[part 10 of 23: package /Cluster]
AUTOSAR XML (schema 4-3-0)
package /Cluster  (continued)
  7 x lin cluster, all with baudrate=19200, protocol-name=LIN, protocol-version=2.0:  (continued)
    Klima_LIN1
      lin physical channel CHNL: comm-connectors=CN_Klima_LIN1
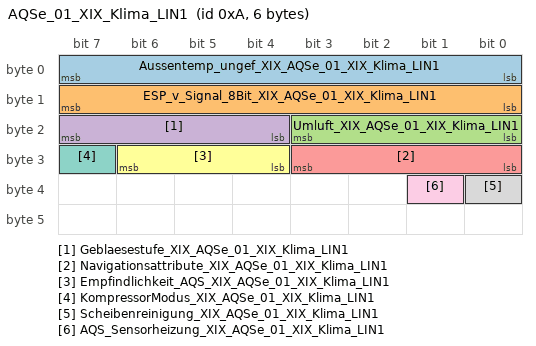
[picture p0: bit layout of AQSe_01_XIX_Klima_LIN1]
        frame AQSe_01_XIX_Klima_LIN1: id 0xA, from Klima, frame-length=6, lin-checksum=ENHANCED
          pdu AQSe_01_XIX_Klima_LIN1: length=6, unused-bit-pattern=0
            signal Aussentemp_ungef_XIX_AQSe_01_XIX_Klima_LIN1: start 0, 8 bit, little-endian, data-type-policy=OVERRIDE, i-signal-type=PRIMITIVE, init-value=254, base-type=BT_Aussentemp_ungef, compu {phys=raw*0.5-50 for raw 0..252, 253=Cxfd_nicht_verbaut (CM_Aussentemp_ungef_Cxfd_nicht_verbaut) (nicht verbaut), 254=Cxfe_Init (CM_Aussentemp_ungef_Cxfe_Init), 255=Cxff_Fehler (CM_Aussentemp_ungef_Cxff_Fehler); unit Unit_DegreCelsi}, range phys -50..76 Unit_DegreCelsi, raw 0..255, unit=Unit_DegreCelsi, transfer-property=PENDING
            signal ESP_v_Signal_8Bit_XIX_AQSe_01_XIX_Klima_LIN1: start 8, 8 bit, little-endian, data-type-policy=OVERRIDE, i-signal-type=PRIMITIVE, init-value=254, base-type=BT_ESP_v_Signal_8Bit, compu {phys=raw*2.56 for raw 0..253, 254=Cxfe_Init (CM_ESP_v_Signal_8Bit_Cxfe_Init), 255=Cxff_Fehler (CM_ESP_v_Signal_8Bit_Cxff_Fehler); unit Unit_KiloMeterPerHour}, range phys 0..647.68 Unit_KiloMeterPerHour, raw 0..255, unit=Unit_KiloMeterPerHour, transfer-property=PENDING
            signal Umluft_XIX_AQSe_01_XIX_Klima_LIN1: start 16, 4 bit, little-endian, data-type-policy=OVERRIDE, i-signal-type=PRIMITIVE, init-value=14, base-type=BT_Umluft, compu {0=Cx0_Frischluft (CM_Umluft_Cx0_Frischluft), 1=Cx1_Teilumluft_10 (CM_Umluft_Cx1_Teilumluft_10) (Teilumluft 10 %), 2=Cx2_Teilumluft_20 (CM_Umluft_Cx2_Teilumluft_20) (Teilumluft 20 %), 3=Cx3_Teilumluft_30 (CM_Umluft_Cx3_Teilumluft_30) (Teilumluft 30 %), 4=Cx4_Teilumluft_40 (CM_Umluft_Cx4_Teilumluft_40) (Teilumluft 40 %), 5=Cx5_Teilumluft_50 (CM_Umluft_Cx5_Teilumluft_50) (Teilumluft 50 %), 6=Cx6_Teilumluft_60 (CM_Umluft_Cx6_Teilumluft_60) (Teilumluft 60 %), 7=Cx7_Teilumluft_70 (CM_Umluft_Cx7_Teilumluft_70) (Teilumluft 70 %), 8=Cx8_Teilumluft_80 (CM_Umluft_Cx8_Teilumluft_80) (Teilumluft 80 %), 9=Cx9_Teilumluft_90 (CM_Umluft_Cx9_Teilumluft_90) (Teilumluft 90 %), 10=Cxa_Umluft (CM_Umluft_Cxa_Umluft), 14=Cxe_Init (CM_Umluft_Cxe_Init), 15=Cxf_Fehler (CM_Umluft_Cxf_Fehler)}, range raw 0..15, transfer-property=PENDING
            signal Geblaesestufe_XIX_AQSe_01_XIX_Klima_LIN1: start 20, 4 bit, little-endian, data-type-policy=OVERRIDE, i-signal-type=PRIMITIVE, init-value=14, base-type=BT_Geblaesestufe, compu {0=Cx0_Geblaese_aus (CM_Geblaesestufe_Cx0_Geblaese_aus) (Geblaese aus), 1=Cx1_Geblaesestufe_10 (CM_Geblaesestufe_Cx1_Geblaesestufe_10) (Geblaesestufe 10 %), 2=Cx2_Geblaesestufe_20 (CM_Geblaesestufe_Cx2_Geblaesestufe_20) (Geblaesestufe 20 %), 3=Cx3_Geblaesestufe_30 (CM_Geblaesestufe_Cx3_Geblaesestufe_30) (Geblaesestufe 30 %), 4=Cx4_Geblaesestufe_40 (CM_Geblaesestufe_Cx4_Geblaesestufe_40) (Geblaesestufe 40 %), 5=Cx5_Geblaesestufe_50 (CM_Geblaesestufe_Cx5_Geblaesestufe_50) (Geblaesestufe 50 %), 6=Cx6_Geblaesestufe_60 (CM_Geblaesestufe_Cx6_Geblaesestufe_60) (Geblaesestufe 60 %), 7=Cx7_Geblaesestufe_70 (CM_Geblaesestufe_Cx7_Geblaesestufe_70) (Geblaesestufe 70 %), 8=Cx8_Geblaesestufe_80 (CM_Geblaesestufe_Cx8_Geblaesestufe_80) (Geblaesestufe 80 %), 9=Cx9_Geblaesestufe_90 (CM_Geblaesestufe_Cx9_Geblaesestufe_90) (Geblaesestufe 90 %), 10=Cxa_Geblaesestufe_100 (CM_Geblaesestufe_Cxa_Geblaesestufe_100) (Geblaesestufe 100 %), 14=Cxe_Init (CM_Geblaesestufe_Cxe_Init), 15=Cxf_Fehler (CM_Geblaesestufe_Cxf_Fehler)}, range raw 0..15, transfer-property=PENDING
            signal Navigationsattribute_XIX_AQSe_01_XIX_Klima_LIN1: start 24, 4 bit, little-endian, data-type-policy=OVERRIDE, i-signal-type=PRIMITIVE, init-value=14, base-type=BT_Navigationsattribute, compu {1=Cx1_Tunnel_Mode (CM_Navigationsattribute_Cx1_Tunnel_Mode) (Tunnel Mode), 2=Cx2_City_Mode (CM_Navigationsattribute_Cx2_City_Mode) (City Mode), 3=Cx3_Country_Mode (CM_Navigationsattribute_Cx3_Country_Mode) (Country Mode), 4=Cx4_Highway_Mode (CM_Navigationsattribute_Cx4_Highway_Mode) (Highway Mode), 14=Cxe_Init (CM_Navigationsattribute_Cxe_Init), 15=Cxf_Ungueltig (CM_Navigationsattribute_Cxf_Ungueltig)}, range raw 1..15, transfer-property=PENDING
            signal Empfindlichkeit_AQS_XIX_AQSe_01_XIX_Klima_LIN1: start 28, 3 bit, little-endian, data-type-policy=OVERRIDE, i-signal-type=PRIMITIVE, init-value=0, base-type=BT_Empfindlichkeit_AQS, compu {0=Cx0_maximal_empfindlich (CM_Empfindlichkeit_AQS_Cx0_maximal_empfindlich) (maximal empfindlich), 1=Cx1_empfindlich (CM_Empfindlichkeit_AQS_Cx1_empfindlich), 2=Cx2_standard_empfindlich (CM_Empfindlichkeit_AQS_Cx2_standard_empfindlich) (standard empfindlich), 3=Cx3_unempfindlich (CM_Empfindlichkeit_AQS_Cx3_unempfindlich), 4=Cx4_maximal_unempfindlich (CM_Empfindlichkeit_AQS_Cx4_maximal_unempfindlich) (maximal unempfindlich)}, range raw 0..4, transfer-property=PENDING
            signal KompressorModus_XIX_AQSe_01_XIX_Klima_LIN1: start 31, 1 bit, little-endian, data-type-policy=OVERRIDE, i-signal-type=PRIMITIVE, init-value=0, base-type=BT_KompressorModus, compu {0=Cx0_Aus (CM_KompressorModus_Cx0_Aus), 1=Cx1_Ein (CM_KompressorModus_Cx1_Ein)}, range raw 0..1, transfer-property=PENDING
            signal Scheibenreinigung_XIX_AQSe_01_XIX_Klima_LIN1: start 32, 1 bit, little-endian, data-type-policy=OVERRIDE, i-signal-type=PRIMITIVE, init-value=0, base-type=BT_Scheibenreinigung, compu {0=Cx0_Aus (CM_Scheibenreinigung_Cx0_Aus), 1=Cx1_Ein (CM_Scheibenreinigung_Cx1_Ein)}, range raw 0..1, transfer-property=PENDING
            signal AQS_Sensorheizung_XIX_AQSe_01_XIX_Klima_LIN1: start 33, 1 bit, little-endian, data-type-policy=OVERRIDE, i-signal-type=PRIMITIVE, init-value=0, base-type=BT_AQS_Sensorheizung, compu {0=Cx0_keine_Freigabe (CM_AQS_Sensorheizung_Cx0_keine_Freigabe), 1=Cx1_Freigabe (CM_AQS_Sensorheizung_Cx1_Freigabe)}, range raw 0..1, transfer-property=PENDING  # Freigabe der AQS Sensorheizung
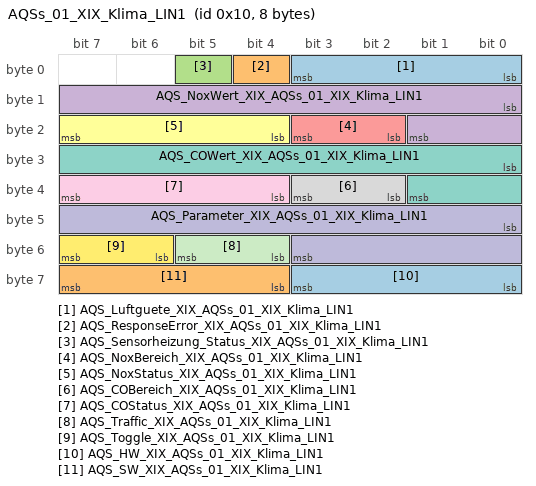
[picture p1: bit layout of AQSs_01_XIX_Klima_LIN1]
        frame AQSs_01_XIX_Klima_LIN1: id 0x10, to Klima, frame-length=8, lin-checksum=ENHANCED
          pdu AQSs_01_XIX_Klima_LIN1: length=8, unused-bit-pattern=0
            signal AQS_Luftguete_XIX_AQSs_01_XIX_Klima_LIN1: start 0, 4 bit, little-endian, data-type-policy=OVERRIDE, i-signal-type=PRIMITIVE, init-value=14, base-type=BT_AQS_Luftguete, invalid-value=Invalid_AQS_Luftguete_XIX_AQSs_01_XIX_Klima_LIN1:15, compu {0=Cx0_saubere_Luft (CM_AQS_Luftguete_Cx0_saubere_Luft) (saubere Luft), 1=Cx1_Luftguetestufe_10 (CM_AQS_Luftguete_Cx1_Luftguetestufe_10) (Luftguetestufe 10%), 2=Cx2_Luftguetestufe_20 (CM_AQS_Luftguete_Cx2_Luftguetestufe_20) (Luftguetestufe 20%), 3=Cx3_Luftguetestufe_30 (CM_AQS_Luftguete_Cx3_Luftguetestufe_30) (Luftguetestufe 30%), 4=Cx4_Luftguetestufe_40 (CM_AQS_Luftguete_Cx4_Luftguetestufe_40) (Luftguetestufe 40%), 5=Cx5_Luftguetestufe_50 (CM_AQS_Luftguete_Cx5_Luftguetestufe_50) (Luftguetestufe 50%), 6=Cx6_Luftguetestufe_60 (CM_AQS_Luftguete_Cx6_Luftguetestufe_60) (Luftguetestufe 60%), 7=Cx7_Luftguetestufe_70 (CM_AQS_Luftguete_Cx7_Luftguetestufe_70) (Luftguetestufe 70%), 8=Cx8_Luftguetestufe_80 (CM_AQS_Luftguete_Cx8_Luftguetestufe_80) (Luftguetestufe 80%), 9=Cx9_Luftguetestufe_90 (CM_AQS_Luftguete_Cx9_Luftguetestufe_90) (Luftguetestufe 90%), 10=Cxa_stark_verschmutze_Luft (CM_AQS_Luftguete_Cxa_stark_verschmutze_Luft) (stark verschmutze Luft), 13=Cxd_nicht_verbaut (CM_AQS_Luftguete_Cxd_nicht_verbaut), 14=Cxe_Init (CM_AQS_Luftguete_Cxe_Init), 15=Cxf_Fehler (CM_AQS_Luftguete_Cxf_Fehler)}, range raw 0..15, transfer-property=PENDING, to Klima(timeout 3.5 s)  # Luftguete vom AQS Nach "KL15 an", "RESET" und Start Kommunikation nach "LIN Sleepmode" wird Lufguetestufe "Init" (Wert 14) ausgegeben. Im Anschluß die Werte 0 bis 10 für normale Luftguetestufen und Wert 15 für einen erkannten Heizungsdefekt. Der kombinierte FSA-AQS-Sensor liefert "nicht_verbaut" falls der AQS-Teil im Sensor fehlt.
            signal AQS_ResponseError_XIX_AQSs_01_XIX_Klima_LIN1: start 4, 1 bit, little-endian, data-type-policy=OVERRIDE, i-signal-type=PRIMITIVE, init-value=0, base-type=BT_AQS_ResponseError, invalid-value=Invalid_AQS_ResponseError_XIX_AQSs_01_XIX_Klima_LIN1:1, compu {0=Cx0_normal (CM_AQS_ResponseError_Cx0_normal), 1=Cx1_Fehler (CM_AQS_ResponseError_Cx1_Fehler)}, range raw 0..1, transfer-property=PENDING, to Klima(timeout 3.5 s)  # siehe LIN2.0-Specification (Darf nicht über ein Fehlergueltigkeitsbit abgesichtert werden!)
            signal AQS_Sensorheizung_Status_XIX_AQSs_01_XIX_Klima_LIN1: start 5, 1 bit, little-endian, data-type-policy=OVERRIDE, i-signal-type=PRIMITIVE, init-value=0, base-type=BT_AQS_Sensorheizung_Status, compu {0=Cx0_Aus (CM_AQS_Sensorheizung_Status_Cx0_Aus), 1=Cx1_Ein (CM_AQS_Sensorheizung_Status_Cx1_Ein)}, range raw 0..1, transfer-property=PENDING, to Klima(timeout 3.5 s)  # Status der AQS Sensorheiztung
            signal AQS_NoxWert_XIX_AQSs_01_XIX_Klima_LIN1: start 8, 10 bit, little-endian, data-type-policy=OVERRIDE, i-signal-type=PRIMITIVE, init-value=0, base-type=BT_AQS_NoxWert, compu {phys=raw for raw 0..1023}, range phys 0..1023, raw 0..1023, transfer-property=PENDING, to Klima(timeout 3.5 s)  # Alle Werte möglich, auch in der INIT-Phase
            signal AQS_NoxBereich_XIX_AQSs_01_XIX_Klima_LIN1: start 18, 2 bit, little-endian, data-type-policy=OVERRIDE, i-signal-type=PRIMITIVE, init-value=0, base-type=BT_AQS_NoxBereich, compu {0=Cx0_Messbereich_0 (CM_AQS_NoxBereich_Cx0_Messbereich_0) (Messbereich 0), 1=Cx1_Messbereich_1 (CM_AQS_NoxBereich_Cx1_Messbereich_1) (Messbereich 1), 2=Cx2_Messbereich_2 (CM_AQS_NoxBereich_Cx2_Messbereich_2) (Messbereich 2), 3=Cx3_Messbereich_3 (CM_AQS_NoxBereich_Cx3_Messbereich_3) (Messbereich 3)}, range raw 0..3, transfer-property=PENDING, to Klima(timeout 3.5 s)  # Nox-Bereich (Alle Werte möglich, auch in der INIT-Phase)
            signal AQS_NoxStatus_XIX_AQSs_01_XIX_Klima_LIN1: start 20, 4 bit, little-endian, data-type-policy=OVERRIDE, i-signal-type=PRIMITIVE, init-value=0, base-type=BT_AQS_NoxStatus, compu {0=Cx0_nicht_geschaltet (CM_AQS_NoxStatus_Cx0_nicht_geschaltet) (nicht geschaltet), 1=Cx1_Luftguetestufe_1 (CM_AQS_NoxStatus_Cx1_Luftguetestufe_1) (Luftguetestufe 1), 2=Cx2_Luftguetestufe_2 (CM_AQS_NoxStatus_Cx2_Luftguetestufe_2) (Luftguetestufe 2), 3=Cx3_Luftguetestufe_3 (CM_AQS_NoxStatus_Cx3_Luftguetestufe_3) (Luftguetestufe 3), 4=Cx4_Luftguetestufe_4 (CM_AQS_NoxStatus_Cx4_Luftguetestufe_4) (Luftguetestufe 4), 5=Cx5_Luftguetestufe_5 (CM_AQS_NoxStatus_Cx5_Luftguetestufe_5) (Luftguetestufe 5), 6=Cx6_Luftguetestufe_6 (CM_AQS_NoxStatus_Cx6_Luftguetestufe_6) (Luftguetestufe 6), 7=Cx7_Luftguetestufe_7 (CM_AQS_NoxStatus_Cx7_Luftguetestufe_7) (Luftguetestufe 7), 8=Cx8_Luftguetestufe_8 (CM_AQS_NoxStatus_Cx8_Luftguetestufe_8) (Luftguetestufe 8), 9=Cx9_Luftguetestufe_9 (CM_AQS_NoxStatus_Cx9_Luftguetestufe_9) (Luftguetestufe 9), 10=Cxa_Luftguetestufe_10 (CM_AQS_NoxStatus_Cxa_Luftguetestufe_10) (Luftguetestufe 10), 15=Cxf_Luftguetestufe_ERROR (CM_AQS_NoxStatus_Cxf_Luftguetestufe_ERROR) (Luftguetestufe ERROR)}, range raw 0..15, transfer-property=PENDING, to Klima(timeout 3.5 s)  # Ist die Luftgüte "Init", ist der AQS-Nox-Status auf "nicht geschaltet" (Wert 0). Im Anschluß sind die Werte 0 bis 10 für normale Luftgütestufen in Abhänigkeit der Außenluft. Wert 15 für Nox- Sensor- Fehler ist z. Zt. nicht implementiert.
            signal AQS_COWert_XIX_AQSs_01_XIX_Klima_LIN1: start 24, 10 bit, little-endian, data-type-policy=OVERRIDE, i-signal-type=PRIMITIVE, init-value=0, base-type=BT_AQS_COWert, compu {phys=raw for raw 0..1023}, range phys 0..1023, raw 0..1023, transfer-property=PENDING, to Klima(timeout 3.5 s)  # Alle Werte möglich, auch in der INIT-Phase
            signal AQS_COBereich_XIX_AQSs_01_XIX_Klima_LIN1: start 34, 2 bit, little-endian, data-type-policy=OVERRIDE, i-signal-type=PRIMITIVE, init-value=0, base-type=BT_AQS_COBereich, compu {0=Cx0_Messbereich_0 (CM_AQS_COBereich_Cx0_Messbereich_0) (Messbereich 0), 1=Cx1_Messbereich_1 (CM_AQS_COBereich_Cx1_Messbereich_1) (Messbereich 1), 2=Cx2_Messbereich_2 (CM_AQS_COBereich_Cx2_Messbereich_2) (Messbereich 2), 3=Cx3_Messbereich_3 (CM_AQS_COBereich_Cx3_Messbereich_3) (Messbereich 3)}, range raw 0..3, transfer-property=PENDING, to Klima(timeout 3.5 s)  # CO-Messbereich AQS
            signal AQS_COStatus_XIX_AQSs_01_XIX_Klima_LIN1: start 36, 4 bit, little-endian, data-type-policy=OVERRIDE, i-signal-type=PRIMITIVE, init-value=0, base-type=BT_AQS_COStatus, invalid-value=Invalid_AQS_COStatus_XIX_AQSs_01_XIX_Klima_LIN1:15, compu {0=Cx0_nicht_geschaltet (CM_AQS_COStatus_Cx0_nicht_geschaltet) (nicht geschaltet), 1=Cx1_Luftguetestufe_1 (CM_AQS_COStatus_Cx1_Luftguetestufe_1) (Luftgütestufe 1), 2=Cx2_Luftguetestufe_2 (CM_AQS_COStatus_Cx2_Luftguetestufe_2) (Luftgütestufe 2), 3=Cx3_Luftguetestufe_3 (CM_AQS_COStatus_Cx3_Luftguetestufe_3) (Luftgütestufe 3), 4=Cx4_Luftguetestufe_4 (CM_AQS_COStatus_Cx4_Luftguetestufe_4) (Luftgütestufe 4), 5=Cx5_Luftguetestufe_5 (CM_AQS_COStatus_Cx5_Luftguetestufe_5) (Luftgütestufe 5), 6=Cx6_Luftguetestufe_6 (CM_AQS_COStatus_Cx6_Luftguetestufe_6) (Luftgütestufe 6), 7=Cx7_Luftguetestufe_7 (CM_AQS_COStatus_Cx7_Luftguetestufe_7) (Luftgütestufe 7), 8=Cx8_Luftguetestufe_8 (CM_AQS_COStatus_Cx8_Luftguetestufe_8) (Luftgütestufe 8), 9=Cx9_Luftguetestufe_9 (CM_AQS_COStatus_Cx9_Luftguetestufe_9) (Luftgütestufe 9), 10=Cxa_Luftguetestufe_10 (CM_AQS_COStatus_Cxa_Luftguetestufe_10) (Luftgütestufe 10), 15=Cxf_Fehler (CM_AQS_COStatus_Cxf_Fehler)}, range raw 0..15, transfer-property=PENDING, to Klima(timeout 3.5 s)  # Luftguetestufe
            signal AQS_Parameter_XIX_AQSs_01_XIX_Klima_LIN1: start 40, 12 bit, little-endian, data-type-policy=OVERRIDE, i-signal-type=PRIMITIVE, init-value=0, base-type=BT_AQS_Parameter, compu {phys=raw for raw 0..4095}, range phys 0..4095, raw 0..4095, transfer-property=PENDING, to Klima(timeout 3.5 s)  # Nummer des verwendeten Parametersatzes
            signal AQS_Traffic_XIX_AQSs_01_XIX_Klima_LIN1: start 52, 2 bit, little-endian, data-type-policy=OVERRIDE, i-signal-type=PRIMITIVE, init-value=0, base-type=BT_AQS_Traffic, compu {0=Cx0_unbekannt (CM_AQS_Traffic_Cx0_unbekannt), 1=Cx1_City_Mode (CM_AQS_Traffic_Cx1_City_Mode) (City Mode), 2=Cx2_Country_Mode (CM_AQS_Traffic_Cx2_Country_Mode) (Country Mode), 3=Cx3_Highway_Mode (CM_AQS_Traffic_Cx3_Highway_Mode) (Highway Mode)}, range raw 0..3, transfer-property=PENDING, to Klima(timeout 3.5 s)  # Rückgegebener Wert des Signals Navigationsattribute des Frames AQSe
            signal AQS_Toggle_XIX_AQSs_01_XIX_Klima_LIN1: start 54, 2 bit, little-endian, data-type-policy=OVERRIDE, i-signal-type=PRIMITIVE, init-value=0, base-type=BT_AQS_Toggle, transfer-property=PENDING, to Klima(timeout 3.5 s)  # Toggle wird jede Sekunde um ein Inkrement erhöht. Sequenz: 0-1-2-3-0-1-2...
            signal AQS_HW_XIX_AQSs_01_XIX_Klima_LIN1: start 56, 4 bit, little-endian, data-type-policy=OVERRIDE, i-signal-type=PRIMITIVE, init-value=0, base-type=BT_AQS_HW, compu {phys=raw for raw 0..15}, range phys 0..15, raw 0..15, transfer-property=PENDING, to Klima(timeout 3.5 s)  # Hardwarestand
            signal AQS_SW_XIX_AQSs_01_XIX_Klima_LIN1: start 60, 4 bit, little-endian, data-type-policy=OVERRIDE, i-signal-type=PRIMITIVE, init-value=0, base-type=BT_AQS_SW, compu {phys=raw for raw 0..15}, range phys 0..15, raw 0..15, transfer-property=PENDING, to Klima(timeout 3.5 s)  # Softwarestand
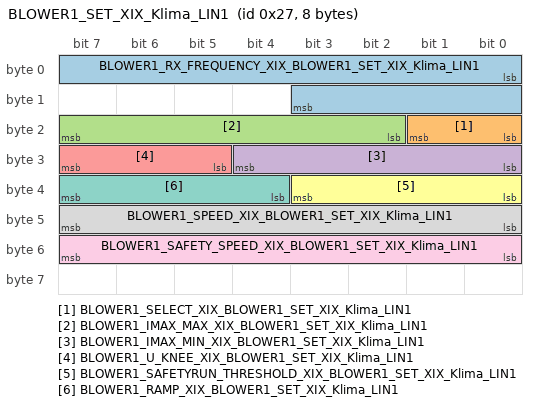
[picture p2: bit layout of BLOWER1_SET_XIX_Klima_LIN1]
        frame BLOWER1_SET_XIX_Klima_LIN1: id 0x27, from Klima, frame-length=8, lin-checksum=ENHANCED
          pdu BLOWER1_SET_XIX_Klima_LIN1: length=8, unused-bit-pattern=0
            signal BLOWER1_RX_FREQUENCY_XIX_BLOWER1_SET_XIX_Klima_LIN1: start 0, 12 bit, little-endian, data-type-policy=OVERRIDE, i-signal-type=PRIMITIVE, init-value=0, base-type=BT_BLOWER1_RX_FREQUENCY, compu {phys=raw+150 for raw 0..1896, 4095=Cxfff_ungueltig (CM_BLOWER1_RX_FREQUENCY_Cxfff_ungueltig); unit Unit_KiloHertz}, range phys 150..2046 Unit_KiloHertz, raw 0..4095, unit=Unit_KiloHertz, transfer-property=PENDING  # Radio-Empfangsfrequenz bei AM-Empfang 0..1896: Radio RX-Frequenz in kHz 150 kHz.. 2046 kHz (Offset 150 kHz) diese Frequenz Störungsfrei halten. 1897 .. 4094 rerserviert, Ersatzwert: oberste einstellbare Frequenz 4095: ungueltig, Ersatzwert: oberste einstellbare Frequenz
            signal BLOWER1_SELECT_XIX_BLOWER1_SET_XIX_Klima_LIN1: start 16, 2 bit, little-endian, data-type-policy=OVERRIDE, i-signal-type=PRIMITIVE, init-value=0, base-type=BT_BLOWER1_SELECT, compu {0=Cx0_BLOWER1 (CM_BLOWER1_SELECT_Cx0_BLOWER1), 1=Cx1_BLOWER3 (CM_BLOWER1_SELECT_Cx1_BLOWER3), 2=Cx2_reserviert (CM_BLOWER1_SELECT_Cx2_reserviert), 3=Cx3_ungueltig (CM_BLOWER1_SELECT_Cx3_ungueltig)}, range raw 0..3, transfer-property=PENDING  # 00 : Blower 1 wenn / when ID-field = 0x27 Blower 2 wenn / when ID-field = 0x3A 01 : Blower 3 wenn / when ID-field = 0x27 Blower 4 wenn/ when ID-field = 0x3A 10 : reserviert, Ersatzwert: Blower 2 11 : ungültig, Ersatzwert: Blower 2
            signal BLOWER1_IMAX_MAX_XIX_BLOWER1_SET_XIX_Klima_LIN1: start 18, 6 bit, little-endian, data-type-policy=OVERRIDE, i-signal-type=PRIMITIVE, init-value=0, base-type=BT_BLOWER1_IMAX_MAX, compu {phys=raw*0.5+8 for raw 0..62, 63=Cx3f_ungueltig (CM_BLOWER1_IMAX_MAX_Cx3f_ungueltig); unit Unit_Amper}, range phys 8..39 Unit_Amper, raw 0..63, unit=Unit_Amper, transfer-property=PENDING  # Vorgabe Maximalstrombegrenzung bei hoher Motorspannung 0.. 62 : Maximalstrom 8 A .. 39 A, Auflösung 0,5 A*inc + 8A. 63 : ungueltig Ersatzwert: niedrigster einstellbarer Wert Regler begrenzt auf Maximalwert
            signal BLOWER1_IMAX_MIN_XIX_BLOWER1_SET_XIX_Klima_LIN1: start 24, 5 bit, little-endian, data-type-policy=OVERRIDE, i-signal-type=PRIMITIVE, init-value=0, base-type=BT_BLOWER1_IMAX_MIN, compu {phys=raw*0.5+2 for raw 0..30, 31=Cx1f_ungueltig (CM_BLOWER1_IMAX_MIN_Cx1f_ungueltig); unit Unit_Amper}, range phys 2..17 Unit_Amper, raw 0..31, unit=Unit_Amper, transfer-property=PENDING  # Vorgabe Maximalstrombegrenzung bei kleiner Motorspannung (Umotor < 2 V) 0 .. 30 : Maximalstrom 2 A .. 17 A, Aufloesung 0,5 A*inc + 2 A. 31 : Ungueltig Ersatzwert: niedrigster einstellbarer Wert Der Geblaeseregler darf zu hohe oder zu kleine Vorgaben auf die applikationsspezifischen Werte begrenzen.
            signal BLOWER1_U_KNEE_XIX_BLOWER1_SET_XIX_Klima_LIN1: start 29, 3 bit, little-endian, data-type-policy=OVERRIDE, i-signal-type=PRIMITIVE, init-value=0, base-type=BT_BLOWER1_U_KNEE, compu {phys=raw*0.5+8.5 for raw 0..6, 7=Cx7_ungueltig (CM_BLOWER1_U_KNEE_Cx7_ungueltig); unit Unit_Volt}, range phys 8.5..11.5 Unit_Volt, raw 0..7, unit=Unit_Volt, transfer-property=PENDING  # Vorgabe Knickspannung Strombegrenzung 0 ¿ 6 : Knick bei Umot = 8,5 ¿ 11,5 V, Auflösung 0,5 V * inc + 8,5 V. 7 : Ungültig Ersatzwert 12.0 V Die Knickspannung wird entsprechend dem gesendeten Wert vom Regler eingestellt.
            signal BLOWER1_SAFETYRUN_THRESHOLD_XIX_BLOWER1_SET_XIX_Klima_LIN1: start 32, 4 bit, little-endian, data-type-policy=OVERRIDE, i-signal-type=PRIMITIVE, init-value=0, base-type=BT_BLOWER1_SAFETYRUN_THRESHOLD, compu {phys=raw*0.1+11.5 for raw 0..14, 15=Cxf_ungueltig (CM_BLOWER1_SAFETYRUN_THRESHOLD_Cxf_ungueltig); unit Unit_Volt}, range phys 11.5..12.9 Unit_Volt, raw 0..15, unit=Unit_Volt, transfer-property=PENDING  # Freigabe Notlauf und Schwellen 0 ... 14 : Schwelle Motor aus bei Ubatt < 11,5 V ¿ 12,9 V Auflösung 0,1 V * inc + 11,5 V 15 : Ungültig Schwelle Motor aus bei Ubatt < 13 V Entsprechend dem gesendeten Wert wird der Notlauf bei Unterschreiten der Batteriespannung abgeschaltet.
            signal BLOWER1_RAMP_XIX_BLOWER1_SET_XIX_Klima_LIN1: start 36, 4 bit, little-endian, data-type-policy=OVERRIDE, i-signal-type=PRIMITIVE, init-value=0, base-type=BT_BLOWER1_RAMP, compu {0=Cx0_0_12_V_s_Testrampe (CM_BLOWER1_RAMP_Cx0_0_12_V_s_Testrampe) (< 0,12 V / s (Testrampe)), phys=raw*0.5 for raw 1..14, 15=Cxf_ungueltig (CM_BLOWER1_RAMP_Cxf_ungueltig); unit Unit_VoltPerSecon}, range phys 0.5..7 Unit_VoltPerSecon, raw 0..15, unit=Unit_VoltPerSecon, transfer-property=PENDING  # Vorgabe Rampenzeitkonstante DUmotor / s 0 : < 0,12 V / s (Testrampe) 1 .. 14: 0,5 V / sec. bis 7 V / s Auflösung: 0,5 V / s * inc 15 : Ungültig Ersatzwert 7.5 V / s
            signal BLOWER1_SPEED_XIX_BLOWER1_SET_XIX_Klima_LIN1: start 40, 8 bit, little-endian, data-type-policy=OVERRIDE, i-signal-type=PRIMITIVE, init-value=0, base-type=BT_BLOWER1_SPEED, compu {0=Cx0_0V_Motorspannung (CM_BLOWER1_SPEED_Cx0_0V_Motorspannung) (0V Motorspannung), phys=raw*0.05+1.45 for raw 1..251, 252=Cxfc_0_V_sofort_Abschalten (CM_BLOWER1_SPEED_Cxfc_0_V_sofort_Abschalten) (0 V sofort Abschalten), 253=Cxfd_0_V_senken_mit_Rampe (CM_BLOWER1_SPEED_Cxfd_0_V_senken_mit_Rampe) (0 V senken mit Rampe), 254=Cxfe_reserviert (CM_BLOWER1_SPEED_Cxfe_reserviert), 255=Cxff_ungueltig (CM_BLOWER1_SPEED_Cxff_ungueltig); unit Unit_Volt}, range phys 1.5..14 Unit_Volt, raw 0..255, unit=Unit_Volt, transfer-property=PENDING  # Vorgabe Sollwert Motorspannung 0 : 0 V 1 ... 251: 1,5 V bis 14,0 V Auflösung: 50 mV * inc + 1,45 V 1.5 V to 14.0 V 252 : 0 V sofort Abschalten 253 : 0 V Senken mit Rampe 254 : reserviert 255 : Ungültig Sofort Abschalten Der Gebläseregler darf zu hohe oder zu kleine Vorgaben auf die spezifizierten Werte begrenzen.
            signal BLOWER1_SAFETY_SPEED_XIX_BLOWER1_SET_XIX_Klima_LIN1: start 48, 8 bit, little-endian, data-type-policy=OVERRIDE, i-signal-type=PRIMITIVE, init-value=0, base-type=BT_BLOWER1_SAFETY_SPEED, compu {phys=raw*0.05+1.5 for raw 0..250, 251=Cxfb_reserviert (CM_BLOWER1_SAFETY_SPEED_Cxfb_reserviert), 252=Cxfc_reserviert (CM_BLOWER1_SAFETY_SPEED_Cxfc_reserviert), 253=Cxfd_0_V_Notlauf_disabled_sofort_Abschalten (CM_BLOWER1_SAFETY_SPEED_Cxfd_0_V_Notlauf_disabled_sofort_Abschalten) (0 V, Notlauf disabled sofort Abschalten), 254=Cxfe_0_V_Notlauf_disabled (CM_BLOWER1_SAFETY_SPEED_Cxfe_0_V_Notlauf_disabled) (0 V, Notlauf disabled), 255=Cxff_ungueltig (CM_BLOWER1_SAFETY_SPEED_Cxff_ungueltig); unit Unit_Volt}, range phys 1.5..14 Unit_Volt, raw 0..255, unit=Unit_Volt, transfer-property=PENDING  # Vorgabe Sollwert Notlaufmotorspannung 0 ... 252: 1,5 V bis 14,0 V Notlaufmotorspannung Auflösung: 50 mV * inc + 1,5 V 253 : 0 V, Notlauf disabled sofort Abschalten 254 : 0,0 V Notlauf disabled (senken mit Rampe) 255 : Ungültig Sofort Abschalten Der gesendete Wert wird eingestellt. Der Gebläseregler darf zu hohe oder zu kleine Vorgaben auf die spezifizierten Werte begrenzen.
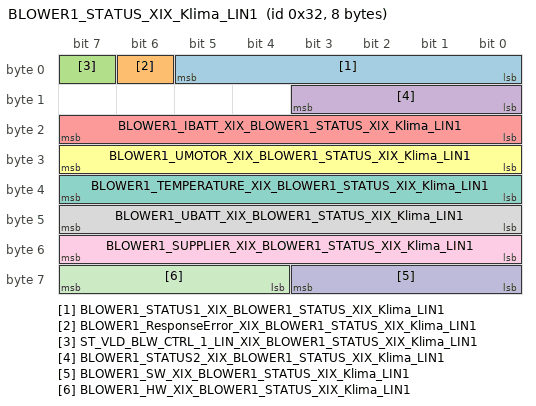
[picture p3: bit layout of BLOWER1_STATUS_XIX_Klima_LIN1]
        frame BLOWER1_STATUS_XIX_Klima_LIN1: id 0x32, to Klima, frame-length=8, lin-checksum=ENHANCED
          pdu BLOWER1_STATUS_XIX_Klima_LIN1: length=8, unused-bit-pattern=0
            signal BLOWER1_STATUS1_XIX_BLOWER1_STATUS_XIX_Klima_LIN1: start 0, 6 bit, little-endian, data-type-policy=OVERRIDE, i-signal-type=PRIMITIVE, init-value=0, base-type=BT_BLOWER1_STATUS1, compu {0=Cx0_Init (CM_BLOWER1_STATUS1_Cx0_Init), 1=Cx1_interner_Fehler_detektiert_Notabschaltung (CM_BLOWER1_STATUS1_Cx1_interner_Fehler_detektiert_Notabschaltung) (interner Fehler detektiert, Notabschaltung), 2=Cx2_Kurzschluss_oder_blockiert_Motor_aus (CM_BLOWER1_STATUS1_Cx2_Kurzschluss_oder_blockiert_Motor_aus) (Kurzschluss oder blockiert, Motor aus), 4=Cx4_uebertemperaturbegrenzung_aktiv (CM_BLOWER1_STATUS1_Cx4_uebertemperaturbegrenzung_aktiv) (Übertemperaturbegrenzung aktiv), 8=Cx8_Unterbrechung_zum_Motor_detektiert (CM_BLOWER1_STATUS1_Cx8_Unterbrechung_zum_Motor_detektiert) (Unterbrechung zum Motor detektiert), 16=Cx10_ueberspannung_Abschaltung (CM_BLOWER1_STATUS1_Cx10_ueberspannung_Abschaltung) (Überspannung Abschaltung), 32=Cx20_Unterspannung_Abschaltung (CM_BLOWER1_STATUS1_Cx20_Unterspannung_Abschaltung) (Unterspannung Abschaltung)}, range raw 0..32, transfer-property=PENDING, to Klima(timeout 3.5 s)  # Status Gebläseregler 2^0 : interner Fehler detektiert, Notabschaltung 2^1 : Kurzschluss oder blockiert, Motor aus 2^2 : Übertemperaturbegrenzung aktiv 2^3 : Unterbrechung zum Motor detektiert 2^4 : Überspannung Abschaltung 2^5 : Unterspannung Abschaltung
            signal BLOWER1_ResponseError_XIX_BLOWER1_STATUS_XIX_Klima_LIN1: start 6, 1 bit, little-endian, data-type-policy=OVERRIDE, i-signal-type=PRIMITIVE, init-value=0, base-type=BT_BLOWER1_ResponseError, invalid-value=Invalid_BLOWER1_ResponseError_XIX_BLOWER1_STATUS_XIX_Klima_LIN1:1, compu {0=Cx0_normal (CM_BLOWER1_ResponseError_Cx0_normal), 1=Cx1_Fehler (CM_BLOWER1_ResponseError_Cx1_Fehler)}, range raw 0..1, transfer-property=PENDING, to Klima(timeout 3.5 s)  # siehe LIN2.0-Specification (Darf nicht über ein Fehlergueltigkeitsbit abgesichtert werden!)
            signal ST_VLD_BLW_CTRL_1_LIN_XIX_BLOWER1_STATUS_XIX_Klima_LIN1: start 7, 1 bit, little-endian, data-type-policy=OVERRIDE, i-signal-type=PRIMITIVE, init-value=0, base-type=BT_ST_VLD_BLW_CTRL_1_LIN, compu {0=Cx0_normal (CM_ST_VLD_BLW_CTRL_1_LIN_Cx0_normal), 1=Cx1_Status1_ungueltig_ignorieren (CM_ST_VLD_BLW_CTRL_1_LIN_Cx1_Status1_ungueltig_ignorieren) (Status1_ungueltig__ignorieren)}, range raw 0..1, transfer-property=PENDING, to Klima(timeout 3.5 s)  # Status Gebläseregler: 0: normal 1: Blower Status 1 ungültig, ignorieren
            signal BLOWER1_STATUS2_XIX_BLOWER1_STATUS_XIX_Klima_LIN1: start 8, 4 bit, little-endian, data-type-policy=OVERRIDE, i-signal-type=PRIMITIVE, init-value=0, base-type=BT_BLOWER1_STATUS2, compu {0=Cx0_Init (CM_BLOWER1_STATUS2_Cx0_Init), 1=Cx1_Strombegrenzung_aktiv (CM_BLOWER1_STATUS2_Cx1_Strombegrenzung_aktiv) (Strombegrenzung aktiv), 2=Cx2_Sollwert_erreicht (CM_BLOWER1_STATUS2_Cx2_Sollwert_erreicht) (Sollwert erreicht), 4=Cx4_Notlauf_aktiviert (CM_BLOWER1_STATUS2_Cx4_Notlauf_aktiviert) (Notlauf aktiviert), 8=Cx8_Blower_Status_2_ungueltig_ignorieren (CM_BLOWER1_STATUS2_Cx8_Blower_Status_2_ungueltig_ignorieren) (Blower Status 2 ungültig, ignorieren)}, range raw 0..8, transfer-property=PENDING, to Klima(timeout 3.5 s)  # Status Gebläseregler 2^0 : Strombegrenzung aktiv 2^1 : Sollwert erreicht 2^2 : Notlauf aktiviert 2^3 : Blower Status 2 ungültig, ignorieren
            signal BLOWER1_IBATT_XIX_BLOWER1_STATUS_XIX_Klima_LIN1: start 16, 8 bit, little-endian, data-type-policy=OVERRIDE, i-signal-type=PRIMITIVE, init-value=0, base-type=BT_BLOWER1_IBATT, compu {phys=raw*0.25 for raw 0..253, 254=Cxfe_kein_Messwert_verfuegbar (CM_BLOWER1_IBATT_Cxfe_kein_Messwert_verfuegbar) (kein Messwert verfügbar), 255=Cxff_Fehler_Strommesseinrichtung (CM_BLOWER1_IBATT_Cxff_Fehler_Strommesseinrichtung) (Fehler Strommesseinrichtung); unit Unit_Amper}, range phys 0..63.25 Unit_Amper, raw 0..255, unit=Unit_Amper, transfer-property=PENDING, to Klima(timeout 3.5 s)  # Stromaufnahme Gebläseregler 0 ... 253: 0 A ... bis 63,25 A, Auflösung: 0,25 A / inc 254 : kein Messwert verfügbar 255 : Fehler Strommesseinrichtung
            signal BLOWER1_UMOTOR_XIX_BLOWER1_STATUS_XIX_Klima_LIN1: start 24, 8 bit, little-endian, data-type-policy=OVERRIDE, i-signal-type=PRIMITIVE, init-value=0, base-type=BT_BLOWER1_UMOTOR, compu {phys=raw*0.1 for raw 0..253, 254=Cxfe_kein_Messwert_verfuegbar (CM_BLOWER1_UMOTOR_Cxfe_kein_Messwert_verfuegbar), 255=Cxff_Fehler_Spannungsmesseinrichtung (CM_BLOWER1_UMOTOR_Cxff_Fehler_Spannungsmesseinrichtung); unit Unit_Volt}, range phys 0..25.3 Unit_Volt, raw 0..255, unit=Unit_Volt, transfer-property=PENDING, to Klima(timeout 3.5 s)  # Spannung am Gebläsemotor Umot 0 ... 253 : 0 V ... 25,3 V, Auflösung/Resolution: 0,1 V / inc 254 : kein Messwert verfügbar 255 : Fehler Spannungsmesseinrichtung Der Messbereich des Gebläsereglers darf kleiner 25,3 V sein. Bei Bereichsüberschreitung ist 254 zurückzumelden.
            signal BLOWER1_TEMPERATURE_XIX_BLOWER1_STATUS_XIX_Klima_LIN1: start 32, 8 bit, little-endian, data-type-policy=OVERRIDE, i-signal-type=PRIMITIVE, init-value=0, base-type=BT_BLOWER1_TEMPERATURE, compu {phys=raw-40 for raw 0..190, phys=150 for raw 191..253, 254=Cxfe_kein_Messwert_verfuegbar (CM_BLOWER1_TEMPERATURE_Cxfe_kein_Messwert_verfuegbar) (kein Messwert verfügbar), 255=Cxff_Fehler_Temperaturmesseinrichtung (CM_BLOWER1_TEMPERATURE_Cxff_Fehler_Temperaturmesseinrichtung) (Fehler Temperaturmesseinrichtung); unit Unit_DegreCelsi}, range phys -40..150 Unit_DegreCelsi, phys 150 Unit_DegreCelsi, raw 0..255, raw 191..255, unit=Unit_DegreCelsi, transfer-property=PENDING, to Klima(timeout 3.5 s)  # Temperatur Gebläseregler 0 ... 190 : -40 °C ... 150 °C, Auflösung / Resolution: 1 K / inc 191 ... 253 : 150 °C 254 : kein Messwert verfügbar 255 : Fehler Temperaturmesseinrichtung
            signal BLOWER1_UBATT_XIX_BLOWER1_STATUS_XIX_Klima_LIN1: start 40, 8 bit, little-endian, data-type-policy=OVERRIDE, i-signal-type=PRIMITIVE, init-value=0, base-type=BT_BLOWER1_UBATT, compu {phys=raw*0.1 for raw 0..253, 254=Cxfe_kein_Messwert_verfuegbar (CM_BLOWER1_UBATT_Cxfe_kein_Messwert_verfuegbar), 255=Cxff_Fehler_Spannungsmesseinrichtung (CM_BLOWER1_UBATT_Cxff_Fehler_Spannungsmesseinrichtung); unit Unit_Volt}, range phys 0..25.3 Unit_Volt, raw 0..255, unit=Unit_Volt, transfer-property=PENDING, to Klima(timeout 3.5 s)  # Spannung am Gebläseregler UBatt 0 ... 253 : 0 V ... 25,3 V, Auflösung / Resolution: 0,1 V / inc 254 : kein Messwert verfügbar 255 : Fehler Spannungsmesseinrichtung
            signal BLOWER1_SUPPLIER_XIX_BLOWER1_STATUS_XIX_Klima_LIN1: start 48, 8 bit, little-endian, data-type-policy=OVERRIDE, i-signal-type=PRIMITIVE, init-value=0, base-type=BT_BLOWER1_SUPPLIER, compu {phys=raw for raw 0..48, 64=Cx40_BOSCH (CM_BLOWER1_SUPPLIER_Cx40_BOSCH), 102=Cx66_VALEO (CM_BLOWER1_SUPPLIER_Cx66_VALEO); unit Unit_None}, range phys 0..48 Unit_None, raw 0..102, unit=Unit_None, transfer-property=PENDING, to Klima(timeout 3.5 s)  # Hersteller-Nummer 40h : BOSCH
            signal BLOWER1_SW_XIX_BLOWER1_STATUS_XIX_Klima_LIN1: start 56, 4 bit, little-endian, data-type-policy=OVERRIDE, i-signal-type=PRIMITIVE, init-value=0, base-type=BT_BLOWER1_SW, compu {phys=raw for raw 0..15; unit Unit_None}, range phys 0..15 Unit_None, raw 0..15, unit=Unit_None, transfer-property=PENDING, to Klima(timeout 3.5 s)  # Software-Version 0..F: Version 1¿16
            signal BLOWER1_HW_XIX_BLOWER1_STATUS_XIX_Klima_LIN1: start 60, 4 bit, little-endian, data-type-policy=OVERRIDE, i-signal-type=PRIMITIVE, init-value=0, base-type=BT_BLOWER1_HW, compu {phys=raw for raw 0..15; unit Unit_None}, range phys 0..15 Unit_None, raw 0..15, unit=Unit_None, transfer-property=PENDING, to Klima(timeout 3.5 s)  # Hardware-Version 0..F: Version 1¿16
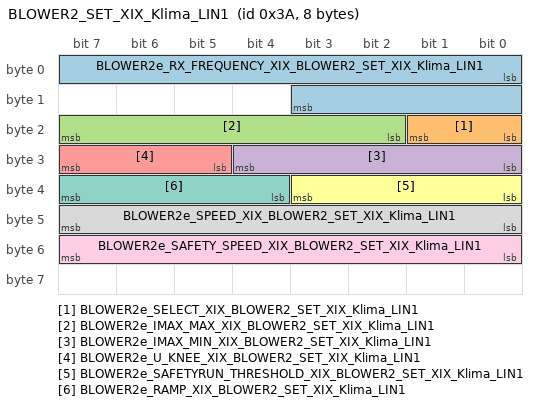
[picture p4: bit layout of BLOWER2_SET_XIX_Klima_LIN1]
        frame BLOWER2_SET_XIX_Klima_LIN1: id 0x3A, from Klima, frame-length=8, lin-checksum=ENHANCED
          pdu BLOWER2_SET_XIX_Klima_LIN1: length=8, unused-bit-pattern=0
            signal BLOWER2e_RX_FREQUENCY_XIX_BLOWER2_SET_XIX_Klima_LIN1: start 0, 12 bit, little-endian, data-type-policy=OVERRIDE, i-signal-type=PRIMITIVE, init-value=0, base-type=BT_BLOWER2e_RX_FREQUENCY, compu {phys=raw+150 for raw 0..1896, 4095=Cxfff_ungueltig (CM_BLOWER2e_RX_FREQUENCY_Cxfff_ungueltig); unit Unit_KiloHertz}, range phys 150..2046 Unit_KiloHertz, raw 0..4095, unit=Unit_KiloHertz, transfer-property=PENDING  # Radio-Empfangsfrequenz bei AM-Empfang 0..1896: Radio RX-Frequenz in kHz 150 kHz.. 2046 kHz (Offset 150 kHz) diese Frequenz Störungsfrei halten. 1897 .. 4094 rerserviert, Ersatzwert: oberste einstellbare Frequenz 4095: ungueltig, Ersatzwert: oberste einstellbare Frequenz
            signal BLOWER2e_SELECT_XIX_BLOWER2_SET_XIX_Klima_LIN1: start 16, 2 bit, little-endian, data-type-policy=OVERRIDE, i-signal-type=PRIMITIVE, init-value=0, base-type=BT_BLOWER2e_SELECT, compu {0=Cx0_BLOWER2 (CM_BLOWER2e_SELECT_Cx0_BLOWER2), 1=Cx1_BLOWER4 (CM_BLOWER2e_SELECT_Cx1_BLOWER4), 2=Cx2_reserviert (CM_BLOWER2e_SELECT_Cx2_reserviert), 3=Cx3_ungueltig (CM_BLOWER2e_SELECT_Cx3_ungueltig)}, range raw 0..3, transfer-property=PENDING  # 00 : Blower 1 wenn / when ID-field = 0x27 Blower 2 wenn / when ID-field = 0x3A 01 : Blower 3 wenn / when ID-field = 0x27 Blower 4 wenn/ when ID-field = 0x3A 10 : reserviert, Ersatzwert: Blower 2 11 : ungültig, Ersatzwert: Blower 2
            signal BLOWER2e_IMAX_MAX_XIX_BLOWER2_SET_XIX_Klima_LIN1: start 18, 6 bit, little-endian, data-type-policy=OVERRIDE, i-signal-type=PRIMITIVE, init-value=0, base-type=BT_BLOWER2e_IMAX_MAX, compu {phys=raw*0.5+8 for raw 0..62, 63=Cx3f_ungueltig (CM_BLOWER2e_IMAX_MAX_Cx3f_ungueltig); unit Unit_Amper}, range phys 8..39 Unit_Amper, raw 0..63, unit=Unit_Amper, transfer-property=PENDING  # Vorgabe Maximalstrombegrenzung bei hoher Motorspannung 0.. 62 : Maximalstrom 8 A .. 39 A, Auflösung 0,5 A*inc + 8A. 63 : ungueltig Ersatzwert: niedrigster einstellbarer Wert Regler begrenzt auf Maximalwert
            signal BLOWER2e_IMAX_MIN_XIX_BLOWER2_SET_XIX_Klima_LIN1: start 24, 5 bit, little-endian, data-type-policy=OVERRIDE, i-signal-type=PRIMITIVE, init-value=0, base-type=BT_BLOWER2e_IMAX_MIN, compu {phys=raw*0.5+2 for raw 0..30, 31=Cx1f_ungueltig (CM_BLOWER2e_IMAX_MIN_Cx1f_ungueltig); unit Unit_Amper}, range phys 2..17 Unit_Amper, raw 0..31, unit=Unit_Amper, transfer-property=PENDING  # Vorgabe Maximalstrombegrenzung bei kleiner Motorspannung (Umotor < 2 V) 0 .. 30 : Maximalstrom 2 A .. 17 A, Aufloesung 0,5 A*inc + 2 A. 31 : Ungueltig Ersatzwert: niedrigster einstellbarer Wert Der Geblaeseregler darf zu hohe oder zu kleine Vorgaben auf die applikationsspezifischen Werte begrenzen.
            signal BLOWER2e_U_KNEE_XIX_BLOWER2_SET_XIX_Klima_LIN1: start 29, 3 bit, little-endian, data-type-policy=OVERRIDE, i-signal-type=PRIMITIVE, init-value=0, base-type=BT_BLOWER2e_U_KNEE, compu {phys=raw*0.5+8.5 for raw 0..6, 7=Cx7_ungueltig (CM_BLOWER2e_U_KNEE_Cx7_ungueltig); unit Unit_Volt}, range phys 8.5..11.5 Unit_Volt, raw 0..7, unit=Unit_Volt, transfer-property=PENDING  # Vorgabe Knickspannung Strombegrenzung 0.. 6 : Knick bei Umot = 8,5.. 11,5 V, Auflösung 0,5 V * inc + 8,5 V. 7 : Ungültig Ersatzwert 12.0 V Die Knickspannung wird entsprechend dem gesendeten Wert vom Regler eingestellt.
            signal BLOWER2e_SAFETYRUN_THRESHOLD_XIX_BLOWER2_SET_XIX_Klima_LIN1: start 32, 4 bit, little-endian, data-type-policy=OVERRIDE, i-signal-type=PRIMITIVE, init-value=0, base-type=BT_BLOWER2e_SAFETYRUN_THRESHOLD, compu {phys=raw*0.1+11.5 for raw 0..14, 15=Cxf_ungueltig (CM_BLOWER2e_SAFETYRUN_THRESHOLD_Cxf_ungueltig); unit Unit_Volt}, range phys 11.5..12.9 Unit_Volt, raw 0..15, unit=Unit_Volt, transfer-property=PENDING  # Freigabe Notlauf und Schwellen 0 ... 14 : Schwelle Motor aus bei Ubatt < 11,5 V .. 12,9 V Auflösung 0,1 V * inc + 11,5 V 15 : Ungültig Schwelle Motor aus bei Ubatt < 13 V Entsprechend dem gesendeten Wert wird der Notlauf bei Unterschreiten der Batteriespannung abgeschaltet.
            signal BLOWER2e_RAMP_XIX_BLOWER2_SET_XIX_Klima_LIN1: start 36, 4 bit, little-endian, data-type-policy=OVERRIDE, i-signal-type=PRIMITIVE, init-value=0, base-type=BT_BLOWER2e_RAMP, compu {0=Cx0_kleiner_120_mV_pro_s_Testrampe (CM_BLOWER2e_RAMP_Cx0_kleiner_120_mV_pro_s_Testrampe) (kleiner_120_mV_pro_s__Testrampe), phys=raw*0.5 for raw 1..14, 15=Cxf_ungueltig (CM_BLOWER2e_RAMP_Cxf_ungueltig); unit Unit_VoltPerSecon}, range phys 0.5..7 Unit_VoltPerSecon, raw 0..15, unit=Unit_VoltPerSecon, transfer-property=PENDING  # Vorgabe Rampenzeitkonstante DUmotor / s 0 : < 0,12 V / s (Testrampe) 1 .. 14: 0,5 V / sec. bis 7 V / s Auflösung: 0,5 V / s * inc 15 : Ungültig Ersatzwert 7.5 V / s
            signal BLOWER2e_SPEED_XIX_BLOWER2_SET_XIX_Klima_LIN1: start 40, 8 bit, little-endian, data-type-policy=OVERRIDE, i-signal-type=PRIMITIVE, init-value=0, base-type=BT_BLOWER2e_SPEED, compu {0=Cx0_0V_Motorspannung (CM_BLOWER2e_SPEED_Cx0_0V_Motorspannung), phys=raw*0.05+1.45 for raw 1..251, 252=Cxfc_0V_sofort_Abschalten (CM_BLOWER2e_SPEED_Cxfc_0V_sofort_Abschalten), 253=Cxfd_0V_senken_mit_Rampe (CM_BLOWER2e_SPEED_Cxfd_0V_senken_mit_Rampe), 254=Cxfe_reserviert (CM_BLOWER2e_SPEED_Cxfe_reserviert), 255=Cxff_ungueltig (CM_BLOWER2e_SPEED_Cxff_ungueltig); unit Unit_Volt}, range phys 1.5..14 Unit_Volt, raw 0..255, unit=Unit_Volt, transfer-property=PENDING  # Vorgabe Sollwert Motorspannung 0 : 0 V 1 ... 251: 1,5 V bis 14,0 V Auflösung: 50 mV * inc + 1,45 V 1.5 V to 14.0 V 252 : 0 V sofort Abschalten 253 : 0 V Senken mit Rampe 254 : reserviert 255 : Ungültig Sofort Abschalten Der Gebläseregler darf zu hohe oder zu kleine Vorgaben auf die spezifizierten Werte begrenzen.
            signal BLOWER2e_SAFETY_SPEED_XIX_BLOWER2_SET_XIX_Klima_LIN1: start 48, 8 bit, little-endian, data-type-policy=OVERRIDE, i-signal-type=PRIMITIVE, init-value=0, base-type=BT_BLOWER2e_SAFETY_SPEED, compu {phys=raw*0.05+1.5 for raw 0..250, 251=Cxfb_reserviert (CM_BLOWER2e_SAFETY_SPEED_Cxfb_reserviert), 252=Cxfc_reserviert (CM_BLOWER2e_SAFETY_SPEED_Cxfc_reserviert), 253=Cxfd_0V_Notlauf_disabled_sofort_absch (CM_BLOWER2e_SAFETY_SPEED_Cxfd_0V_Notlauf_disabled_sofort_absch), 254=Cxfe_0V_Notlauf_disabled (CM_BLOWER2e_SAFETY_SPEED_Cxfe_0V_Notlauf_disabled), 255=Cxff_ungueltig (CM_BLOWER2e_SAFETY_SPEED_Cxff_ungueltig); unit Unit_Volt}, range phys 1.5..14 Unit_Volt, raw 0..255, unit=Unit_Volt, transfer-property=PENDING  # Vorgabe Sollwert Notlaufmotorspannung 0 ... 252: 1,5 V bis 14,0 V Notlaufmotorspannung Auflösung: 50 mV * inc + 1,5 V 253 : 0 V, Notlauf disabled sofort Abschalten 254 : 0,0 V Notlauf disabled (senken mit Rampe) 255 : Ungültig Sofort Abschalten Der gesendete Wert wird eingestellt. Der Gebläseregler darf zu hohe oder zu kleine Vorgaben auf die spezifizierten Werte begrenzen.
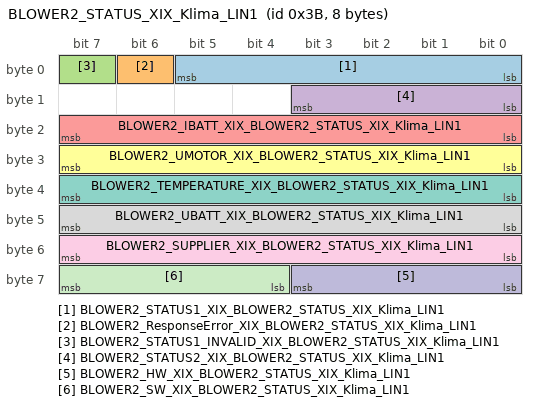
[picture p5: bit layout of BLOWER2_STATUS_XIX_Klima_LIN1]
        frame BLOWER2_STATUS_XIX_Klima_LIN1: id 0x3B, to Klima, frame-length=8, lin-checksum=ENHANCED
          pdu BLOWER2_STATUS_XIX_Klima_LIN1: length=8, unused-bit-pattern=0
            signal BLOWER2_STATUS1_XIX_BLOWER2_STATUS_XIX_Klima_LIN1: start 0, 6 bit, little-endian, data-type-policy=OVERRIDE, i-signal-type=PRIMITIVE, init-value=0, base-type=BT_BLOWER2_STATUS1, compu {0=Cx0_Init (CM_BLOWER2_STATUS1_Cx0_Init), 1=Cx1_interner_Fehler_Notabschaltung (CM_BLOWER2_STATUS1_Cx1_interner_Fehler_Notabschaltung) (interner_Fehler__Notabschaltung), 2=Cx2_Kurzschluss_blockiert_Motor_aus (CM_BLOWER2_STATUS1_Cx2_Kurzschluss_blockiert_Motor_aus) (Kurzschluss_blockiert__Motor_aus), 4=Cx4_Uebertemperaturbegrenzung_aktiv (CM_BLOWER2_STATUS1_Cx4_Uebertemperaturbegrenzung_aktiv), 8=Cx8_Unterbrechung_zum_Motor (CM_BLOWER2_STATUS1_Cx8_Unterbrechung_zum_Motor), 16=Cx10_Ueberspannung_Abschaltung (CM_BLOWER2_STATUS1_Cx10_Ueberspannung_Abschaltung), 32=Cx20_Unterspannung_Abschaltung (CM_BLOWER2_STATUS1_Cx20_Unterspannung_Abschaltung)}, range raw 0..32, transfer-property=PENDING, to Klima(timeout 3.5 s)  # Status Gebläseregler 2^0 : interner Fehler detektiert, Notabschaltung 2^1 : Kurzschluss oder blockiert, Motor aus 2^2 : Übertemperaturbegrenzung aktiv 2^3 : Unterbrechung zum Motor detektiert 2^4 : Überspannung Abschaltung 2^5 : Unterspannung Abschaltung
            signal BLOWER2_ResponseError_XIX_BLOWER2_STATUS_XIX_Klima_LIN1: start 6, 1 bit, little-endian, data-type-policy=OVERRIDE, i-signal-type=PRIMITIVE, init-value=0, base-type=BT_BLOWER2_ResponseError, invalid-value=Invalid_BLOWER2_ResponseError_XIX_BLOWER2_STATUS_XIX_Klima_LIN1:1, compu {0=Cx0_normal (CM_BLOWER2_ResponseError_Cx0_normal), 1=Cx1_Fehler (CM_BLOWER2_ResponseError_Cx1_Fehler)}, range raw 0..1, transfer-property=PENDING, to Klima(timeout 3.5 s)  # siehe LIN2.0-Specification (Darf nicht über ein Fehlergueltigkeitsbit abgesichtert werden!)
            signal BLOWER2_STATUS1_INVALID_XIX_BLOWER2_STATUS_XIX_Klima_LIN1: start 7, 1 bit, little-endian, data-type-policy=OVERRIDE, i-signal-type=PRIMITIVE, init-value=0, base-type=BT_BLOWER2_STATUS1_INVALID, compu {0=Cx0_normal (CM_BLOWER2_STATUS1_INVALID_Cx0_normal), 1=Cx1_Status1_ungueltig_ignorieren (CM_BLOWER2_STATUS1_INVALID_Cx1_Status1_ungueltig_ignorieren) (Status1_ungueltig__ignorieren)}, range raw 0..1, transfer-property=PENDING, to Klima(timeout 3.5 s)  # Status Gebläseregler: 0: normal 1: Blower Status 1 ungültig, ignorieren
            signal BLOWER2_STATUS2_XIX_BLOWER2_STATUS_XIX_Klima_LIN1: start 8, 4 bit, little-endian, data-type-policy=OVERRIDE, i-signal-type=PRIMITIVE, init-value=0, base-type=BT_BLOWER2_STATUS2, compu {0=Cx0_Init (CM_BLOWER2_STATUS2_Cx0_Init), 1=Cx1_Strombegrenzung_aktiv (CM_BLOWER2_STATUS2_Cx1_Strombegrenzung_aktiv), 2=Cx2_Sollwert_erreicht (CM_BLOWER2_STATUS2_Cx2_Sollwert_erreicht), 4=Cx4_Notlauf_aktiviert (CM_BLOWER2_STATUS2_Cx4_Notlauf_aktiviert), 8=Cx8_ungueltig_ignorieren (CM_BLOWER2_STATUS2_Cx8_ungueltig_ignorieren) (ungueltig__ignorieren)}, range raw 0..8, transfer-property=PENDING, to Klima(timeout 3.5 s)  # Status Gebläseregler 2^0 : Strombegrenzung aktiv 2^1 : Sollwert erreicht 2^2 : Notlauf aktiviert 2^3 : Blower Status 2 ungültig, ignorieren
            signal BLOWER2_IBATT_XIX_BLOWER2_STATUS_XIX_Klima_LIN1: start 16, 8 bit, little-endian, data-type-policy=OVERRIDE, i-signal-type=PRIMITIVE, init-value=0, base-type=BT_BLOWER2_IBATT, compu {phys=raw*0.25 for raw 0..253, 254=Cxfe_kein_Messwert_verfuegbar (CM_BLOWER2_IBATT_Cxfe_kein_Messwert_verfuegbar), 255=Cxff_Fehler_Strommesseinrichtung (CM_BLOWER2_IBATT_Cxff_Fehler_Strommesseinrichtung); unit Unit_Amper}, range phys 0..63.25 Unit_Amper, raw 0..255, unit=Unit_Amper, transfer-property=PENDING, to Klima(timeout 3.5 s)  # Stromaufnahme Gebläseregler 0 ... 253: 0 A ... bis 63,25 A, Auflösung: 0,25 A / inc 254 : kein Messwert verfügbar 255 : Fehler Strommesseinrichtung
            signal BLOWER2_UMOTOR_XIX_BLOWER2_STATUS_XIX_Klima_LIN1: start 24, 8 bit, little-endian, data-type-policy=OVERRIDE, i-signal-type=PRIMITIVE, init-value=0, base-type=BT_BLOWER2_UMOTOR, compu {phys=raw*0.1 for raw 0..253, 254=Cxfe_kein_Messwert_verfuegbar (CM_BLOWER2_UMOTOR_Cxfe_kein_Messwert_verfuegbar), 255=Cxff_Fehler_Spannungsmesseinrichtung (CM_BLOWER2_UMOTOR_Cxff_Fehler_Spannungsmesseinrichtung); unit Unit_Volt}, range phys 0..25.3 Unit_Volt, raw 0..255, unit=Unit_Volt, transfer-property=PENDING, to Klima(timeout 3.5 s)  # Spannung am Gebläsemotor Umot 0 ... 253 : 0 V ... 25,3 V, Auflösung/Resolution: 0,1 V / inc 254 : kein Messwert verfügbar 255 : Fehler Spannungsmesseinrichtung Der Messbereich des Gebläsereglers darf kleiner 25,3 V sein. Bei Bereichsüberschreitung ist 254 zurückzumelden.
            signal BLOWER2_TEMPERATURE_XIX_BLOWER2_STATUS_XIX_Klima_LIN1: start 32, 8 bit, little-endian, data-type-policy=OVERRIDE, i-signal-type=PRIMITIVE, init-value=0, base-type=BT_BLOWER2_TEMPERATURE, compu {phys=raw-40 for raw 0..190, 254=Cxfe_kein_Messwert_verfuegbar (CM_BLOWER2_TEMPERATURE_Cxfe_kein_Messwert_verfuegbar), 255=Cxff_Fehler_Temperaturmesseinrichtung (CM_BLOWER2_TEMPERATURE_Cxff_Fehler_Temperaturmesseinrichtung); unit Unit_DegreCelsi}, range phys -40..150 Unit_DegreCelsi, raw 0..255, unit=Unit_DegreCelsi, transfer-property=PENDING, to Klima(timeout 3.5 s)  # Temperatur Gebläseregler 0 ... 190 : -40 °C ... 150 °C, Auflösung / Resolution: 1 K / inc 191 ... 253 : 150 °C 254 : kein Messwert verfügbar 255 : Fehler Temperaturmesseinrichtung
            signal BLOWER2_UBATT_XIX_BLOWER2_STATUS_XIX_Klima_LIN1: start 40, 8 bit, little-endian, data-type-policy=OVERRIDE, i-signal-type=PRIMITIVE, init-value=254, base-type=BT_BLOWER2_UBATT, compu {phys=raw*0.1 for raw 0..253, 254=Cxfe_kein_Messwert_verfuegbar (CM_BLOWER2_UBATT_Cxfe_kein_Messwert_verfuegbar), 255=Cxff_Fehler_Spannungsmesseinrichtung (CM_BLOWER2_UBATT_Cxff_Fehler_Spannungsmesseinrichtung); unit Unit_Volt}, range phys 0..25.3 Unit_Volt, raw 0..255, unit=Unit_Volt, transfer-property=PENDING, to Klima(timeout 3.5 s)  # Spannung am Gebläseregler UBatt 0 ... 253 : 0 V ... 25,3 V, Auflösung / Resolution: 0,1 V / inc 254 : kein Messwert verfügbar 255 : Fehler Spannungsmesseinrichtung
            signal BLOWER2_SUPPLIER_XIX_BLOWER2_STATUS_XIX_Klima_LIN1: start 48, 8 bit, little-endian, data-type-policy=OVERRIDE, i-signal-type=PRIMITIVE, init-value=0, base-type=BT_BLOWER2_SUPPLIER, compu {phys=raw for raw 0..48, 64=Cx40_BOSCH (CM_BLOWER2_SUPPLIER_Cx40_BOSCH), 102=Cx66_VALEO (CM_BLOWER2_SUPPLIER_Cx66_VALEO); unit Unit_None}, range phys 0..48 Unit_None, raw 0..102, unit=Unit_None, transfer-property=PENDING, to Klima(timeout 3.5 s)  # Hersteller-Nummer 40h : BOSCH 66h : VALEO
            signal BLOWER2_HW_XIX_BLOWER2_STATUS_XIX_Klima_LIN1: start 56, 4 bit, little-endian, data-type-policy=OVERRIDE, i-signal-type=PRIMITIVE, base-type=BT_BLOWER2_HW, compu {phys=raw for raw 0..15; unit Unit_None}, range phys 0..15 Unit_None, raw 0..15, unit=Unit_None, transfer-property=PENDING, to Klima(timeout 3.5 s)  # Hardware-Version 0..F: Version 1 ...16
            signal BLOWER2_SW_XIX_BLOWER2_STATUS_XIX_Klima_LIN1: start 60, 4 bit, little-endian, data-type-policy=OVERRIDE, i-signal-type=PRIMITIVE, base-type=BT_BLOWER2_SW, compu {phys=raw for raw 0..15; unit Unit_None}, range phys 0..15 Unit_None, raw 0..15, unit=Unit_None, transfer-property=PENDING, to Klima(timeout 3.5 s)  # Software-Version 0..F: Version 1 ...16
        frame FSAe_01_XIX_Klima_LIN1: id 0x39, from Klima, frame-length=8, lin-checksum=ENHANCED
          pdu FSAe_01_XIX_Klima_LIN1: length=8, unused-bit-pattern=0
            signal MO_FSA_Sensorheizung_XIX_FSAe_01_XIX_Klima_LIN1: start 63, 1 bit, little-endian, data-type-policy=OVERRIDE, i-signal-type=PRIMITIVE, init-value=0, base-type=BT_MO_FSA_Sensorheizung, compu {0=Cx0_inaktiv (CM_MO_FSA_Sensorheizung_Cx0_inaktiv), 1=Cx1_aktiv (CM_MO_FSA_Sensorheizung_Cx1_aktiv)}, range raw 0..1, transfer-property=PENDING  # Aktivierung Sensorheizung FSA
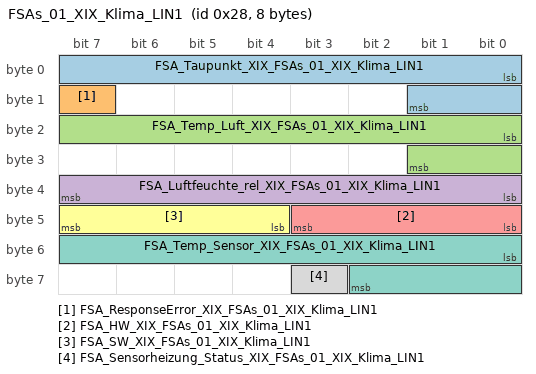
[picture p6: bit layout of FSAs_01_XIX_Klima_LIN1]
        frame FSAs_01_XIX_Klima_LIN1: id 0x28, to Klima, frame-length=8, lin-checksum=ENHANCED  # Feuchtesensor_aussen (Hat NICHT gleiche FrameID wie FSs_01)
          pdu FSAs_01_XIX_Klima_LIN1: length=8, unused-bit-pattern=0  # Feuchtesensor_aussen (Hat NICHT gleiche FrameID wie FSs_01)
            signal FSA_Taupunkt_XIX_FSAs_01_XIX_Klima_LIN1: start 0, 10 bit, little-endian, data-type-policy=OVERRIDE, i-signal-type=PRIMITIVE, init-value=1022, base-type=BT_FSA_Taupunkt, invalid-value=Invalid_FSA_Taupunkt_XIX_FSAs_01_XIX_Klima_LIN1:1023, compu {phys=raw*0.1-40 for raw 0..1000, 1021=Cx3fd_nicht_verbaut (CM_FSA_Taupunkt_Cx3fd_nicht_verbaut), 1022=Cx3fe_Init (CM_FSA_Taupunkt_Cx3fe_Init), 1023=Cx3ff_Fehler (CM_FSA_Taupunkt_Cx3ff_Fehler); unit Unit_DegreCelsi}, range phys -40..60 Unit_DegreCelsi, raw 0..1023, unit=Unit_DegreCelsi, transfer-property=PENDING, to Klima(timeout 3.5 s)  # 'Init' falls nicht verbaut
            signal FSA_ResponseError_XIX_FSAs_01_XIX_Klima_LIN1: start 15, 1 bit, little-endian, data-type-policy=OVERRIDE, i-signal-type=PRIMITIVE, init-value=0, base-type=BT_FSA_ResponseError, invalid-value=Invalid_FSA_ResponseError_XIX_FSAs_01_XIX_Klima_LIN1:1, compu {0=Cx0_normal (CM_FSA_ResponseError_Cx0_normal), 1=Cx1_Fehler (CM_FSA_ResponseError_Cx1_Fehler)}, range raw 0..1, transfer-property=PENDING, to Klima(timeout 3.5 s)  # siehe LIN2.0-Specification (Darf nicht über ein Fehlergueltigkeitsbit abgesichtert werden!)
            signal FSA_Temp_Luft_XIX_FSAs_01_XIX_Klima_LIN1: start 16, 10 bit, little-endian, data-type-policy=OVERRIDE, i-signal-type=PRIMITIVE, init-value=1022, base-type=BT_FSA_Temp_Luft, invalid-value=Invalid_FSA_Temp_Luft_XIX_FSAs_01_XIX_Klima_LIN1:1023, compu {phys=raw*0.1-40 for raw 0..1010, 1021=Cx3fd_nicht_verbaut (CM_FSA_Temp_Luft_Cx3fd_nicht_verbaut), 1022=Cx3fe_Init (CM_FSA_Temp_Luft_Cx3fe_Init), 1023=Cx3ff_Fehler (CM_FSA_Temp_Luft_Cx3ff_Fehler); unit Unit_DegreCelsi}, range phys -40..61 Unit_DegreCelsi, raw 0..1023, unit=Unit_DegreCelsi, transfer-property=PENDING, to Klima(timeout 3.5 s)  # gemessene Temperatur im Luftstrom (z.B. NTC am Sensor) 'Init' falls nicht verbaut (+61°C bedeutet: Temp_Luft > 60,9°C !)
            signal FSA_Luftfeuchte_rel_XIX_FSAs_01_XIX_Klima_LIN1: start 32, 8 bit, little-endian, data-type-policy=OVERRIDE, i-signal-type=PRIMITIVE, init-value=254, base-type=BT_FSA_Luftfeuchte_rel, invalid-value=Invalid_FSA_Luftfeuchte_rel_XIX_FSAs_01_XIX_Klima_LIN1:255, compu {phys=raw*0.5 for raw 0..252, 253=Cxfd_nicht_verbaut (CM_FSA_Luftfeuchte_rel_Cxfd_nicht_verbaut), 254=Cxfe_Init (CM_FSA_Luftfeuchte_rel_Cxfe_Init), 255=Cxff_Fehler (CM_FSA_Luftfeuchte_rel_Cxff_Fehler); unit Unit_PerCent}, range phys 0..126 Unit_PerCent, raw 0..255, unit=Unit_PerCent, transfer-property=PENDING, to Klima(timeout 3.5 s)  # Maximaler Feuchtebereich bis 126% für theoretisch errechnete Feuchtewerte des Sensors. Signalwerte >100% bedeuten rel. Feuchte = 100%
            signal FSA_HW_XIX_FSAs_01_XIX_Klima_LIN1: start 40, 4 bit, little-endian, data-type-policy=OVERRIDE, i-signal-type=PRIMITIVE, init-value=0, base-type=BT_FSA_HW, compu {phys=raw for raw 0..15}, range phys 0..15, raw 0..15, transfer-property=PENDING, to Klima(timeout 3.5 s)  # Hardwarestand
            signal FSA_SW_XIX_FSAs_01_XIX_Klima_LIN1: start 44, 4 bit, little-endian, data-type-policy=OVERRIDE, i-signal-type=PRIMITIVE, init-value=0, base-type=BT_FSA_SW, compu {phys=raw for raw 0..15}, range phys 0..15, raw 0..15, transfer-property=PENDING, to Klima(timeout 3.5 s)  # Softwarestand
            signal FSA_Temp_Sensor_XIX_FSAs_01_XIX_Klima_LIN1: start 48, 11 bit, little-endian, data-type-policy=OVERRIDE, i-signal-type=PRIMITIVE, init-value=2046, base-type=BT_FSA_Temp_Sensor, invalid-value=Invalid_FSA_Temp_Sensor_XIX_FSAs_01_XIX_Klima_LIN1:2047, compu {phys=raw*0.1-40 for raw 0..1300, 2045=Cx7fd_nicht_verbaut (CM_FSA_Temp_Sensor_Cx7fd_nicht_verbaut), 2046=Cx7fe_Init (CM_FSA_Temp_Sensor_Cx7fe_Init), 2047=Cx7ff_Fehler (CM_FSA_Temp_Sensor_Cx7ff_Fehler); unit Unit_DegreCelsi}, range phys -40..90 Unit_DegreCelsi, raw 0..2047, unit=Unit_DegreCelsi, transfer-property=PENDING, to Klima(timeout 3.5 s)
            signal FSA_Sensorheizung_Status_XIX_FSAs_01_XIX_Klima_LIN1: start 59, 1 bit, little-endian, data-type-policy=OVERRIDE, i-signal-type=PRIMITIVE, init-value=0, base-type=BT_FSA_Sensorheizung_Status, compu {0=Cx0_inaktiv (CM_FSA_Sensorheizung_Status_Cx0_inaktiv), 1=Cx1_aktiv (CM_FSA_Sensorheizung_Status_Cx1_aktiv)}, range raw 0..1, transfer-property=PENDING, to Klima(timeout 3.5 s)  # Status der Heizung im Feuchteelement (z.B. SHT10). 0 (=inaktiv) auch bei nicht verbaut
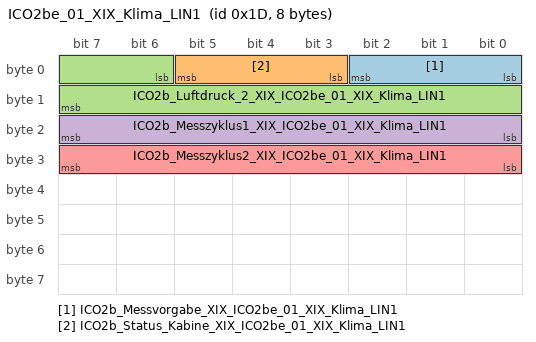
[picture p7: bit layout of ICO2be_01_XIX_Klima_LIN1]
        frame ICO2be_01_XIX_Klima_LIN1: id 0x1D, from Klima, frame-length=8, lin-checksum=ENHANCED
          pdu ICO2be_01_XIX_Klima_LIN1: length=8, unused-bit-pattern=0
            signal ICO2b_Messvorgabe_XIX_ICO2be_01_XIX_Klima_LIN1: start 0, 3 bit, little-endian, data-type-policy=OVERRIDE, i-signal-type=PRIMITIVE, init-value=0, base-type=BT_ICO2b_Messvorgabe, invalid-value=Invalid_ICO2b_Messvorgabe_XIX_ICO2be_01_XIX_Klima_LIN1:7, compu {0=Cx0_keineUeberwachung (CM_ICO2b_Messvorgabe_Cx0_keineUeberwachung), 1=Cx1_Fahrbetrieb (CM_ICO2b_Messvorgabe_Cx1_Fahrbetrieb), 2=Cx2_Parkbetrieb (CM_ICO2b_Messvorgabe_Cx2_Parkbetrieb), 7=Cx7_Fehler (CM_ICO2b_Messvorgabe_Cx7_Fehler)}, range raw 0..7, transfer-property=PENDING  # Vorgabe für die Messmethode des Sensors
            signal ICO2b_Status_Kabine_XIX_ICO2be_01_XIX_Klima_LIN1: start 3, 3 bit, little-endian, data-type-policy=OVERRIDE, i-signal-type=PRIMITIVE, init-value=0, base-type=BT_ICO2b_Status_Kabine, invalid-value=Invalid_ICO2b_Status_Kabine_XIX_ICO2be_01_XIX_Klima_LIN1:7, compu {0=Cx0_Geschlossen (CM_ICO2b_Status_Kabine_Cx0_Geschlossen), 1=Cx1_LeichtOffen (CM_ICO2b_Status_Kabine_Cx1_LeichtOffen), 2=Cx2_HalbOffen (CM_ICO2b_Status_Kabine_Cx2_HalbOffen), 3=Cx3_VollOffen (CM_ICO2b_Status_Kabine_Cx3_VollOffen), 7=Cx7_Fehler (CM_ICO2b_Status_Kabine_Cx7_Fehler)}, range raw 0..7, transfer-property=PENDING  # Einfluss von Türen, Fenster, Schiebedach, Heckdeckel auf den Auswertealgorithmus
            signal ICO2b_Luftdruck_2_XIX_ICO2be_01_XIX_Klima_LIN1: start 6, 10 bit, little-endian, data-type-policy=OVERRIDE, i-signal-type=PRIMITIVE, init-value=1022, base-type=BT_ICO2b_Luftdruck_2, invalid-value=Invalid_ICO2b_Luftdruck_2_XIX_ICO2be_01_XIX_Klima_LIN1:1023, compu {phys=raw+400 for raw 0..1000, 1021=Cx3fd_NichtVerfuegbar (CM_ICO2b_Luftdruck_2_Cx3fd_NichtVerfuegbar), 1022=Cx3fe_Init (CM_ICO2b_Luftdruck_2_Cx3fe_Init), 1023=Cx3ff_Fehler (CM_ICO2b_Luftdruck_2_Cx3ff_Fehler); unit Unit_MilliBar}, range phys 400..1400 Unit_MilliBar, raw 0..1023, unit=Unit_MilliBar, transfer-property=PENDING  # Gemessener Luftdruck in hPa bzw. mBar
            signal ICO2b_Messzyklus1_XIX_ICO2be_01_XIX_Klima_LIN1: start 16, 8 bit, little-endian, data-type-policy=OVERRIDE, i-signal-type=PRIMITIVE, init-value=0, base-type=BT_ICO2b_Messzyklus1, compu {phys=raw for raw 0..255; unit Unit_None}, range phys 0..255 Unit_None, raw 0..255, unit=Unit_None, transfer-property=PENDING  # Vorgabe des Messzyklus für Phase 1
            signal ICO2b_Messzyklus2_XIX_ICO2be_01_XIX_Klima_LIN1: start 24, 8 bit, little-endian, data-type-policy=OVERRIDE, i-signal-type=PRIMITIVE, init-value=0, base-type=BT_ICO2b_Messzyklus2, compu {phys=raw for raw 0..255}, range phys 0..255, raw 0..255, transfer-property=PENDING  # Vorgabe des Messzyklus für Phase 2
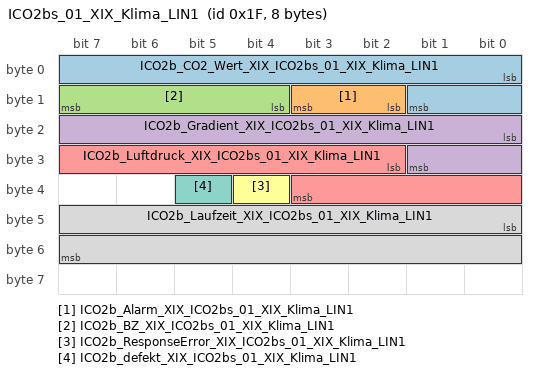
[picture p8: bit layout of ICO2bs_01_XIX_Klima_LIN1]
        frame ICO2bs_01_XIX_Klima_LIN1: id 0x1F, to Klima, frame-length=8, lin-checksum=ENHANCED
          pdu ICO2bs_01_XIX_Klima_LIN1: length=8, unused-bit-pattern=0
            signal ICO2b_CO2_Wert_XIX_ICO2bs_01_XIX_Klima_LIN1: start 0, 10 bit, little-endian, data-type-policy=OVERRIDE, i-signal-type=PRIMITIVE, init-value=1022, base-type=BT_ICO2b_CO2_Wert, invalid-value=Invalid_ICO2b_CO2_Wert_XIX_ICO2bs_01_XIX_Klima_LIN1:1023, compu {phys=raw*0.01 for raw 0..1000, 1022=Cx3fe_Init (CM_ICO2b_CO2_Wert_Cx3fe_Init), 1023=Cx3ff_Fehler (CM_ICO2b_CO2_Wert_Cx3ff_Fehler); unit Unit_None}, range phys 0..10 Unit_None, raw 0..1023, unit=Unit_None, transfer-property=PENDING, to Klima(timeout 3.5 s)  # CO2-Wert als Partialdruck in kPa gemessen
            signal ICO2b_Alarm_XIX_ICO2bs_01_XIX_Klima_LIN1: start 10, 2 bit, little-endian, data-type-policy=OVERRIDE, i-signal-type=PRIMITIVE, init-value=0, base-type=BT_ICO2b_Alarm, compu {0=Cx0_nicht_geschaltet (CM_ICO2b_Alarm_Cx0_nicht_geschaltet), 1=Cx1_Gradient (CM_ICO2b_Alarm_Cx1_Gradient), 2=Cx2_Limit (CM_ICO2b_Alarm_Cx2_Limit)}, range raw 0..2, transfer-property=PENDING, to Klima(timeout 3.5 s)  # Grund für den Alarm (Weckursache für den LIN-Master)
            signal ICO2b_BZ_XIX_ICO2bs_01_XIX_Klima_LIN1: start 12, 4 bit, little-endian, data-type-policy=OVERRIDE, i-signal-type=PRIMITIVE, base-type=BT_ICO2b_BZ, compu {phys=raw for raw 0..15}, range phys 0..15, raw 0..15, transfer-property=PENDING, to Klima(timeout 3.5 s)  # Botschaftszähler / Alive-signal
            signal ICO2b_Gradient_XIX_ICO2bs_01_XIX_Klima_LIN1: start 16, 10 bit, little-endian, data-type-policy=OVERRIDE, i-signal-type=PRIMITIVE, init-value=1022, base-type=BT_ICO2b_Gradient, invalid-value=Invalid_ICO2b_Gradient_XIX_ICO2bs_01_XIX_Klima_LIN1:1023, compu {phys=raw*100-50000 for raw 0..1000, 1022=Cx3fe_Init (CM_ICO2b_Gradient_Cx3fe_Init), 1023=Cx3ff_Fehler (CM_ICO2b_Gradient_Cx3ff_Fehler); unit Unit_None}, range phys -50000..50000 Unit_None, raw 0..1023, unit=Unit_None, transfer-property=PENDING, to Klima(timeout 3.5 s)  # CO2-Anstieg bzw. CO2-Abfall in ppm innerhalb der applizierten Zeit
            signal ICO2b_Luftdruck_XIX_ICO2bs_01_XIX_Klima_LIN1: start 26, 10 bit, little-endian, data-type-policy=OVERRIDE, i-signal-type=PRIMITIVE, init-value=1022, base-type=BT_ICO2b_Luftdruck, invalid-value=Invalid_ICO2b_Luftdruck_XIX_ICO2bs_01_XIX_Klima_LIN1:1023, compu {phys=raw+400 for raw 0..1000, 1021=Cx3fd_NichtVerfuegbar (CM_ICO2b_Luftdruck_Cx3fd_NichtVerfuegbar), 1022=Cx3fe_Init (CM_ICO2b_Luftdruck_Cx3fe_Init), 1023=Cx3ff_Fehler (CM_ICO2b_Luftdruck_Cx3ff_Fehler); unit Unit_MilliBar}, range phys 400..1400 Unit_MilliBar, raw 0..1023, unit=Unit_MilliBar, transfer-property=PENDING, to Klima(timeout 3.5 s)  # Gemessener Luftdruck in hPa bzw. mBar
            signal ICO2b_ResponseError_XIX_ICO2bs_01_XIX_Klima_LIN1: start 36, 1 bit, little-endian, data-type-policy=OVERRIDE, i-signal-type=PRIMITIVE, init-value=0, base-type=BT_ICO2b_ResponseError, invalid-value=Invalid_ICO2b_ResponseError_XIX_ICO2bs_01_XIX_Klima_LIN1:1, compu {0=Cx0_normal (CM_ICO2b_ResponseError_Cx0_normal), 1=Cx1_Fehler (CM_ICO2b_ResponseError_Cx1_Fehler)}, range raw 0..1, transfer-property=PENDING, to Klima(timeout 3.5 s)  # siehe LIN2.0-Specification
            signal ICO2b_defekt_XIX_ICO2bs_01_XIX_Klima_LIN1: start 37, 1 bit, little-endian, data-type-policy=OVERRIDE, i-signal-type=PRIMITIVE, init-value=0, base-type=BT_ICO2b_defekt, compu {0=Cx0_iO (CM_ICO2b_defekt_Cx0_iO), 1=Cx1_defekt (CM_ICO2b_defekt_Cx1_defekt)}, range raw 0..1, transfer-property=PENDING, to Klima(timeout 3.5 s)  # Sensor defekt
            signal ICO2b_Laufzeit_XIX_ICO2bs_01_XIX_Klima_LIN1: start 40, 16 bit, little-endian, data-type-policy=OVERRIDE, i-signal-type=PRIMITIVE, init-value=65534, base-type=BT_ICO2b_Laufzeit, invalid-value=Invalid_ICO2b_Laufzeit_XIX_ICO2bs_01_XIX_Klima_LIN1:65535, compu {phys=raw*10 for raw 0..65533, 65534=Cxfffe_Init (CM_ICO2b_Laufzeit_Cxfffe_Init), 65535=Cxffff_Fehler (CM_ICO2b_Laufzeit_Cxffff_Fehler); unit Unit_Secon}, range phys 0..655330 Unit_Secon, raw 0..65535, unit=Unit_Secon, transfer-property=PENDING, to Klima(timeout 3.5 s)  # Laufzeit des aktuellen bzw. letzten Überwachungsmodus
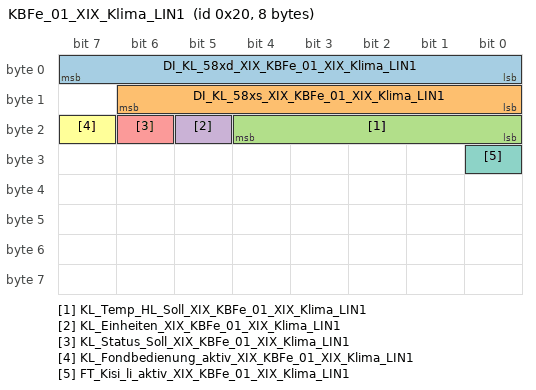
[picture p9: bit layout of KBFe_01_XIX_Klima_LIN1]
        frame KBFe_01_XIX_Klima_LIN1: id 0x20, from Klima, frame-length=8, lin-checksum=ENHANCED
          pdu KBFe_01_XIX_Klima_LIN1: length=8, unused-bit-pattern=0
            signal DI_KL_58xd_XIX_KBFe_01_XIX_Klima_LIN1: start 0, 8 bit, little-endian, data-type-policy=OVERRIDE, i-signal-type=PRIMITIVE, init-value=254, base-type=BT_DI_KL_58xd, invalid-value=Invalid_DI_KL_58xd_XIX_KBFe_01_XIX_Klima_LIN1:255, compu {phys=raw for raw 0..253, 254=Cxfe_Init (CM_DI_KL_58xd_Cxfe_Init), 255=Cxff_Fehler (CM_DI_KL_58xd_Cxff_Fehler)}, range phys 0..253, raw 0..255, transfer-property=PENDING  # Klemme 58xd Display- und Funktionsbeleuchtung Mit der Klemme 58xd wird die Helligkeit der Display- und der Funktionsbeleuchtungen der Schalter gesteuert. Im Detail beschrieben im 'Funktionslastenheft Dimmung MQB'.
            signal DI_KL_58xs_XIX_KBFe_01_XIX_Klima_LIN1: start 8, 7 bit, little-endian, data-type-policy=OVERRIDE, i-signal-type=PRIMITIVE, init-value=126, base-type=BT_DI_KL_58xs, invalid-value=Invalid_DI_KL_58xs_XIX_KBFe_01_XIX_Klima_LIN1:127, compu {phys=raw for raw 0..100, 126=Cx7e_Init (CM_DI_KL_58xs_Cx7e_Init), 127=Cx7f_Fehler (CM_DI_KL_58xs_Cx7f_Fehler); unit Unit_PerCent}, range phys 0..100 Unit_PerCent, raw 0..127, unit=Unit_PerCent, transfer-property=PENDING  # Suchbeleuchtung Schalter EIN-AUS-Schaltalgorithmus der allgemeinen Schaltersuchbeleuchtung. Im Detail beschrieben im 'Funktionslastenheft Dimmung MQB'.
            signal KL_Temp_HL_Soll_XIX_KBFe_01_XIX_Klima_LIN1: start 16, 5 bit, little-endian, data-type-policy=OVERRIDE, i-signal-type=PRIMITIVE, init-value=0, base-type=BT_KL_Temp_HL_Soll, compu {phys=raw*0.5+15.5 for raw 0..29; unit Unit_DegreCelsi}, range phys 15.5..30 Unit_DegreCelsi, raw 0..29, unit=Unit_DegreCelsi, transfer-property=PENDING  # Audi bis 28°C VW bis 29,5°C
            signal KL_Einheiten_XIX_KBFe_01_XIX_Klima_LIN1: start 21, 1 bit, little-endian, data-type-policy=OVERRIDE, i-signal-type=PRIMITIVE, init-value=0, base-type=BT_KL_Einheiten, compu {0=Cx0_C (CM_KL_Einheiten_Cx0_C) (°C), 1=Cx1_F (CM_KL_Einheiten_Cx1_F) (°F)}, range raw 0..1, transfer-property=PENDING
            signal KL_Status_Soll_XIX_KBFe_01_XIX_Klima_LIN1: start 22, 1 bit, little-endian, data-type-policy=OVERRIDE, i-signal-type=PRIMITIVE, init-value=0, base-type=BT_KL_Status_Soll, compu {0=Cx0_AUS (CM_KL_Status_Soll_Cx0_AUS), 1=Cx1_EIN (CM_KL_Status_Soll_Cx1_EIN)}, range raw 0..1, transfer-property=PENDING
            signal KL_Fondbedienung_aktiv_XIX_KBFe_01_XIX_Klima_LIN1: start 23, 1 bit, little-endian, data-type-policy=OVERRIDE, i-signal-type=PRIMITIVE, init-value=0, base-type=BT_KL_Fondbedienung_aktiv, compu {0=Cx0_nicht_aktiv (CM_KL_Fondbedienung_aktiv_Cx0_nicht_aktiv), 1=Cx1_aktiv (CM_KL_Fondbedienung_aktiv_Cx1_aktiv)}, range raw 0..1, transfer-property=PENDING
            signal FT_Kisi_li_aktiv_XIX_KBFe_01_XIX_Klima_LIN1: start 24, 1 bit, little-endian, data-type-policy=OVERRIDE, i-signal-type=PRIMITIVE, init-value=0, base-type=BT_FT_Kisi_li_aktiv, compu {0=Cx0_inaktiv (CM_FT_Kisi_li_aktiv_Cx0_inaktiv), 1=Cx1_aktiv (CM_FT_Kisi_li_aktiv_Cx1_aktiv)}, range raw 0..1, transfer-property=PENDING  # Aktivierungsstatus der Kindersicherung links
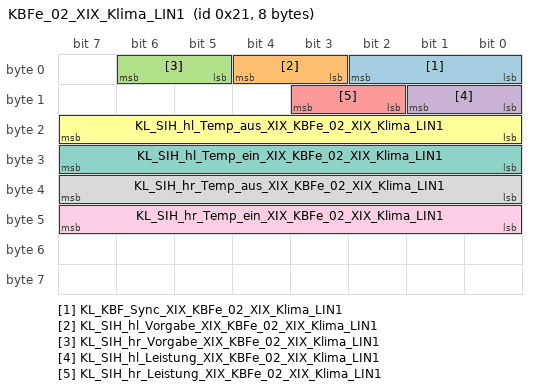
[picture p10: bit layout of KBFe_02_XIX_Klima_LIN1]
        frame KBFe_02_XIX_Klima_LIN1: id 0x21, from Klima, frame-length=8, lin-checksum=ENHANCED
          pdu KBFe_02_XIX_Klima_LIN1: length=8, unused-bit-pattern=0
            signal KL_KBF_Sync_XIX_KBFe_02_XIX_Klima_LIN1: start 0, 3 bit, little-endian, data-type-policy=OVERRIDE, i-signal-type=PRIMITIVE, init-value=0, base-type=BT_KL_KBF_Sync, compu {0=Cx0_keine_Aktion (CM_KL_KBF_Sync_Cx0_keine_Aktion), 1=Cx1_Sollwert_Temperatur_uebernehmen (CM_KL_KBF_Sync_Cx1_Sollwert_Temperatur_uebernehmen), 2=Cx2_Sollwert_SIH_li_uebernehmen (CM_KL_KBF_Sync_Cx2_Sollwert_SIH_li_uebernehmen), 4=Cx4_Sollwert_SIH_re_uebernehmen (CM_KL_KBF_Sync_Cx4_Sollwert_SIH_re_uebernehmen)}, range raw 0..4, transfer-property=PENDING  # Trigger für Sollwertübernahme bei Remotebedienung bzw. Stellgliedtest (bitcodiert)
            signal KL_SIH_hl_Vorgabe_XIX_KBFe_02_XIX_Klima_LIN1: start 3, 2 bit, little-endian, data-type-policy=OVERRIDE, i-signal-type=PRIMITIVE, base-type=BT_KL_SIH_hl_Vorgabe, compu {0=Cx0_Aus (CM_KL_SIH_hl_Vorgabe_Cx0_Aus), 1=Cx1_Stufe1 (CM_KL_SIH_hl_Vorgabe_Cx1_Stufe1), 2=Cx2_Stufe2 (CM_KL_SIH_hl_Vorgabe_Cx2_Stufe2), 3=Cx3_Stufe3 (CM_KL_SIH_hl_Vorgabe_Cx3_Stufe3)}, range raw 0..3, transfer-property=PENDING  # Vorgabe des Sitzheizung hinten links über Fondraumbedienung bzw. Personalisierung
            signal KL_SIH_hr_Vorgabe_XIX_KBFe_02_XIX_Klima_LIN1: start 5, 2 bit, little-endian, data-type-policy=OVERRIDE, i-signal-type=PRIMITIVE, base-type=BT_KL_SIH_hr_Vorgabe, compu {0=Cx0_Aus (CM_KL_SIH_hr_Vorgabe_Cx0_Aus), 1=Cx1_Stufe1 (CM_KL_SIH_hr_Vorgabe_Cx1_Stufe1), 2=Cx2_Stufe2 (CM_KL_SIH_hr_Vorgabe_Cx2_Stufe2), 3=Cx3_Stufe3 (CM_KL_SIH_hr_Vorgabe_Cx3_Stufe3)}, range raw 0..3, transfer-property=PENDING  # Vorgabe des Sitzheizung hinten rechts über Fondraumbedienung bzw. Personalisierung
            signal KL_SIH_hl_Leistung_XIX_KBFe_02_XIX_Klima_LIN1: start 8, 2 bit, little-endian, data-type-policy=OVERRIDE, i-signal-type=PRIMITIVE, base-type=BT_KL_SIH_hl_Leistung, compu {0=Cx0_Aus (CM_KL_SIH_hl_Leistung_Cx0_Aus), 1=Cx1_33 (CM_KL_SIH_hl_Leistung_Cx1_33) (33%), 2=Cx2_66 (CM_KL_SIH_hl_Leistung_Cx2_66) (66%), 3=Cx3_100 (CM_KL_SIH_hl_Leistung_Cx3_100) (100%)}, range raw 0..3, transfer-property=PENDING  # Leistungskontingentierung für SIH hinten links aus Energiemanagement
            signal KL_SIH_hr_Leistung_XIX_KBFe_02_XIX_Klima_LIN1: start 10, 2 bit, little-endian, data-type-policy=OVERRIDE, i-signal-type=PRIMITIVE, base-type=BT_KL_SIH_hr_Leistung, compu {0=Cx0_Aus (CM_KL_SIH_hr_Leistung_Cx0_Aus), 1=Cx1_33 (CM_KL_SIH_hr_Leistung_Cx1_33) (33%), 2=Cx2_66 (CM_KL_SIH_hr_Leistung_Cx2_66) (66%), 3=Cx3_100 (CM_KL_SIH_hr_Leistung_Cx3_100) (100%)}, range raw 0..3, transfer-property=PENDING  # Leistungskontingentierung für SIH hinten rechts aus Energiemanagement
            signal KL_SIH_hl_Temp_aus_XIX_KBFe_02_XIX_Klima_LIN1: start 16, 8 bit, little-endian, data-type-policy=OVERRIDE, i-signal-type=PRIMITIVE, init-value=254, base-type=BT_KL_SIH_hl_Temp_aus, invalid-value=Invalid_KL_SIH_hl_Temp_aus_XIX_KBFe_02_XIX_Klima_LIN1:255, compu {phys=raw*0.25+15 for raw 0..253, 254=Cxfe_Init (CM_KL_SIH_hl_Temp_aus_Cxfe_Init), 255=Cxff_Fehler (CM_KL_SIH_hl_Temp_aus_Cxff_Fehler); unit Unit_DegreCelsi}, range phys 15..78.25 Unit_DegreCelsi, raw 0..255, unit=Unit_DegreCelsi, transfer-property=PENDING  # Ausschalttemperatur für SIH hinten links je nach gewählter Stufe
            signal KL_SIH_hl_Temp_ein_XIX_KBFe_02_XIX_Klima_LIN1: start 24, 8 bit, little-endian, data-type-policy=OVERRIDE, i-signal-type=PRIMITIVE, init-value=254, base-type=BT_KL_SIH_hl_Temp_ein, invalid-value=Invalid_KL_SIH_hl_Temp_ein_XIX_KBFe_02_XIX_Klima_LIN1:255, compu {phys=raw*0.25+15 for raw 0..253, 254=Cxfe_Init (CM_KL_SIH_hl_Temp_ein_Cxfe_Init), 255=Cxff_Fehler (CM_KL_SIH_hl_Temp_ein_Cxff_Fehler); unit Unit_DegreCelsi}, range phys 15..78.25 Unit_DegreCelsi, raw 0..255, unit=Unit_DegreCelsi, transfer-property=PENDING  # Einschalttemperatur für SIH hinten links je nach gewählter Stufe
            signal KL_SIH_hr_Temp_aus_XIX_KBFe_02_XIX_Klima_LIN1: start 32, 8 bit, little-endian, data-type-policy=OVERRIDE, i-signal-type=PRIMITIVE, init-value=254, base-type=BT_KL_SIH_hr_Temp_aus, invalid-value=Invalid_KL_SIH_hr_Temp_aus_XIX_KBFe_02_XIX_Klima_LIN1:255, compu {phys=raw*0.25+15 for raw 0..253, 254=Cxfe_Init (CM_KL_SIH_hr_Temp_aus_Cxfe_Init), 255=Cxff_Fehler (CM_KL_SIH_hr_Temp_aus_Cxff_Fehler); unit Unit_DegreCelsi}, range phys 15..78.25 Unit_DegreCelsi, raw 0..255, unit=Unit_DegreCelsi, transfer-property=PENDING  # Ausschalttemperatur für SIH hinten links je nach gewählter Stufe
            signal KL_SIH_hr_Temp_ein_XIX_KBFe_02_XIX_Klima_LIN1: start 40, 8 bit, little-endian, data-type-policy=OVERRIDE, i-signal-type=PRIMITIVE, init-value=254, base-type=BT_KL_SIH_hr_Temp_ein, invalid-value=Invalid_KL_SIH_hr_Temp_ein_XIX_KBFe_02_XIX_Klima_LIN1:255, compu {phys=raw*0.25+15 for raw 0..253, 254=Cxfe_Init (CM_KL_SIH_hr_Temp_ein_Cxfe_Init), 255=Cxff_Fehler (CM_KL_SIH_hr_Temp_ein_Cxff_Fehler); unit Unit_DegreCelsi}, range phys 15..78.25 Unit_DegreCelsi, raw 0..255, unit=Unit_DegreCelsi, transfer-property=PENDING  # Einschalttemperatur für SIH hinten rechts je nach gewählter Stufe
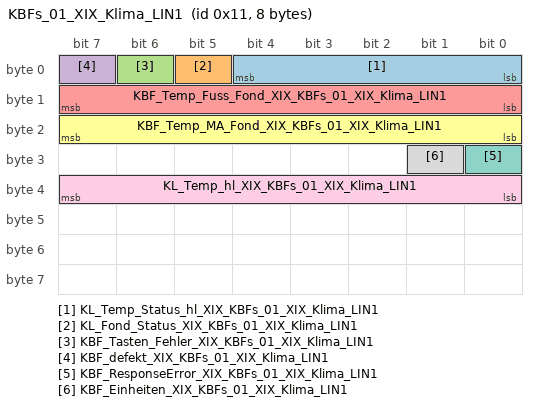
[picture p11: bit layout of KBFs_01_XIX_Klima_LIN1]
        frame KBFs_01_XIX_Klima_LIN1: id 0x11, to Klima, frame-length=8, lin-checksum=ENHANCED
          pdu KBFs_01_XIX_Klima_LIN1: length=8, unused-bit-pattern=0
            signal KL_Temp_Status_hl_XIX_KBFs_01_XIX_Klima_LIN1: start 0, 5 bit, little-endian, data-type-policy=OVERRIDE, i-signal-type=PRIMITIVE, init-value=0, base-type=BT_KL_Temp_Status_hl, compu {phys=raw*0.5+15.5 for raw 0..29; unit Unit_DegreCelsi}, range phys 15.5..30 Unit_DegreCelsi, raw 0..29, unit=Unit_DegreCelsi, transfer-property=PENDING, to Klima(timeout 3.5 s)  # Status Temperatur hinten links (LO - HI) Audi bis 28°C VW bis 29,5°C
            signal KL_Fond_Status_XIX_KBFs_01_XIX_Klima_LIN1: start 5, 1 bit, little-endian, data-type-policy=OVERRIDE, i-signal-type=PRIMITIVE, init-value=0, base-type=BT_KL_Fond_Status, compu {0=Cx0_aus (CM_KL_Fond_Status_Cx0_aus), 1=Cx1_ein (CM_KL_Fond_Status_Cx1_ein)}, range raw 0..1, transfer-property=PENDING, to Klima(timeout 3.5 s)  # Status Klima_Fond
            signal KBF_Tasten_Fehler_XIX_KBFs_01_XIX_Klima_LIN1: start 6, 1 bit, little-endian, data-type-policy=OVERRIDE, i-signal-type=PRIMITIVE, init-value=0, base-type=BT_KBF_Tasten_Fehler, invalid-value=Invalid_KBF_Tasten_Fehler_XIX_KBFs_01_XIX_Klima_LIN1:1, compu {0=Cx0_kein_Fehler (CM_KBF_Tasten_Fehler_Cx0_kein_Fehler), 1=Cx1_Fehler (CM_KBF_Tasten_Fehler_Cx1_Fehler)}, range raw 0..1, transfer-property=PENDING, to Klima(timeout 3.5 s)  # Tastendiagnose
            signal KBF_defekt_XIX_KBFs_01_XIX_Klima_LIN1: start 7, 1 bit, little-endian, data-type-policy=OVERRIDE, i-signal-type=PRIMITIVE, init-value=0, base-type=BT_KBF_defekt, invalid-value=Invalid_KBF_defekt_XIX_KBFs_01_XIX_Klima_LIN1:1, compu {0=Cx0_kein_Fehler (CM_KBF_defekt_Cx0_kein_Fehler), 1=Cx1_Fehler (CM_KBF_defekt_Cx1_Fehler)}, range raw 0..1, transfer-property=PENDING, to Klima(timeout 3.5 s)  # Steuergerät defekt
            signal KBF_Temp_Fuss_Fond_XIX_KBFs_01_XIX_Klima_LIN1: start 8, 8 bit, little-endian, data-type-policy=OVERRIDE, i-signal-type=PRIMITIVE, init-value=254, base-type=BT_KBF_Temp_Fuss_Fond, invalid-value=Invalid_KBF_Temp_Fuss_Fond_XIX_KBFs_01_XIX_Klima_LIN1:255, compu {phys=raw*0.5-40 for raw 0..250, 254=Cxfe_Init (CM_KBF_Temp_Fuss_Fond_Cxfe_Init), 255=Cxff_Fehler (CM_KBF_Temp_Fuss_Fond_Cxff_Fehler); unit Unit_DegreCelsi}, range phys -40..85 Unit_DegreCelsi, raw 0..255, unit=Unit_DegreCelsi, transfer-property=PENDING, to Klima(timeout 3.5 s)  # Temperaturfühler Fond Fußraum
            signal KBF_Temp_MA_Fond_XIX_KBFs_01_XIX_Klima_LIN1: start 16, 8 bit, little-endian, data-type-policy=OVERRIDE, i-signal-type=PRIMITIVE, init-value=254, base-type=BT_KBF_Temp_MA_Fond, invalid-value=Invalid_KBF_Temp_MA_Fond_XIX_KBFs_01_XIX_Klima_LIN1:255, compu {phys=raw*0.5-40 for raw 0..250, 254=Cxfe_Init (CM_KBF_Temp_MA_Fond_Cxfe_Init), 255=Cxff_Fehler (CM_KBF_Temp_MA_Fond_Cxff_Fehler); unit Unit_DegreCelsi}, range phys -40..85 Unit_DegreCelsi, raw 0..255, unit=Unit_DegreCelsi, transfer-property=PENDING, to Klima(timeout 3.5 s)  # Temperaturfuehler Fond Mannanstroemer
            signal KBF_ResponseError_XIX_KBFs_01_XIX_Klima_LIN1: start 24, 1 bit, little-endian, data-type-policy=OVERRIDE, i-signal-type=PRIMITIVE, init-value=0, base-type=BT_KBF_ResponseError, invalid-value=Invalid_KBF_ResponseError_XIX_KBFs_01_XIX_Klima_LIN1:1, compu {0=Cx0_normal (CM_KBF_ResponseError_Cx0_normal), 1=Cx1_Fehler (CM_KBF_ResponseError_Cx1_Fehler)}, range raw 0..1, transfer-property=PENDING, to Klima(timeout 3.5 s)  # siehe LIN2.0-Specification (Darf nicht über ein Fehlergueltigkeitsbit abgesichtert werden!)
            signal KBF_Einheiten_XIX_KBFs_01_XIX_Klima_LIN1: start 25, 1 bit, little-endian, data-type-policy=OVERRIDE, i-signal-type=PRIMITIVE, base-type=BT_KBF_Einheiten, compu {0=Cx0_C (CM_KBF_Einheiten_Cx0_C) (°C), 1=Cx1_F (CM_KBF_Einheiten_Cx1_F) (°F)}, range raw 0..1, transfer-property=PENDING, to Klima(timeout 3.5 s)  # angezeigte Einheiten
            signal KL_Temp_hl_XIX_KBFs_01_XIX_Klima_LIN1: start 32, 8 bit, little-endian, data-type-policy=OVERRIDE, i-signal-type=PRIMITIVE, init-value=254, base-type=BT_KL_Temp_hl, compu {phys=raw*0.5 for raw 0..200, 254=Cxfe_Init (CM_KL_Temp_hl_Cxfe_Init); unit Unit_PerCent}, range phys 0..100 Unit_PerCent, raw 0..254, unit=Unit_PerCent, transfer-property=PENDING, to Klima(timeout 3.5 s)  # Sollwert für Temperaturklappe hinten links
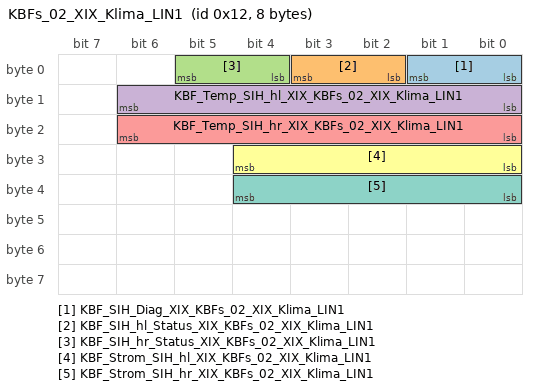
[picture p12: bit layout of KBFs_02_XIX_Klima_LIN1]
        frame KBFs_02_XIX_Klima_LIN1: id 0x12, to Klima, frame-length=8, lin-checksum=ENHANCED
          pdu KBFs_02_XIX_Klima_LIN1: length=8, unused-bit-pattern=0
            signal KBF_SIH_Diag_XIX_KBFs_02_XIX_Klima_LIN1: start 0, 2 bit, little-endian, data-type-policy=OVERRIDE, i-signal-type=PRIMITIVE, base-type=BT_KBF_SIH_Diag, compu {0=Cx0_Aus (CM_KBF_SIH_Diag_Cx0_Aus), 1=Cx1_SIH_hl_defekt (CM_KBF_SIH_Diag_Cx1_SIH_hl_defekt), 2=Cx2_SIH_hr_defekt (CM_KBF_SIH_Diag_Cx2_SIH_hr_defekt), 3=Cx3_SIH_hl_hr_defekt (CM_KBF_SIH_Diag_Cx3_SIH_hl_hr_defekt)}, range raw 0..3, transfer-property=PENDING, to Klima(timeout 3.5 s)  # Sitzheizungsdiagnose
            signal KBF_SIH_hl_Status_XIX_KBFs_02_XIX_Klima_LIN1: start 2, 2 bit, little-endian, data-type-policy=OVERRIDE, i-signal-type=PRIMITIVE, base-type=BT_KBF_SIH_hl_Status, compu {0=Cx0_Aus (CM_KBF_SIH_hl_Status_Cx0_Aus), 1=Cx1_Stufe1 (CM_KBF_SIH_hl_Status_Cx1_Stufe1), 2=Cx2_Stufe2 (CM_KBF_SIH_hl_Status_Cx2_Stufe2), 3=Cx3_Stufe3 (CM_KBF_SIH_hl_Status_Cx3_Stufe3)}, range raw 0..3, transfer-property=PENDING, to Klima(timeout 3.5 s)  # Aktuell gewählte und angezeigte Sitzheizungsstufe hinten links
            signal KBF_SIH_hr_Status_XIX_KBFs_02_XIX_Klima_LIN1: start 4, 2 bit, little-endian, data-type-policy=OVERRIDE, i-signal-type=PRIMITIVE, base-type=BT_KBF_SIH_hr_Status, compu {0=Cx0_Aus (CM_KBF_SIH_hr_Status_Cx0_Aus), 1=Cx1_Stufe1 (CM_KBF_SIH_hr_Status_Cx1_Stufe1), 2=Cx2_Stufe2 (CM_KBF_SIH_hr_Status_Cx2_Stufe2), 3=Cx3_Stufe3 (CM_KBF_SIH_hr_Status_Cx3_Stufe3)}, range raw 0..3, transfer-property=PENDING, to Klima(timeout 3.5 s)  # Aktuell gewählte und angezeigte Sitzheizungsstufe hinten rechts
            signal KBF_Temp_SIH_hl_XIX_KBFs_02_XIX_Klima_LIN1: start 8, 7 bit, little-endian, data-type-policy=OVERRIDE, i-signal-type=PRIMITIVE, init-value=126, base-type=BT_KBF_Temp_SIH_hl, invalid-value=Invalid_KBF_Temp_SIH_hl_XIX_KBFs_02_XIX_Klima_LIN1:127, compu {phys=raw*0.5+15 for raw 0..125, 126=Cx7e_Init (CM_KBF_Temp_SIH_hl_Cx7e_Init), 127=Cx7f_Fehler (CM_KBF_Temp_SIH_hl_Cx7f_Fehler); unit Unit_DegreCelsi}, range phys 15..77.5 Unit_DegreCelsi, raw 0..127, unit=Unit_DegreCelsi, transfer-property=PENDING, to Klima(timeout 3.5 s)  # Temperaturfühler Sitzheizung Fond links
            signal KBF_Temp_SIH_hr_XIX_KBFs_02_XIX_Klima_LIN1: start 16, 7 bit, little-endian, data-type-policy=OVERRIDE, i-signal-type=PRIMITIVE, init-value=126, base-type=BT_KBF_Temp_SIH_hr, invalid-value=Invalid_KBF_Temp_SIH_hr_XIX_KBFs_02_XIX_Klima_LIN1:127, compu {phys=raw*0.5+15 for raw 0..125, 126=Cx7e_Init (CM_KBF_Temp_SIH_hr_Cx7e_Init), 127=Cx7f_Fehler (CM_KBF_Temp_SIH_hr_Cx7f_Fehler); unit Unit_DegreCelsi}, range phys 15..77.5 Unit_DegreCelsi, raw 0..127, unit=Unit_DegreCelsi, transfer-property=PENDING, to Klima(timeout 3.5 s)  # Temperaturfühler Sitzheizung Fond rechts
            signal KBF_Strom_SIH_hl_XIX_KBFs_02_XIX_Klima_LIN1: start 24, 5 bit, little-endian, data-type-policy=OVERRIDE, i-signal-type=PRIMITIVE, init-value=0, base-type=BT_KBF_Strom_SIH_hl, invalid-value=Invalid_KBF_Strom_SIH_hl_XIX_KBFs_02_XIX_Klima_LIN1:31, compu {0=Cx0_Init (CM_KBF_Strom_SIH_hl_Cx0_Init), phys=raw for raw 1..30, 31=Cx1f_Fehler (CM_KBF_Strom_SIH_hl_Cx1f_Fehler); unit Unit_Amper}, range phys 1..30 Unit_Amper, raw 0..31, unit=Unit_Amper, transfer-property=PENDING, to Klima(timeout 3.5 s)  # Stromaufnahme der Sitzheizung Fond links
            signal KBF_Strom_SIH_hr_XIX_KBFs_02_XIX_Klima_LIN1: start 32, 5 bit, little-endian, data-type-policy=OVERRIDE, i-signal-type=PRIMITIVE, init-value=0, base-type=BT_KBF_Strom_SIH_hr, invalid-value=Invalid_KBF_Strom_SIH_hr_XIX_KBFs_02_XIX_Klima_LIN1:31, compu {0=Cx0_Init (CM_KBF_Strom_SIH_hr_Cx0_Init), phys=raw for raw 1..30, 31=Cx1f_Fehler (CM_KBF_Strom_SIH_hr_Cx1f_Fehler); unit Unit_Amper}, range phys 1..30 Unit_Amper, raw 0..31, unit=Unit_Amper, transfer-property=PENDING, to Klima(timeout 3.5 s)  # Stromaufnahme der Sitzheizung Fond rechts
        frame KPVe_01_XIX_Klima_LIN1: id 0x9, from Klima, frame-length=8, lin-checksum=ENHANCED  # Kopie KPVe_01 mit geänderter Frame-ID wegen ID-Kollision auf Klima_LIN1
          pdu KPVe_01_XIX_Klima_LIN1: length=8, unused-bit-pattern=0  # Kopie KPVe_01 mit geänderter Frame-ID wegen ID-Kollision auf Klima_LIN1
            signal KPVe_Funktion_Off_XIX_KPVe_01_XIX_Klima_LIN1: start 0, 1 bit, little-endian, data-type-policy=OVERRIDE, i-signal-type=PRIMITIVE, init-value=0, base-type=BT_KPVe_Funktion_Off, compu {0=Cx0_inaktiv (CM_KPVe_Funktion_Off_Cx0_inaktiv), 1=Cx1_aktiv (CM_KPVe_Funktion_Off_Cx1_aktiv)}, range raw 0..1, transfer-property=PENDING  # Status für Funktion Off am Klimapanel
            signal KPVe_Funktion_Defrost_XIX_KPVe_01_XIX_Klima_LIN1: start 1, 1 bit, little-endian, data-type-policy=OVERRIDE, i-signal-type=PRIMITIVE, init-value=0, base-type=BT_KPVe_Funktion_Defrost, compu {0=Cx0_inaktiv (CM_KPVe_Funktion_Defrost_Cx0_inaktiv), 1=Cx1_aktiv (CM_KPVe_Funktion_Defrost_Cx1_aktiv)}, range raw 0..1, transfer-property=PENDING  # Status für Funktion Defrost am Klimapanel
            signal KPVe_Funktion_Umluft_XIX_KPVe_01_XIX_Klima_LIN1: start 2, 1 bit, little-endian, data-type-policy=OVERRIDE, i-signal-type=PRIMITIVE, init-value=0, base-type=BT_KPVe_Funktion_Umluft, compu {0=Cx0_inaktiv (CM_KPVe_Funktion_Umluft_Cx0_inaktiv), 1=Cx1_aktiv (CM_KPVe_Funktion_Umluft_Cx1_aktiv)}, range raw 0..1, transfer-property=PENDING  # Status für Funktion Umluft am Klimapanel
            signal KPVe_Funktion_AC_XIX_KPVe_01_XIX_Klima_LIN1: start 3, 1 bit, little-endian, data-type-policy=OVERRIDE, i-signal-type=PRIMITIVE, init-value=0, base-type=BT_KPVe_Funktion_AC, compu {0=Cx0_inaktiv (CM_KPVe_Funktion_AC_Cx0_inaktiv), 1=Cx1_aktiv (CM_KPVe_Funktion_AC_Cx1_aktiv)}, range raw 0..1, transfer-property=PENDING  # Status für Funktion AC am Klimapanel
            signal KPVe_Funktion_AC_max_XIX_KPVe_01_XIX_Klima_LIN1: start 4, 1 bit, little-endian, data-type-policy=OVERRIDE, i-signal-type=PRIMITIVE, init-value=0, base-type=BT_KPVe_Funktion_AC_max, compu {0=Cx0_inaktiv (CM_KPVe_Funktion_AC_max_Cx0_inaktiv), 1=Cx1_aktiv (CM_KPVe_Funktion_AC_max_Cx1_aktiv)}, range raw 0..1, transfer-property=PENDING  # Status für Funktion AC max am Klimapanel
            signal KPVe_Funktion_ECO_XIX_KPVe_01_XIX_Klima_LIN1: start 5, 1 bit, little-endian, data-type-policy=OVERRIDE, i-signal-type=PRIMITIVE, init-value=0, base-type=BT_KPVe_Funktion_ECO, compu {0=Cx0_inaktiv (CM_KPVe_Funktion_ECO_Cx0_inaktiv), 1=Cx1_aktiv (CM_KPVe_Funktion_ECO_Cx1_aktiv)}, range raw 0..1, transfer-property=PENDING  # Status für Funktion ECO am Klimapanel
            signal KPVe_Funktion_HSH_XIX_KPVe_01_XIX_Klima_LIN1: start 6, 1 bit, little-endian, data-type-policy=OVERRIDE, i-signal-type=PRIMITIVE, init-value=0, base-type=BT_KPVe_Funktion_HSH, compu {0=Cx0_inaktiv (CM_KPVe_Funktion_HSH_Cx0_inaktiv), 1=Cx1_aktiv (CM_KPVe_Funktion_HSH_Cx1_aktiv)}, range raw 0..1, transfer-property=PENDING  # Status für Funktion HSH am Klimapanel
            signal KPVe_Funktion_Auto_li_XIX_KPVe_01_XIX_Klima_LIN1: start 7, 1 bit, little-endian, data-type-policy=OVERRIDE, i-signal-type=PRIMITIVE, init-value=0, base-type=BT_KPVe_Funktion_Auto_li, compu {0=Cx0_inaktiv (CM_KPVe_Funktion_Auto_li_Cx0_inaktiv), 1=Cx1_aktiv (CM_KPVe_Funktion_Auto_li_Cx1_aktiv)}, range raw 0..1, transfer-property=PENDING  # Status für Funktion Auto li am Klimapanel
            signal KPVe_Funktion_FSH_XIX_KPVe_01_XIX_Klima_LIN1: start 9, 1 bit, little-endian, data-type-policy=OVERRIDE, i-signal-type=PRIMITIVE, init-value=0, base-type=BT_KPVe_Funktion_FSH, compu {0=Cx0_inaktiv (CM_KPVe_Funktion_FSH_Cx0_inaktiv), 1=Cx1_aktiv (CM_KPVe_Funktion_FSH_Cx1_aktiv)}, range raw 0..1, transfer-property=PENDING  # Status für Funktion FSH am Klimapanel
            signal KPVe_Funktion_Klima_Menue_MMI_XIX_KPVe_01_XIX_Klima_LIN1: start 10, 1 bit, little-endian, data-type-policy=OVERRIDE, i-signal-type=PRIMITIVE, init-value=0, base-type=BT_KPVe_Funktion_Klima_Menue_MMI, compu {0=Cx0_inaktiv (CM_KPVe_Funktion_Klima_Menue_MMI_Cx0_inaktiv), 1=Cx1_aktiv (CM_KPVe_Funktion_Klima_Menue_MMI_Cx1_aktiv)}, range raw 0..1, transfer-property=PENDING  # Status für Funktion Klima Menue MMI am Klimapanel
            signal KPVe_Funktion_Joker_Taste_XIX_KPVe_01_XIX_Klima_LIN1: start 11, 1 bit, little-endian, data-type-policy=OVERRIDE, i-signal-type=PRIMITIVE, init-value=0, base-type=BT_KPVe_Funktion_Joker_Taste, compu {0=Cx0_inaktiv (CM_KPVe_Funktion_Joker_Taste_Cx0_inaktiv), 1=Cx1_aktiv (CM_KPVe_Funktion_Joker_Taste_Cx1_aktiv)}, range raw 0..1, transfer-property=PENDING  # Status für Funktion Joker Taste am Klimapanel
            signal KPVe_Funktion_Ionisator_XIX_KPVe_01_XIX_Klima_LIN1: start 12, 1 bit, little-endian, data-type-policy=OVERRIDE, i-signal-type=PRIMITIVE, init-value=0, base-type=BT_KPVe_Funktion_Ionisator, compu {0=Cx0_inaktiv (CM_KPVe_Funktion_Ionisator_Cx0_inaktiv), 1=Cx1_aktiv (CM_KPVe_Funktion_Ionisator_Cx1_aktiv)}, range raw 0..1, transfer-property=PENDING  # Status für Funktion Ionisator am Klimapanel
            signal KPVe_Funktion_Beduftung_XIX_KPVe_01_XIX_Klima_LIN1: start 13, 1 bit, little-endian, data-type-policy=OVERRIDE, i-signal-type=PRIMITIVE, init-value=0, base-type=BT_KPVe_Funktion_Beduftung, compu {0=Cx0_inaktiv (CM_KPVe_Funktion_Beduftung_Cx0_inaktiv), 1=Cx1_aktiv (CM_KPVe_Funktion_Beduftung_Cx1_aktiv)}, range raw 0..1, transfer-property=PENDING  # Status für Funktion Beduftung am Klimapanel
            signal KPVe_Lenker_Position_XIX_KPVe_01_XIX_Klima_LIN1: start 14, 1 bit, little-endian, data-type-policy=OVERRIDE, i-signal-type=PRIMITIVE, init-value=0, base-type=BT_KPVe_Lenker_Position, compu {0=Cx0_Linkslenker (CM_KPVe_Lenker_Position_Cx0_Linkslenker), 1=Cx1_Rechtslenker (CM_KPVe_Lenker_Position_Cx1_Rechtslenker)}, range raw 0..1, transfer-property=PENDING  # Lenkerposition
            signal KPVe_Funktion_Restwaerme_XIX_KPVe_01_XIX_Klima_LIN1: start 15, 1 bit, little-endian, data-type-policy=OVERRIDE, i-signal-type=PRIMITIVE, init-value=0, base-type=BT_KPVe_Funktion_Restwaerme, compu {0=Cx0_inaktiv (CM_KPVe_Funktion_Restwaerme_Cx0_inaktiv), 1=Cx1_aktiv (CM_KPVe_Funktion_Restwaerme_Cx1_aktiv)}, range raw 0..1, transfer-property=PENDING  # Status für Funktion Restwaerme am Klimapanel
            signal KPVe_Funktion_PureAir_XIX_KPVe_01_XIX_Klima_LIN1: start 16, 1 bit, little-endian, data-type-policy=OVERRIDE, i-signal-type=PRIMITIVE, init-value=0, base-type=BT_KPVe_Funktion_PureAir, compu {0=Cx0_inaktiv (CM_KPVe_Funktion_PureAir_Cx0_inaktiv), 1=Cx1_aktiv (CM_KPVe_Funktion_PureAir_Cx1_aktiv)}, range raw 0..1, transfer-property=PENDING  # Status für Funktion PureAir am Klimapanel
            signal KPVe_Funktion_Sync_XIX_KPVe_01_XIX_Klima_LIN1: start 17, 1 bit, little-endian, data-type-policy=OVERRIDE, i-signal-type=PRIMITIVE, init-value=0, base-type=BT_KPVe_Funktion_Sync, compu {0=Cx0_inaktiv (CM_KPVe_Funktion_Sync_Cx0_inaktiv), 1=Cx1_aktiv (CM_KPVe_Funktion_Sync_Cx1_aktiv)}, range raw 0..1, transfer-property=PENDING  # Status für Funktion Sync am Klimapanel
            signal KPVe_Funktion_ECO_Zone_XIX_KPVe_01_XIX_Klima_LIN1: start 18, 1 bit, little-endian, data-type-policy=OVERRIDE, i-signal-type=PRIMITIVE, init-value=0, base-type=BT_KPVe_Funktion_ECO_Zone, compu {0=Cx0_Init_inaktiv (CM_KPVe_Funktion_ECO_Zone_Cx0_Init_inaktiv), 1=Cx1_Beifahrer (CM_KPVe_Funktion_ECO_Zone_Cx1_Beifahrer)}, range raw 0..1, transfer-property=PENDING  # Status für Anzeige ECO am Klimapanel
            signal KPVe_Funktion_Rear_XIX_KPVe_01_XIX_Klima_LIN1: start 19, 1 bit, little-endian, data-type-policy=OVERRIDE, i-signal-type=PRIMITIVE, init-value=0, base-type=BT_KPVe_Funktion_Rear, compu {0=Cx0_inaktiv (CM_KPVe_Funktion_Rear_Cx0_inaktiv), 1=Cx1_aktiv (CM_KPVe_Funktion_Rear_Cx1_aktiv)}, range raw 0..1, transfer-property=PENDING  # Status für Funktion Rear am Klimapanel
            signal KPVe_Verbau_AutoSikli_XIX_KPVe_01_XIX_Klima_LIN1: start 21, 1 bit, little-endian, data-type-policy=OVERRIDE, i-signal-type=PRIMITIVE, init-value=0, base-type=BT_KPVe_Verbau_AutoSikli, compu {0=Cx0_nicht_verbaut (CM_KPVe_Verbau_AutoSikli_Cx0_nicht_verbaut), 1=Cx1_verbaut (CM_KPVe_Verbau_AutoSikli_Cx1_verbaut)}, range raw 0..1, transfer-property=PENDING  # Verbauinformation Sitzclimatronic
            signal KPVe_Einheit_XIX_KPVe_01_XIX_Klima_LIN1: start 23, 1 bit, little-endian, data-type-policy=OVERRIDE, i-signal-type=PRIMITIVE, init-value=0, base-type=BT_KPVe_Einheit, compu {0=Cx0_Celsius (CM_KPVe_Einheit_Cx0_Celsius), 1=Cx1_Fahrenheit (CM_KPVe_Einheit_Cx1_Fahrenheit)}, range raw 0..1, transfer-property=PENDING  # Einheit der Temperatur
            signal KPVe_Suchbeleuchtung_XIX_KPVe_01_XIX_Klima_LIN1: start 24, 1 bit, little-endian, data-type-policy=OVERRIDE, i-signal-type=PRIMITIVE, init-value=0, base-type=BT_KPVe_Suchbeleuchtung, compu {0=Cx0_Aus (CM_KPVe_Suchbeleuchtung_Cx0_Aus), 1=Cx1_Ein (CM_KPVe_Suchbeleuchtung_Cx1_Ein)}, range raw 0..1, transfer-property=PENDING  # Status für Suchbeleuchtung am Klimapanel
            signal KPVe_Funktionsbeleuchtung_XIX_KPVe_01_XIX_Klima_LIN1: start 25, 1 bit, little-endian, data-type-policy=OVERRIDE, i-signal-type=PRIMITIVE, init-value=0, base-type=BT_KPVe_Funktionsbeleuchtung, compu {0=Cx0_Aus (CM_KPVe_Funktionsbeleuchtung_Cx0_Aus), 1=Cx1_Ein (CM_KPVe_Funktionsbeleuchtung_Cx1_Ein)}, range raw 0..1, transfer-property=PENDING  # Status für Funktionsbeleuchtung am Klimapanel
            signal KPVe_Kopfraumheizung_li_XIX_KPVe_01_XIX_Klima_LIN1: start 26, 3 bit, little-endian, data-type-policy=OVERRIDE, i-signal-type=PRIMITIVE, init-value=0, base-type=BT_KPVe_Kopfraumheizung_li, compu {0=Cx0_Stufe_0 (CM_KPVe_Kopfraumheizung_li_Cx0_Stufe_0), 1=Cx1_Stufe_1 (CM_KPVe_Kopfraumheizung_li_Cx1_Stufe_1), 2=Cx2_Stufe_2 (CM_KPVe_Kopfraumheizung_li_Cx2_Stufe_2), 3=Cx3_Stufe_3 (CM_KPVe_Kopfraumheizung_li_Cx3_Stufe_3), 4=Cx4_Stufe_4 (CM_KPVe_Kopfraumheizung_li_Cx4_Stufe_4), 5=Cx5_Stufe_5 (CM_KPVe_Kopfraumheizung_li_Cx5_Stufe_5), 6=Cx6_Stufe_6 (CM_KPVe_Kopfraumheizung_li_Cx6_Stufe_6)}, range raw 0..6, transfer-property=PENDING  # Status der Kopfraumheizung fuer Klimapanel
            signal KPVe_Kopfraumheizung_re_XIX_KPVe_01_XIX_Klima_LIN1: start 29, 3 bit, little-endian, data-type-policy=OVERRIDE, i-signal-type=PRIMITIVE, init-value=0, base-type=BT_KPVe_Kopfraumheizung_re, compu {0=Cx0_Stufe_0 (CM_KPVe_Kopfraumheizung_re_Cx0_Stufe_0), 1=Cx1_Stufe_1 (CM_KPVe_Kopfraumheizung_re_Cx1_Stufe_1), 2=Cx2_Stufe_2 (CM_KPVe_Kopfraumheizung_re_Cx2_Stufe_2), 3=Cx3_Stufe_3 (CM_KPVe_Kopfraumheizung_re_Cx3_Stufe_3), 4=Cx4_Stufe_4 (CM_KPVe_Kopfraumheizung_re_Cx4_Stufe_4), 5=Cx5_Stufe_5 (CM_KPVe_Kopfraumheizung_re_Cx5_Stufe_5), 6=Cx6_Stufe_6 (CM_KPVe_Kopfraumheizung_re_Cx6_Stufe_6)}, range raw 0..6, transfer-property=PENDING  # Status der Kopfraumheizung re fuer Klimapanel
            signal KPVe_Funktion_AutoSiKli_li_XIX_KPVe_01_XIX_Klima_LIN1: start 32, 1 bit, little-endian, data-type-policy=OVERRIDE, i-signal-type=PRIMITIVE, init-value=0, base-type=BT_KPVe_Funktion_AutoSiKli_li, compu {0=Cx0_OFF (CM_KPVe_Funktion_AutoSiKli_li_Cx0_OFF), 1=Cx1_ON (CM_KPVe_Funktion_AutoSiKli_li_Cx1_ON)}, range raw 0..1, transfer-property=PENDING  # Status für Funktion Automatische Sitzklimatisierung links am Klimapanel
            signal KPVe_Funktion_AutoSiKli_re_XIX_KPVe_01_XIX_Klima_LIN1: start 33, 1 bit, little-endian, data-type-policy=OVERRIDE, i-signal-type=PRIMITIVE, init-value=0, base-type=BT_KPVe_Funktion_AutoSiKli_re, compu {0=Cx0_OFF (CM_KPVe_Funktion_AutoSiKli_re_Cx0_OFF), 1=Cx1_ON (CM_KPVe_Funktion_AutoSiKli_re_Cx1_ON)}, range raw 0..1, transfer-property=PENDING  # Status für Funktion Automatische Sitzklimatisierung rechts am Klimapanel
            signal KPVe_Sitzheizung_li_XIX_KPVe_01_XIX_Klima_LIN1: start 34, 3 bit, little-endian, data-type-policy=OVERRIDE, i-signal-type=PRIMITIVE, init-value=0, base-type=BT_KPVe_Sitzheizung_li, compu {0=Cx0_Stufe_0 (CM_KPVe_Sitzheizung_li_Cx0_Stufe_0), 1=Cx1_Stufe_1 (CM_KPVe_Sitzheizung_li_Cx1_Stufe_1), 2=Cx2_Stufe_2 (CM_KPVe_Sitzheizung_li_Cx2_Stufe_2), 3=Cx3_Stufe_3 (CM_KPVe_Sitzheizung_li_Cx3_Stufe_3), 4=Cx4_Stufe_4 (CM_KPVe_Sitzheizung_li_Cx4_Stufe_4), 5=Cx5_Stufe_5 (CM_KPVe_Sitzheizung_li_Cx5_Stufe_5), 6=Cx6_Stufe_6 (CM_KPVe_Sitzheizung_li_Cx6_Stufe_6)}, range raw 0..6, transfer-property=PENDING  # Status der Sitzheizung li fuer Klimapanel Bei aktivem KPVe_Funktion_AutoSiKli_li als Statusanzeige benutzt
            signal KPVe_Sitzheizung_re_XIX_KPVe_01_XIX_Klima_LIN1: start 37, 3 bit, little-endian, data-type-policy=OVERRIDE, i-signal-type=PRIMITIVE, init-value=0, base-type=BT_KPVe_Sitzheizung_re, compu {0=Cx0_Stufe_0 (CM_KPVe_Sitzheizung_re_Cx0_Stufe_0), 1=Cx1_Stufe_1 (CM_KPVe_Sitzheizung_re_Cx1_Stufe_1), 2=Cx2_Stufe_2 (CM_KPVe_Sitzheizung_re_Cx2_Stufe_2), 3=Cx3_Stufe_3 (CM_KPVe_Sitzheizung_re_Cx3_Stufe_3), 4=Cx4_Stufe_4 (CM_KPVe_Sitzheizung_re_Cx4_Stufe_4), 5=Cx5_Stufe_5 (CM_KPVe_Sitzheizung_re_Cx5_Stufe_5), 6=Cx6_Stufe_6 (CM_KPVe_Sitzheizung_re_Cx6_Stufe_6)}, range raw 0..6, transfer-property=PENDING  # Status der Sitzheizung re fuer Klimapanel Bei aktivem KPVe_Funktion_AutoSiKli_re als Statusanzeige benutzt
            signal KPVe_LCD_XIX_KPVe_01_XIX_Klima_LIN1: start 40, 1 bit, little-endian, data-type-policy=OVERRIDE, i-signal-type=PRIMITIVE, init-value=0, base-type=BT_KPVe_LCD, compu {0=Cx0_Aus (CM_KPVe_LCD_Cx0_Aus), 1=Cx1_Ein (CM_KPVe_LCD_Cx1_Ein)}, range raw 0..1, transfer-property=PENDING  # Status für LCD am Klimapanel
            signal KPVe_Sitzlueftung_li_XIX_KPVe_01_XIX_Klima_LIN1: start 42, 3 bit, little-endian, data-type-policy=OVERRIDE, i-signal-type=PRIMITIVE, init-value=0, base-type=BT_KPVe_Sitzlueftung_li, compu {0=Cx0_Stufe_0 (CM_KPVe_Sitzlueftung_li_Cx0_Stufe_0), 1=Cx1_Stufe_1 (CM_KPVe_Sitzlueftung_li_Cx1_Stufe_1), 2=Cx2_Stufe_2 (CM_KPVe_Sitzlueftung_li_Cx2_Stufe_2), 3=Cx3_Stufe_3 (CM_KPVe_Sitzlueftung_li_Cx3_Stufe_3), 4=Cx4_Stufe_4 (CM_KPVe_Sitzlueftung_li_Cx4_Stufe_4), 5=Cx5_Stufe_5 (CM_KPVe_Sitzlueftung_li_Cx5_Stufe_5), 6=Cx6_Stufe_6 (CM_KPVe_Sitzlueftung_li_Cx6_Stufe_6)}, range raw 0..6, transfer-property=PENDING  # Status der Sitzlueftung li fuer Klimapanel Bei aktivem KPVe_Funktion_AutoSiKli_li als Statusanzeige benutzt
            signal KPVe_Sitzlueftung_re_XIX_KPVe_01_XIX_Klima_LIN1: start 45, 3 bit, little-endian, data-type-policy=OVERRIDE, i-signal-type=PRIMITIVE, init-value=0, base-type=BT_KPVe_Sitzlueftung_re, compu {0=Cx0_Stufe_0 (CM_KPVe_Sitzlueftung_re_Cx0_Stufe_0), 1=Cx1_Stufe_1 (CM_KPVe_Sitzlueftung_re_Cx1_Stufe_1), 2=Cx2_Stufe_2 (CM_KPVe_Sitzlueftung_re_Cx2_Stufe_2), 3=Cx3_Stufe_3 (CM_KPVe_Sitzlueftung_re_Cx3_Stufe_3), 4=Cx4_Stufe_4 (CM_KPVe_Sitzlueftung_re_Cx4_Stufe_4), 5=Cx5_Stufe_5 (CM_KPVe_Sitzlueftung_re_Cx5_Stufe_5), 6=Cx6_Stufe_6 (CM_KPVe_Sitzlueftung_re_Cx6_Stufe_6)}, range raw 0..6, transfer-property=PENDING  # Status der Sitzlueftung re fuer Klimapanel Bei aktivem KPVe_Funktion_AutoSiKli_re als Statusanzeige benutzt
            signal KPVe_Temp_li_XIX_KPVe_01_XIX_Klima_LIN1: start 48, 8 bit, little-endian, data-type-policy=OVERRIDE, i-signal-type=PRIMITIVE, init-value=0, base-type=BT_KPVe_Temp_li, invalid-value=Invalid_KPVe_Temp_li_XIX_KPVe_01_XIX_Klima_LIN1:255, compu {phys=raw*0.1+10 for raw 0..254, 255=Cxff_Fehler (CM_KPVe_Temp_li_Cxff_Fehler); unit Unit_DegreCelsi}, range phys 10..35.4 Unit_DegreCelsi, raw 0..255, unit=Unit_DegreCelsi, transfer-property=PENDING  # Status Eingestellte Temperatur links
            signal KPVe_Temp_re_XIX_KPVe_01_XIX_Klima_LIN1: start 56, 8 bit, little-endian, data-type-policy=OVERRIDE, i-signal-type=PRIMITIVE, init-value=0, base-type=BT_KPVe_Temp_re, invalid-value=Invalid_KPVe_Temp_re_XIX_KPVe_01_XIX_Klima_LIN1:255, compu {phys=raw*0.1+10 for raw 0..254, 255=Cxff_Fehler (CM_KPVe_Temp_re_Cxff_Fehler); unit Unit_DegreCelsi}, range phys 10..35.4 Unit_DegreCelsi, raw 0..255, unit=Unit_DegreCelsi, transfer-property=PENDING  # Status Eingestellte Temperatur rechts
        frame KPVe_02_XIX_Klima_LIN1: id 0x29, from Klima, frame-length=8, lin-checksum=ENHANCED  # Kopie KPVe_02 mit geänderter Frame-ID wegen ID-Kollision auf Klima_LIN1
          pdu KPVe_02_XIX_Klima_LIN1: length=8, unused-bit-pattern=0  # Kopie KPVe_02 mit geänderter Frame-ID wegen ID-Kollision auf Klima_LIN1
            signal KPVe_Symbol_Luftmenge_li_XIX_KPVe_02_XIX_Klima_LIN1: start 0, 1 bit, little-endian, data-type-policy=OVERRIDE, i-signal-type=PRIMITIVE, init-value=0, base-type=BT_KPVe_Symbol_Luftmenge_li, compu {0=Cx0_Aus (CM_KPVe_Symbol_Luftmenge_li_Cx0_Aus), 1=Cx1_Ein (CM_KPVe_Symbol_Luftmenge_li_Cx1_Ein)}, range raw 0..1, transfer-property=PENDING  # Status für Symbol Luftmenge li am Klimapanel
            signal KPVe_Symbol_Luftverteilung_li_XIX_KPVe_02_XIX_Klima_LIN1: start 2, 1 bit, little-endian, data-type-policy=OVERRIDE, i-signal-type=PRIMITIVE, init-value=0, base-type=BT_KPVe_Symbol_Luftverteilung_li, compu {0=Cx0_Aus (CM_KPVe_Symbol_Luftverteilung_li_Cx0_Aus), 1=Cx1_Ein (CM_KPVe_Symbol_Luftverteilung_li_Cx1_Ein)}, range raw 0..1, transfer-property=PENDING  # Status für Symbol Luftverteilung li am Klimapanel
            signal KPVe_Geblaese_Stufe_li_XIX_KPVe_02_XIX_Klima_LIN1: start 4, 4 bit, little-endian, data-type-policy=OVERRIDE, i-signal-type=PRIMITIVE, init-value=0, base-type=BT_KPVe_Geblaese_Stufe_li, compu {0=Cx0_Geblaese_Stufe_0 (CM_KPVe_Geblaese_Stufe_li_Cx0_Geblaese_Stufe_0), 1=Cx1_Geblaese_Stufe_1 (CM_KPVe_Geblaese_Stufe_li_Cx1_Geblaese_Stufe_1), 2=Cx2_Geblaese_Stufe_2 (CM_KPVe_Geblaese_Stufe_li_Cx2_Geblaese_Stufe_2), 3=Cx3_Geblaese_Stufe_3 (CM_KPVe_Geblaese_Stufe_li_Cx3_Geblaese_Stufe_3), 4=Cx4_Geblaese_Stufe_4 (CM_KPVe_Geblaese_Stufe_li_Cx4_Geblaese_Stufe_4), 5=Cx5_Geblaese_Stufe_5 (CM_KPVe_Geblaese_Stufe_li_Cx5_Geblaese_Stufe_5), 6=Cx6_Geblaese_Stufe_6 (CM_KPVe_Geblaese_Stufe_li_Cx6_Geblaese_Stufe_6), 7=Cx7_Geblaese_Stufe_7 (CM_KPVe_Geblaese_Stufe_li_Cx7_Geblaese_Stufe_7), 8=Cx8_Geblaese_Stufe_8 (CM_KPVe_Geblaese_Stufe_li_Cx8_Geblaese_Stufe_8), 9=Cx9_Geblaese_Stufe_9 (CM_KPVe_Geblaese_Stufe_li_Cx9_Geblaese_Stufe_9), 10=Cxa_Geblaese_Stufe_10 (CM_KPVe_Geblaese_Stufe_li_Cxa_Geblaese_Stufe_10), 11=Cxb_Geblaese_Stufe_11 (CM_KPVe_Geblaese_Stufe_li_Cxb_Geblaese_Stufe_11), 12=Cxc_Geblaese_Stufe_12 (CM_KPVe_Geblaese_Stufe_li_Cxc_Geblaese_Stufe_12)}, range raw 0..12, transfer-property=PENDING  # Status der Geblaese Stufe links am Klimapanel
            signal KPVe_Luftverteilung_Oben_li_XIX_KPVe_02_XIX_Klima_LIN1: start 12, 1 bit, little-endian, data-type-policy=OVERRIDE, i-signal-type=PRIMITIVE, init-value=0, base-type=BT_KPVe_Luftverteilung_Oben_li, compu {0=Cx0_inaktiv (CM_KPVe_Luftverteilung_Oben_li_Cx0_inaktiv), 1=Cx1_aktiv (CM_KPVe_Luftverteilung_Oben_li_Cx1_aktiv)}, range raw 0..1, transfer-property=PENDING  # Status für Luftverteilung Oben li am Klimapanel
            signal KPVe_Luftverteilung_Mitte_li_XIX_KPVe_02_XIX_Klima_LIN1: start 13, 1 bit, little-endian, data-type-policy=OVERRIDE, i-signal-type=PRIMITIVE, init-value=0, base-type=BT_KPVe_Luftverteilung_Mitte_li, compu {0=Cx0_inaktiv (CM_KPVe_Luftverteilung_Mitte_li_Cx0_inaktiv), 1=Cx1_aktiv (CM_KPVe_Luftverteilung_Mitte_li_Cx1_aktiv)}, range raw 0..1, transfer-property=PENDING  # Status für Luftverteilung Mitte li am Klimapanel
            signal KPVe_Luftverteilung_Unten_li_XIX_KPVe_02_XIX_Klima_LIN1: start 14, 1 bit, little-endian, data-type-policy=OVERRIDE, i-signal-type=PRIMITIVE, init-value=0, base-type=BT_KPVe_Luftverteilung_Unten_li, compu {0=Cx0_inaktiv (CM_KPVe_Luftverteilung_Unten_li_Cx0_inaktiv), 1=Cx1_aktiv (CM_KPVe_Luftverteilung_Unten_li_Cx1_aktiv)}, range raw 0..1, transfer-property=PENDING  # Status für Luftverteilung Unten li am Klimapanel
            signal KPVe_Luftverteilung_Auto_li_XIX_KPVe_02_XIX_Klima_LIN1: start 15, 1 bit, little-endian, data-type-policy=OVERRIDE, i-signal-type=PRIMITIVE, init-value=0, base-type=BT_KPVe_Luftverteilung_Auto_li, compu {0=Cx0_inaktiv (CM_KPVe_Luftverteilung_Auto_li_Cx0_inaktiv), 1=Cx1_aktiv (CM_KPVe_Luftverteilung_Auto_li_Cx1_aktiv)}, range raw 0..1, transfer-property=PENDING  # Status für Luftverteilung Auto li am Klimapanel
            signal DI_KL_58xd_XIX_KPVe_02_XIX_Klima_LIN1: start 24, 8 bit, little-endian, data-type-policy=OVERRIDE, i-signal-type=PRIMITIVE, init-value=254, base-type=BT_DI_KL_58xd, invalid-value=Invalid_DI_KL_58xd_XIX_KPVe_02_XIX_Klima_LIN1:255, compu {phys=raw for raw 0..253, 254=Cxfe_Init (CM_DI_KL_58xd_Cxfe_Init), 255=Cxff_Fehler (CM_DI_KL_58xd_Cxff_Fehler)}, range phys 0..253, raw 0..255, transfer-property=PENDING  # Klemme 58xd Display- und Funktionsbeleuchtung Mit der Klemme 58xd wird die Helligkeit der Display- und der Funktionsbeleuchtungen der Schalter gesteuert. Im Detail beschrieben im 'Funktionslastenheft Dimmung MQB'.
            signal DI_KL_58xs_XIX_KPVe_02_XIX_Klima_LIN1: start 32, 7 bit, little-endian, data-type-policy=OVERRIDE, i-signal-type=PRIMITIVE, init-value=126, base-type=BT_DI_KL_58xs, invalid-value=Invalid_DI_KL_58xs_XIX_KPVe_02_XIX_Klima_LIN1:127, compu {phys=raw for raw 0..100, 126=Cx7e_Init (CM_DI_KL_58xs_Cx7e_Init), 127=Cx7f_Fehler (CM_DI_KL_58xs_Cx7f_Fehler); unit Unit_PerCent}, range phys 0..100 Unit_PerCent, raw 0..127, unit=Unit_PerCent, transfer-property=PENDING  # Suchbeleuchtung Schalter EIN-AUS-Schaltalgorithmus der allgemeinen Schaltersuchbeleuchtung. Im Detail beschrieben im 'Funktionslastenheft Dimmung MQB'.
            signal ZAS_Kl_15_XIX_KPVe_02_XIX_Klima_LIN1: start 39, 1 bit, little-endian, data-type-policy=OVERRIDE, i-signal-type=PRIMITIVE, init-value=0, base-type=BT_ZAS_Kl_15, compu {0=Cx0_aus (CM_ZAS_Kl_15_Cx0_aus), 1=Cx1_ein (CM_ZAS_Kl_15_Cx1_ein)}, range raw 0..1, transfer-property=PENDING  # Klemme 15: Zuendung (SW-Kl.15)
            signal DI_KL_58xt_XIX_KPVe_02_XIX_Klima_LIN1: start 40, 7 bit, little-endian, data-type-policy=OVERRIDE, i-signal-type=PRIMITIVE, init-value=126, base-type=BT_DI_KL_58xt, invalid-value=Invalid_DI_KL_58xt_XIX_KPVe_02_XIX_Klima_LIN1:127, compu {phys=raw for raw 0..100, 126=Cx7e_Init (CM_DI_KL_58xt_Cx7e_Init), 127=Cx7f_Fehler (CM_DI_KL_58xt_Cx7f_Fehler); unit Unit_PerCent}, range phys 0..100 Unit_PerCent, raw 0..127, unit=Unit_PerCent, transfer-property=PENDING  # Timergesteuerte Suchbeleuchtung Der EIN-AUS-Schaltalgorithmus für die vor- und nachlaufende Schaltersuchbeleuchtungen beim Ein- & Aussteigen; z.B.: Start/Stop-Taster. Im Detail beschrieben im 'Funktionslastenheft Dimmung MQB'.
            signal KPVe_Funktion_Locked_XIX_KPVe_02_XIX_Klima_LIN1: start 47, 1 bit, little-endian, data-type-policy=OVERRIDE, i-signal-type=PRIMITIVE, init-value=0, base-type=BT_KPVe_Funktion_Locked, compu {0=Cx0_Bedienung_freigeben (CM_KPVe_Funktion_Locked_Cx0_Bedienung_freigeben), 1=Cx1_Bedienung_gesperrt (CM_KPVe_Funktion_Locked_Cx1_Bedienung_gesperrt)}, range raw 0..1, transfer-property=PENDING  # Dient dem Sperren der Klimabedienung durch den Master (unterdrücken von Flackern durch voreilende Anzeige)
            signal KPVe_Funktion_Konditionierung_XIX_KPVe_02_XIX_Klima_LIN1: start 50, 3 bit, little-endian, data-type-policy=OVERRIDE, i-signal-type=PRIMITIVE, init-value=0, base-type=BT_KPVe_Funktion_Konditionierung, compu {0=Cx0_Symbole_aus (CM_KPVe_Funktion_Konditionierung_Cx0_Symbole_aus), 1=Cx1_Uhr_und_Wendel_an (CM_KPVe_Funktion_Konditionierung_Cx1_Uhr_und_Wendel_an), 2=Cx2_Wendel_an (CM_KPVe_Funktion_Konditionierung_Cx2_Wendel_an), 3=Cx3_Wendel_blinkend (CM_KPVe_Funktion_Konditionierung_Cx3_Wendel_blinkend), 4=Cx4_Uhr_an (CM_KPVe_Funktion_Konditionierung_Cx4_Uhr_an), 5=Cx5_Uhr_blinkend (CM_KPVe_Funktion_Konditionierung_Cx5_Uhr_blinkend), 6=Cx6_reserved (CM_KPVe_Funktion_Konditionierung_Cx6_reserved), 7=Cx7_reserved (CM_KPVe_Funktion_Konditionierung_Cx7_reserved)}, range raw 0..7, transfer-property=PENDING  # Signal zur Anzeige des Timersymbols im LIN-Panel
            signal KPVe_Funktion_AutoUmluft_XIX_KPVe_02_XIX_Klima_LIN1: start 53, 1 bit, little-endian, data-type-policy=OVERRIDE, i-signal-type=PRIMITIVE, init-value=0, base-type=BT_KPVe_Funktion_AutoUmluft, compu {0=Cx0_inaktiv (CM_KPVe_Funktion_AutoUmluft_Cx0_inaktiv), 1=Cx1_aktiv (CM_KPVe_Funktion_AutoUmluft_Cx1_aktiv)}, range raw 0..1, transfer-property=PENDING  # Rückmeldung ob die Auto-Umluft-Funktion aktiv ist
            signal KPVe_Funktion_OBD_XIX_KPVe_02_XIX_Klima_LIN1: start 54, 2 bit, little-endian, data-type-policy=OVERRIDE, i-signal-type=PRIMITIVE, init-value=0, base-type=BT_KPVe_Funktion_OBD, compu {0=Cx0_OBD_disabled (CM_KPVe_Funktion_OBD_Cx0_OBD_disabled), 1=Cx1_OBD_permitted (CM_KPVe_Funktion_OBD_Cx1_OBD_permitted), 2=Cx2_OBD_active (CM_KPVe_Funktion_OBD_Cx2_OBD_active), 3=Cx3_reserved (CM_KPVe_Funktion_OBD_Cx3_reserved)}, range raw 0..3, transfer-property=PENDING  # Funktionsverfügbarkeit der OnBoard-Diagnose
            signal KPVe_OBD_Gruppe_XIX_KPVe_02_XIX_Klima_LIN1: start 56, 4 bit, little-endian, data-type-policy=OVERRIDE, i-signal-type=PRIMITIVE, init-value=0, base-type=BT_KPVe_OBD_Gruppe, compu {phys=raw for raw 0..15; unit Unit_None}, range phys 0..15 Unit_None, raw 0..15, unit=Unit_None, transfer-property=PENDING  # Vorgabe vom Klima-SG bei aktivem Applikationsmodus, welche Kanalgruppe anzuzeigen ist.
            signal KPVe_Geblaese_Begrenzung_XIX_KPVe_02_XIX_Klima_LIN1: start 60, 1 bit, little-endian, data-type-policy=OVERRIDE, i-signal-type=PRIMITIVE, init-value=0, base-type=BT_KPVe_Geblaese_Begrenzung, compu {0=Cx0_keine_Begrenzung (CM_KPVe_Geblaese_Begrenzung_Cx0_keine_Begrenzung), 1=Cx1_Begrenzung_aktiv (CM_KPVe_Geblaese_Begrenzung_Cx1_Begrenzung_aktiv)}, range raw 0..1, transfer-property=PENDING  # Gebläsestufenbegrenzung
            signal KPVe_Geblaese_Auto_li_XIX_KPVe_02_XIX_Klima_LIN1: start 61, 1 bit, little-endian, data-type-policy=OVERRIDE, i-signal-type=PRIMITIVE, init-value=0, base-type=BT_KPVe_Geblaese_Auto_li, compu {0=Cx0_inaktiv (CM_KPVe_Geblaese_Auto_li_Cx0_inaktiv), 1=Cx1_aktiv (CM_KPVe_Geblaese_Auto_li_Cx1_aktiv)}, range raw 0..1, transfer-property=PENDING  # Status für Gebläse Auto links
            signal KPVe_Auto_Toggle_XIX_KPVe_02_XIX_Klima_LIN1: start 63, 1 bit, little-endian, data-type-policy=OVERRIDE, i-signal-type=PRIMITIVE, init-value=0, base-type=BT_KPVe_Auto_Toggle, compu {0=Cx0_inaktiv (CM_KPVe_Auto_Toggle_Cx0_inaktiv), 1=Cx1_aktiv (CM_KPVe_Auto_Toggle_Cx1_aktiv)}, range raw 0..1, transfer-property=PENDING  # Status der Konfiguration der Auto-Toggle-Funktion (Parametrierung im BCM)
        frame KPVs_01_XIX_Klima_LIN1: id 0x5, to Klima, frame-length=8, lin-checksum=ENHANCED  # Kopie KPVs_01 mit geänderter Frame-ID wegen ID-Kollision auf Klima_LIN1
          pdu KPVs_01_XIX_Klima_LIN1: length=8, unused-bit-pattern=0  # Kopie KPVs_01 mit geänderter Frame-ID wegen ID-Kollision auf Klima_LIN1
            signal KPV_Off_XIX_KPVs_01_XIX_Klima_LIN1: start 0, 1 bit, little-endian, data-type-policy=OVERRIDE, i-signal-type=PRIMITIVE, init-value=0, base-type=BT_KPV_Off, compu {0=Cx0_nicht_betaetigt (CM_KPV_Off_Cx0_nicht_betaetigt), 1=Cx1_betaetigt (CM_KPV_Off_Cx1_betaetigt)}, range raw 0..1, transfer-property=PENDING, to Klima(timeout 3.5 s)  # Auswahl der Funktion Off
            signal KPV_Defrost_XIX_KPVs_01_XIX_Klima_LIN1: start 1, 1 bit, little-endian, data-type-policy=OVERRIDE, i-signal-type=PRIMITIVE, init-value=0, base-type=BT_KPV_Defrost, compu {0=Cx0_nicht_betaetigt (CM_KPV_Defrost_Cx0_nicht_betaetigt), 1=Cx1_betaetigt (CM_KPV_Defrost_Cx1_betaetigt)}, range raw 0..1, transfer-property=PENDING, to Klima(timeout 3.5 s)  # Auswahl der Funktion Defrost
            signal KPV_Umluft_XIX_KPVs_01_XIX_Klima_LIN1: start 2, 1 bit, little-endian, data-type-policy=OVERRIDE, i-signal-type=PRIMITIVE, init-value=0, base-type=BT_KPV_Umluft, compu {0=Cx0_nicht_betaetigt (CM_KPV_Umluft_Cx0_nicht_betaetigt), 1=Cx1_betaetigt (CM_KPV_Umluft_Cx1_betaetigt)}, range raw 0..1, transfer-property=PENDING, to Klima(timeout 3.5 s)  # Auswahl der Funktion Umluft
            signal KPV_AC_XIX_KPVs_01_XIX_Klima_LIN1: start 3, 1 bit, little-endian, data-type-policy=OVERRIDE, i-signal-type=PRIMITIVE, init-value=0, base-type=BT_KPV_AC, compu {0=Cx0_nicht_betaetigt (CM_KPV_AC_Cx0_nicht_betaetigt), 1=Cx1_betaetigt (CM_KPV_AC_Cx1_betaetigt)}, range raw 0..1, transfer-property=PENDING, to Klima(timeout 3.5 s)  # Auswahl der Funktion AC
            signal KPV_AC_max_XIX_KPVs_01_XIX_Klima_LIN1: start 4, 1 bit, little-endian, data-type-policy=OVERRIDE, i-signal-type=PRIMITIVE, init-value=0, base-type=BT_KPV_AC_max, compu {0=Cx0_nicht_betaetigt (CM_KPV_AC_max_Cx0_nicht_betaetigt), 1=Cx1_betaetigt (CM_KPV_AC_max_Cx1_betaetigt)}, range raw 0..1, transfer-property=PENDING, to Klima(timeout 3.5 s)  # Auswahl der Funktion AC max
            signal KPV_ECO_XIX_KPVs_01_XIX_Klima_LIN1: start 5, 1 bit, little-endian, data-type-policy=OVERRIDE, i-signal-type=PRIMITIVE, init-value=0, base-type=BT_KPV_ECO, compu {0=Cx0_nicht_betaetigt (CM_KPV_ECO_Cx0_nicht_betaetigt), 1=Cx1_betaetigt (CM_KPV_ECO_Cx1_betaetigt)}, range raw 0..1, transfer-property=PENDING, to Klima(timeout 3.5 s)  # Auswahl der Funktion ECO
            signal KPV_HSH_XIX_KPVs_01_XIX_Klima_LIN1: start 6, 1 bit, little-endian, data-type-policy=OVERRIDE, i-signal-type=PRIMITIVE, init-value=0, base-type=BT_KPV_HSH, compu {0=Cx0_nicht_betaetigt (CM_KPV_HSH_Cx0_nicht_betaetigt), 1=Cx1_betaetigt (CM_KPV_HSH_Cx1_betaetigt)}, range raw 0..1, transfer-property=PENDING, to Klima(timeout 3.5 s)  # Auswahl der Funktion HSH
            signal KPV_Sync_XIX_KPVs_01_XIX_Klima_LIN1: start 7, 1 bit, little-endian, data-type-policy=OVERRIDE, i-signal-type=PRIMITIVE, init-value=0, base-type=BT_KPV_Sync, compu {0=Cx0_nicht_betaetigt (CM_KPV_Sync_Cx0_nicht_betaetigt), 1=Cx1_betaetigt (CM_KPV_Sync_Cx1_betaetigt)}, range raw 0..1, transfer-property=PENDING, to Klima(timeout 3.5 s)  # Auswahl der Funktion Sync
            signal KPV_Rear_XIX_KPVs_01_XIX_Klima_LIN1: start 8, 1 bit, little-endian, data-type-policy=OVERRIDE, i-signal-type=PRIMITIVE, init-value=0, base-type=BT_KPV_Rear, compu {0=Cx0_nicht_betaetigt (CM_KPV_Rear_Cx0_nicht_betaetigt), 1=Cx1_betaetigt (CM_KPV_Rear_Cx1_betaetigt)}, range raw 0..1, transfer-property=PENDING, to Klima(timeout 3.5 s)  # Auswahl der Funktion Rear
            signal KPV_FSH_XIX_KPVs_01_XIX_Klima_LIN1: start 9, 1 bit, little-endian, data-type-policy=OVERRIDE, i-signal-type=PRIMITIVE, init-value=0, base-type=BT_KPV_FSH, compu {0=Cx0_nicht_betaetigt (CM_KPV_FSH_Cx0_nicht_betaetigt), 1=Cx1_betaetigt (CM_KPV_FSH_Cx1_betaetigt)}, range raw 0..1, transfer-property=PENDING, to Klima(timeout 3.5 s)  # Auswahl der Funktion FSH
            signal KPV_Klima_Menue_MMI_XIX_KPVs_01_XIX_Klima_LIN1: start 10, 1 bit, little-endian, data-type-policy=OVERRIDE, i-signal-type=PRIMITIVE, init-value=0, base-type=BT_KPV_Klima_Menue_MMI, compu {0=Cx0_nicht_betaetigt (CM_KPV_Klima_Menue_MMI_Cx0_nicht_betaetigt), 1=Cx1_betaetigt (CM_KPV_Klima_Menue_MMI_Cx1_betaetigt)}, range raw 0..1, transfer-property=PENDING, to Klima(timeout 3.5 s)  # Auswahl der Funktion Klima Menue MMI
            signal KPV_Joker_Taste_XIX_KPVs_01_XIX_Klima_LIN1: start 11, 1 bit, little-endian, data-type-policy=OVERRIDE, i-signal-type=PRIMITIVE, init-value=0, base-type=BT_KPV_Joker_Taste, compu {0=Cx0_nicht_betaetigt (CM_KPV_Joker_Taste_Cx0_nicht_betaetigt), 1=Cx1_betaetigt (CM_KPV_Joker_Taste_Cx1_betaetigt)}, range raw 0..1, transfer-property=PENDING, to Klima(timeout 3.5 s)  # Auswahl der Funktion Joker Taste
            signal KPV_Ionisator_XIX_KPVs_01_XIX_Klima_LIN1: start 12, 1 bit, little-endian, data-type-policy=OVERRIDE, i-signal-type=PRIMITIVE, init-value=0, base-type=BT_KPV_Ionisator, compu {0=Cx0_nicht_betaetigt (CM_KPV_Ionisator_Cx0_nicht_betaetigt), 1=Cx1_betaetigt (CM_KPV_Ionisator_Cx1_betaetigt)}, range raw 0..1, transfer-property=PENDING, to Klima(timeout 3.5 s)  # Auswahl der Funktion Ionisator
            signal KPV_Beduftung_XIX_KPVs_01_XIX_Klima_LIN1: start 13, 1 bit, little-endian, data-type-policy=OVERRIDE, i-signal-type=PRIMITIVE, init-value=0, base-type=BT_KPV_Beduftung, compu {0=Cx0_nicht_betaetigt (CM_KPV_Beduftung_Cx0_nicht_betaetigt), 1=Cx1_betaetigt (CM_KPV_Beduftung_Cx1_betaetigt)}, range raw 0..1, transfer-property=PENDING, to Klima(timeout 3.5 s)  # Auswahl der Funktion Beduftung
            signal KPV_Init_2_XIX_KPVs_01_XIX_Klima_LIN1: start 14, 1 bit, little-endian, data-type-policy=OVERRIDE, i-signal-type=PRIMITIVE, init-value=1, base-type=BT_KPV_Init_2, compu {0=Cx0_Normaler_Betrieb (CM_KPV_Init_2_Cx0_Normaler_Betrieb), 1=Cx1_Init (CM_KPV_Init_2_Cx1_Init)}, range raw 0..1, transfer-property=PENDING, to Klima(timeout 3.5 s)  # Init-Flag für die KPVs_01-Botschaft als Rückmeldung an den Master, dass die Werte dieser Botschaft nicht als Kundenwunsch zu interpretieren sind
            signal KPV_Restwaerme_XIX_KPVs_01_XIX_Klima_LIN1: start 15, 1 bit, little-endian, data-type-policy=OVERRIDE, i-signal-type=PRIMITIVE, init-value=0, base-type=BT_KPV_Restwaerme, compu {0=Cx0_nicht_betaetigt (CM_KPV_Restwaerme_Cx0_nicht_betaetigt), 1=Cx1_betaetigt (CM_KPV_Restwaerme_Cx1_betaetigt)}, range raw 0..1, transfer-property=PENDING, to Klima(timeout 3.5 s)  # Auswahl der Funktion Restwaerme
            signal KPV_Sitzheizung_li_XIX_KPVs_01_XIX_Klima_LIN1: start 16, 3 bit, little-endian, data-type-policy=OVERRIDE, i-signal-type=PRIMITIVE, init-value=0, base-type=BT_KPV_Sitzheizung_li, compu {0=Cx0_Stufe_0 (CM_KPV_Sitzheizung_li_Cx0_Stufe_0), 1=Cx1_Stufe_1 (CM_KPV_Sitzheizung_li_Cx1_Stufe_1), 2=Cx2_Stufe_2 (CM_KPV_Sitzheizung_li_Cx2_Stufe_2), 3=Cx3_Stufe_3 (CM_KPV_Sitzheizung_li_Cx3_Stufe_3), 4=Cx4_Stufe_4 (CM_KPV_Sitzheizung_li_Cx4_Stufe_4), 5=Cx5_Stufe_5 (CM_KPV_Sitzheizung_li_Cx5_Stufe_5), 6=Cx6_Stufe_6 (CM_KPV_Sitzheizung_li_Cx6_Stufe_6)}, range raw 0..6, transfer-property=PENDING, to Klima(timeout 3.5 s)  # Auswahl der Funktion Sitzheizung li
            signal KPV_Sitzlueftung_li_XIX_KPVs_01_XIX_Klima_LIN1: start 19, 3 bit, little-endian, data-type-policy=OVERRIDE, i-signal-type=PRIMITIVE, init-value=0, base-type=BT_KPV_Sitzlueftung_li, compu {0=Cx0_Stufe_0 (CM_KPV_Sitzlueftung_li_Cx0_Stufe_0), 1=Cx1_Stufe_1 (CM_KPV_Sitzlueftung_li_Cx1_Stufe_1), 2=Cx2_Stufe_2 (CM_KPV_Sitzlueftung_li_Cx2_Stufe_2), 3=Cx3_Stufe_3 (CM_KPV_Sitzlueftung_li_Cx3_Stufe_3), 4=Cx4_Stufe_4 (CM_KPV_Sitzlueftung_li_Cx4_Stufe_4), 5=Cx5_Stufe_5 (CM_KPV_Sitzlueftung_li_Cx5_Stufe_5), 6=Cx6_Stufe_6 (CM_KPV_Sitzlueftung_li_Cx6_Stufe_6)}, range raw 0..6, transfer-property=PENDING, to Klima(timeout 3.5 s)  # Auswahl der Funktion Sitzlueftung li
            signal KPV_Kopfraumheizung_li_XIX_KPVs_01_XIX_Klima_LIN1: start 22, 1 bit, little-endian, data-type-policy=OVERRIDE, i-signal-type=PRIMITIVE, init-value=0, base-type=BT_KPV_Kopfraumheizung_li, compu {0=Cx0_nicht_betaetigt (CM_KPV_Kopfraumheizung_li_Cx0_nicht_betaetigt), 1=Cx1_betaetigt (CM_KPV_Kopfraumheizung_li_Cx1_betaetigt)}, range raw 0..1, transfer-property=PENDING, to Klima(timeout 3.5 s)  # Auswahl der Funktion Kopfraumheizung li
            signal KPV_Auto_li_XIX_KPVs_01_XIX_Klima_LIN1: start 23, 1 bit, little-endian, data-type-policy=OVERRIDE, i-signal-type=PRIMITIVE, init-value=0, base-type=BT_KPV_Auto_li, compu {0=Cx0_nicht_betaetigt (CM_KPV_Auto_li_Cx0_nicht_betaetigt), 1=Cx1_betaetigt (CM_KPV_Auto_li_Cx1_betaetigt)}, range raw 0..1, transfer-property=PENDING, to Klima(timeout 3.5 s)  # Auswahl der Funktion Auto li
            signal KPV_Sitzheizung_re_XIX_KPVs_01_XIX_Klima_LIN1: start 24, 3 bit, little-endian, data-type-policy=OVERRIDE, i-signal-type=PRIMITIVE, init-value=0, base-type=BT_KPV_Sitzheizung_re, compu {0=Cx0_Stufe_0 (CM_KPV_Sitzheizung_re_Cx0_Stufe_0), 1=Cx1_Stufe_1 (CM_KPV_Sitzheizung_re_Cx1_Stufe_1), 2=Cx2_Stufe_2 (CM_KPV_Sitzheizung_re_Cx2_Stufe_2), 3=Cx3_Stufe_3 (CM_KPV_Sitzheizung_re_Cx3_Stufe_3), 4=Cx4_Stufe_4 (CM_KPV_Sitzheizung_re_Cx4_Stufe_4), 5=Cx5_Stufe_5 (CM_KPV_Sitzheizung_re_Cx5_Stufe_5), 6=Cx6_Stufe_6 (CM_KPV_Sitzheizung_re_Cx6_Stufe_6)}, range raw 0..6, transfer-property=PENDING, to Klima(timeout 3.5 s)  # Auswahl der Funktion Sitzheizung re
            signal KPV_Sitzlueftung_re_XIX_KPVs_01_XIX_Klima_LIN1: start 27, 3 bit, little-endian, data-type-policy=OVERRIDE, i-signal-type=PRIMITIVE, init-value=0, base-type=BT_KPV_Sitzlueftung_re, compu {0=Cx0_Stufe_0 (CM_KPV_Sitzlueftung_re_Cx0_Stufe_0), 1=Cx1_Stufe_1 (CM_KPV_Sitzlueftung_re_Cx1_Stufe_1), 2=Cx2_Stufe_2 (CM_KPV_Sitzlueftung_re_Cx2_Stufe_2), 3=Cx3_Stufe_3 (CM_KPV_Sitzlueftung_re_Cx3_Stufe_3), 4=Cx4_Stufe_4 (CM_KPV_Sitzlueftung_re_Cx4_Stufe_4), 5=Cx5_Stufe_5 (CM_KPV_Sitzlueftung_re_Cx5_Stufe_5), 6=Cx6_Stufe_6 (CM_KPV_Sitzlueftung_re_Cx6_Stufe_6)}, range raw 0..6, transfer-property=PENDING, to Klima(timeout 3.5 s)  # Auswahl der Funktion Sitzlueftung re
            signal KPV_Kopfraumheizung_re_XIX_KPVs_01_XIX_Klima_LIN1: start 30, 1 bit, little-endian, data-type-policy=OVERRIDE, i-signal-type=PRIMITIVE, init-value=0, base-type=BT_KPV_Kopfraumheizung_re, compu {0=Cx0_nicht_betaetigt (CM_KPV_Kopfraumheizung_re_Cx0_nicht_betaetigt), 1=Cx1_betaetigt (CM_KPV_Kopfraumheizung_re_Cx1_betaetigt)}, range raw 0..1, transfer-property=PENDING, to Klima(timeout 3.5 s)  # Auswahl der Funktion Kopfraumheizung re
            signal KPV_Luftverteilung_Oben_li_XIX_KPVs_01_XIX_Klima_LIN1: start 36, 1 bit, little-endian, data-type-policy=OVERRIDE, i-signal-type=PRIMITIVE, init-value=0, base-type=BT_KPV_Luftverteilung_Oben_li, compu {0=Cx0_nicht_betaetigt (CM_KPV_Luftverteilung_Oben_li_Cx0_nicht_betaetigt), 1=Cx1_betaetigt (CM_KPV_Luftverteilung_Oben_li_Cx1_betaetigt)}, range raw 0..1, transfer-property=PENDING, to Klima(timeout 3.5 s)  # Auswahl der Funktion Luftverteilung Oben li
            signal KPV_Luftverteilung_Mitte_li_XIX_KPVs_01_XIX_Klima_LIN1: start 37, 1 bit, little-endian, data-type-policy=OVERRIDE, i-signal-type=PRIMITIVE, init-value=0, base-type=BT_KPV_Luftverteilung_Mitte_li, compu {0=Cx0_nicht_betaetigt (CM_KPV_Luftverteilung_Mitte_li_Cx0_nicht_betaetigt), 1=Cx1_betaetigt (CM_KPV_Luftverteilung_Mitte_li_Cx1_betaetigt)}, range raw 0..1, transfer-property=PENDING, to Klima(timeout 3.5 s)  # Auswahl der Funktion Luftverteilung Mitte li
            signal KPV_Luftverteilung_Unten_li_XIX_KPVs_01_XIX_Klima_LIN1: start 38, 1 bit, little-endian, data-type-policy=OVERRIDE, i-signal-type=PRIMITIVE, init-value=0, base-type=BT_KPV_Luftverteilung_Unten_li, compu {0=Cx0_nicht_betaetigt (CM_KPV_Luftverteilung_Unten_li_Cx0_nicht_betaetigt), 1=Cx1_betaetigt (CM_KPV_Luftverteilung_Unten_li_Cx1_betaetigt)}, range raw 0..1, transfer-property=PENDING, to Klima(timeout 3.5 s)  # Auswahl der Funktion Luftverteilung Unten li
            signal KPV_Luftverteilung_Auto_li_XIX_KPVs_01_XIX_Klima_LIN1: start 39, 1 bit, little-endian, data-type-policy=OVERRIDE, i-signal-type=PRIMITIVE, init-value=0, base-type=BT_KPV_Luftverteilung_Auto_li, compu {0=Cx0_inaktiv (CM_KPV_Luftverteilung_Auto_li_Cx0_inaktiv), 1=Cx1_aktiv (CM_KPV_Luftverteilung_Auto_li_Cx1_aktiv)}, range raw 0..1, transfer-property=PENDING, to Klima(timeout 3.5 s)  # Auswahl der Funktion Luftverteilung Auto li
            signal KPV_Geblaese_Stufe_li_XIX_KPVs_01_XIX_Klima_LIN1: start 40, 4 bit, little-endian, data-type-policy=OVERRIDE, i-signal-type=PRIMITIVE, init-value=0, base-type=BT_KPV_Geblaese_Stufe_li, compu {0=Cx0_Geblaese_Stufe_0 (CM_KPV_Geblaese_Stufe_li_Cx0_Geblaese_Stufe_0), 1=Cx1_Geblaese_Stufe_1 (CM_KPV_Geblaese_Stufe_li_Cx1_Geblaese_Stufe_1), 2=Cx2_Geblaese_Stufe_2 (CM_KPV_Geblaese_Stufe_li_Cx2_Geblaese_Stufe_2), 3=Cx3_Geblaese_Stufe_3 (CM_KPV_Geblaese_Stufe_li_Cx3_Geblaese_Stufe_3), 4=Cx4_Geblaese_Stufe_4 (CM_KPV_Geblaese_Stufe_li_Cx4_Geblaese_Stufe_4), 5=Cx5_Geblaese_Stufe_5 (CM_KPV_Geblaese_Stufe_li_Cx5_Geblaese_Stufe_5), 6=Cx6_Geblaese_Stufe_6 (CM_KPV_Geblaese_Stufe_li_Cx6_Geblaese_Stufe_6), 7=Cx7_Geblaese_Stufe_7 (CM_KPV_Geblaese_Stufe_li_Cx7_Geblaese_Stufe_7), 8=Cx8_Geblaese_Stufe_8 (CM_KPV_Geblaese_Stufe_li_Cx8_Geblaese_Stufe_8), 9=Cx9_Geblaese_Stufe_9 (CM_KPV_Geblaese_Stufe_li_Cx9_Geblaese_Stufe_9), 10=Cxa_Geblaese_Stufe_10 (CM_KPV_Geblaese_Stufe_li_Cxa_Geblaese_Stufe_10), 11=Cxb_Geblaese_Stufe_11 (CM_KPV_Geblaese_Stufe_li_Cxb_Geblaese_Stufe_11), 12=Cxc_Geblaese_Stufe_12 (CM_KPV_Geblaese_Stufe_li_Cxc_Geblaese_Stufe_12)}, range raw 0..12, transfer-property=PENDING, to Klima(timeout 3.5 s)  # Status Geblaese Stufe links am Klimapanel
            signal KPV_Temp_li_XIX_KPVs_01_XIX_Klima_LIN1: start 48, 8 bit, little-endian, data-type-policy=OVERRIDE, i-signal-type=PRIMITIVE, init-value=0, base-type=BT_KPV_Temp_li, invalid-value=Invalid_KPV_Temp_li_XIX_KPVs_01_XIX_Klima_LIN1:255, compu {phys=raw*0.1+10 for raw 0..254, 255=Cxff_Fehler (CM_KPV_Temp_li_Cxff_Fehler); unit Unit_DegreCelsi}, range phys 10..35.4 Unit_DegreCelsi, raw 0..255, unit=Unit_DegreCelsi, transfer-property=PENDING, to Klima(timeout 3.5 s)  # Eingestellte Temperatur links
            signal KPV_Temp_re_XIX_KPVs_01_XIX_Klima_LIN1: start 56, 8 bit, little-endian, data-type-policy=OVERRIDE, i-signal-type=PRIMITIVE, init-value=0, base-type=BT_KPV_Temp_re, invalid-value=Invalid_KPV_Temp_re_XIX_KPVs_01_XIX_Klima_LIN1:255, compu {phys=raw*0.1+10 for raw 0..254, 255=Cxff_Fehler (CM_KPV_Temp_re_Cxff_Fehler); unit Unit_DegreCelsi}, range phys 10..35.4 Unit_DegreCelsi, raw 0..255, unit=Unit_DegreCelsi, transfer-property=PENDING, to Klima(timeout 3.5 s)  # Eingestellte Temperatur rechts
        frame KPVs_02_XIX_Klima_LIN1: id 0x6, to Klima, frame-length=8, lin-checksum=ENHANCED  # Kopie KPVs_02 mit geänderter Frame-ID wegen ID-Kollision auf Klima_LIN1
          pdu KPVs_02_XIX_Klima_LIN1: length=8, unused-bit-pattern=0  # Kopie KPVs_02 mit geänderter Frame-ID wegen ID-Kollision auf Klima_LIN1
            signal KPV_Init_XIX_KPVs_02_XIX_Klima_LIN1: start 0, 1 bit, little-endian, data-type-policy=OVERRIDE, i-signal-type=PRIMITIVE, init-value=1, base-type=BT_KPV_Init, compu {0=Cx0_Normal_Betrieb (CM_KPV_Init_Cx0_Normal_Betrieb), 1=Cx1_Init (CM_KPV_Init_Cx1_Init)}, range raw 0..1, transfer-property=PENDING, to Klima(timeout 3.5 s)  # KPV_Init zeigt eine Initialisierung / Reset des KPVs an
            signal KPV_Lokalaktiv_XIX_KPVs_02_XIX_Klima_LIN1: start 1, 1 bit, little-endian, data-type-policy=OVERRIDE, i-signal-type=PRIMITIVE, init-value=0, base-type=BT_KPV_Lokalaktiv, compu {0=Cx0_war_nicht_lokal_aktiv (CM_KPV_Lokalaktiv_Cx0_war_nicht_lokal_aktiv), 1=Cx1_war_lokal_aktiv (CM_KPV_Lokalaktiv_Cx1_war_lokal_aktiv)}, range raw 0..1, transfer-property=PENDING, to Klima(timeout 3.5 s)
            signal KPV_HSH_Taste_XIX_KPVs_02_XIX_Klima_LIN1: start 2, 2 bit, little-endian, data-type-policy=OVERRIDE, i-signal-type=PRIMITIVE, init-value=0, base-type=BT_KPV_HSH_Taste, compu {0=Cx0_nicht_betaetigt (CM_KPV_HSH_Taste_Cx0_nicht_betaetigt), 1=Cx1_betaetigt (CM_KPV_HSH_Taste_Cx1_betaetigt), 2=Cx2_long_push (CM_KPV_HSH_Taste_Cx2_long_push), 3=Cx3_klemmt (CM_KPV_HSH_Taste_Cx3_klemmt)}, range raw 0..3, transfer-property=PENDING, to Klima(timeout 3.5 s)  # Tastendrucksignal für die Heckscheibenheizungstaste im Klimapanel Vorn
            signal KPV_Auto_Taste_XIX_KPVs_02_XIX_Klima_LIN1: start 4, 2 bit, little-endian, data-type-policy=OVERRIDE, i-signal-type=PRIMITIVE, init-value=0, base-type=BT_KPV_Auto_Taste, compu {0=Cx0_nicht_betaetigt (CM_KPV_Auto_Taste_Cx0_nicht_betaetigt), 1=Cx1_betaetigt (CM_KPV_Auto_Taste_Cx1_betaetigt), 2=Cx2_long_push (CM_KPV_Auto_Taste_Cx2_long_push), 3=Cx3_klemmt (CM_KPV_Auto_Taste_Cx3_klemmt)}, range raw 0..3, transfer-property=PENDING, to Klima(timeout 3.5 s)  # Tastendrucksignal des Klimapanel Vorn auf der Auto-Taste
            signal KPV_AC_Taste_XIX_KPVs_02_XIX_Klima_LIN1: start 6, 2 bit, little-endian, data-type-policy=OVERRIDE, i-signal-type=PRIMITIVE, init-value=0, base-type=BT_KPV_AC_Taste, compu {0=Cx0_nicht_betaetigt (CM_KPV_AC_Taste_Cx0_nicht_betaetigt), 1=Cx1_betaetigt (CM_KPV_AC_Taste_Cx1_betaetigt), 2=Cx2_long_push (CM_KPV_AC_Taste_Cx2_long_push), 3=Cx3_klemmt (CM_KPV_AC_Taste_Cx3_klemmt)}, range raw 0..3, transfer-property=PENDING, to Klima(timeout 3.5 s)  # Tastendrucksignal der AC-Taste über das Klimapanel vorne
            signal KPV_DefrostMAX_Taste_XIX_KPVs_02_XIX_Klima_LIN1: start 8, 2 bit, little-endian, data-type-policy=OVERRIDE, i-signal-type=PRIMITIVE, init-value=0, base-type=BT_KPV_DefrostMAX_Taste, compu {0=Cx0_nicht_betaetigt (CM_KPV_DefrostMAX_Taste_Cx0_nicht_betaetigt), 1=Cx1_betaetigt (CM_KPV_DefrostMAX_Taste_Cx1_betaetigt), 2=Cx2_long_push (CM_KPV_DefrostMAX_Taste_Cx2_long_push), 3=Cx3_klemmt (CM_KPV_DefrostMAX_Taste_Cx3_klemmt)}, range raw 0..3, transfer-property=PENDING, to Klima(timeout 3.5 s)  # Tastendrucksignal der DefrostMAX-Taste des Klima-Panels vorne
            signal KPV_Zustand_Off_XIX_KPVs_02_XIX_Klima_LIN1: start 10, 1 bit, little-endian, data-type-policy=OVERRIDE, i-signal-type=PRIMITIVE, init-value=1, base-type=BT_KPV_Zustand_Off, compu {0=Cx0_Panel_On (CM_KPV_Zustand_Off_Cx0_Panel_On), 1=Cx1_Panel_Off (CM_KPV_Zustand_Off_Cx1_Panel_Off)}, range raw 0..1, transfer-property=PENDING, to Klima(timeout 3.5 s)  # Zustand des Klimapanel vorne On/Off
            signal KPV_Popup_Content_ZL1R_XIX_KPVs_02_XIX_Klima_LIN1: start 16, 4 bit, little-endian, data-type-policy=OVERRIDE, i-signal-type=PRIMITIVE, init-value=15, base-type=BT_KPV_Popup_Content_ZL1R, compu {0=Cx0_Air_Distribution (CM_KPV_Popup_Content_ZL1R_Cx0_Air_Distribution), 1=Cx1_Temperature (CM_KPV_Popup_Content_ZL1R_Cx1_Temperature), 2=Cx2_Seat_Heater (CM_KPV_Popup_Content_ZL1R_Cx2_Seat_Heater), 3=Cx3_Seat_Ventilation (CM_KPV_Popup_Content_ZL1R_Cx3_Seat_Ventilation), 4=Cx4_Air_Volume (CM_KPV_Popup_Content_ZL1R_Cx4_Air_Volume), 5=Cx5_reserved (CM_KPV_Popup_Content_ZL1R_Cx5_reserved), 6=Cx6_reserved (CM_KPV_Popup_Content_ZL1R_Cx6_reserved), 7=Cx7_reserved (CM_KPV_Popup_Content_ZL1R_Cx7_reserved), 8=Cx8_reserved (CM_KPV_Popup_Content_ZL1R_Cx8_reserved), 9=Cx9_reserved (CM_KPV_Popup_Content_ZL1R_Cx9_reserved), 10=Cxa_reserved (CM_KPV_Popup_Content_ZL1R_Cxa_reserved), 11=Cxb_reserved (CM_KPV_Popup_Content_ZL1R_Cxb_reserved), 12=Cxc_reserved (CM_KPV_Popup_Content_ZL1R_Cxc_reserved), 13=Cxd_reserved (CM_KPV_Popup_Content_ZL1R_Cxd_reserved), 14=Cxe_reserved (CM_KPV_Popup_Content_ZL1R_Cxe_reserved), 15=Cxf_No_Display (CM_KPV_Popup_Content_ZL1R_Cxf_No_Display)}, range raw 0..15, transfer-property=PENDING, to Klima(timeout 3.5 s)  # PopUp Steuerung RotaryKnobs SKODA
            signal KPV_Popup_Content_ZR1R_XIX_KPVs_02_XIX_Klima_LIN1: start 20, 4 bit, little-endian, data-type-policy=OVERRIDE, i-signal-type=PRIMITIVE, init-value=15, base-type=BT_KPV_Popup_Content_ZR1R, compu {0=Cx0_Air_Distribution (CM_KPV_Popup_Content_ZR1R_Cx0_Air_Distribution), 1=Cx1_Temperature (CM_KPV_Popup_Content_ZR1R_Cx1_Temperature), 2=Cx2_Seat_Heater (CM_KPV_Popup_Content_ZR1R_Cx2_Seat_Heater), 3=Cx3_Seat_Ventilation (CM_KPV_Popup_Content_ZR1R_Cx3_Seat_Ventilation), 4=Cx4_Air_Volume (CM_KPV_Popup_Content_ZR1R_Cx4_Air_Volume), 5=Cx5_Reserved (CM_KPV_Popup_Content_ZR1R_Cx5_Reserved), 6=Cx6_Reserved (CM_KPV_Popup_Content_ZR1R_Cx6_Reserved), 7=Cx7_Reserved (CM_KPV_Popup_Content_ZR1R_Cx7_Reserved), 8=Cx8_Reserved (CM_KPV_Popup_Content_ZR1R_Cx8_Reserved), 9=Cx9_Reserved (CM_KPV_Popup_Content_ZR1R_Cx9_Reserved), 10=Cxa_Reserved (CM_KPV_Popup_Content_ZR1R_Cxa_Reserved), 11=Cxb_Reserved (CM_KPV_Popup_Content_ZR1R_Cxb_Reserved), 12=Cxc_Reserved (CM_KPV_Popup_Content_ZR1R_Cxc_Reserved), 13=Cxd_Reserved (CM_KPV_Popup_Content_ZR1R_Cxd_Reserved), 14=Cxe_Reserved (CM_KPV_Popup_Content_ZR1R_Cxe_Reserved), 15=Cxf_No_Display (CM_KPV_Popup_Content_ZR1R_Cxf_No_Display)}, range raw 0..15, transfer-property=PENDING, to Klima(timeout 3.5 s)  # PopUp Steuerung der RotaryKnobs
            signal KPV_Tasten_Fehler_XIX_KPVs_02_XIX_Klima_LIN1: start 24, 1 bit, little-endian, data-type-policy=OVERRIDE, i-signal-type=PRIMITIVE, init-value=0, base-type=BT_KPV_Tasten_Fehler, invalid-value=Invalid_KPV_Tasten_Fehler_XIX_KPVs_02_XIX_Klima_LIN1:1, compu {0=Cx0_kein_Fehler (CM_KPV_Tasten_Fehler_Cx0_kein_Fehler), 1=Cx1_Fehler (CM_KPV_Tasten_Fehler_Cx1_Fehler)}, range raw 0..1, transfer-property=PENDING, to Klima(timeout 3.5 s)  # Auswertung Entprellung
            signal KPV_Panel_Error_XIX_KPVs_02_XIX_Klima_LIN1: start 26, 4 bit, little-endian, data-type-policy=OVERRIDE, i-signal-type=PRIMITIVE, init-value=0, base-type=BT_KPV_Panel_Error, compu {0=Cx0_kein_Fehler (CM_KPV_Panel_Error_Cx0_kein_Fehler)}, range raw 0, transfer-property=PENDING, to Klima(timeout 3.5 s)
            signal KPV_ResponseError_XIX_KPVs_02_XIX_Klima_LIN1: start 30, 1 bit, little-endian, data-type-policy=OVERRIDE, i-signal-type=PRIMITIVE, init-value=0, base-type=BT_KPV_ResponseError, invalid-value=Invalid_KPV_ResponseError_XIX_KPVs_02_XIX_Klima_LIN1:1, compu {0=Cx0_normal (CM_KPV_ResponseError_Cx0_normal), 1=Cx1_Fehler (CM_KPV_ResponseError_Cx1_Fehler)}, range raw 0..1, transfer-property=PENDING, to Klima(timeout 3.5 s)
            signal KPV_PureAir_XIX_KPVs_02_XIX_Klima_LIN1: start 31, 1 bit, little-endian, data-type-policy=OVERRIDE, i-signal-type=PRIMITIVE, init-value=0, base-type=BT_KPV_PureAir, compu {0=Cx0_nicht_betaetigt (CM_KPV_PureAir_Cx0_nicht_betaetigt), 1=Cx1_betaetigt (CM_KPV_PureAir_Cx1_betaetigt)}, range raw 0..1, transfer-property=PENDING, to Klima(timeout 3.5 s)  # Auswahl der Funktion PureAir
            signal KPV_Temp_Platine_XIX_KPVs_02_XIX_Klima_LIN1: start 32, 8 bit, little-endian, data-type-policy=OVERRIDE, i-signal-type=PRIMITIVE, init-value=254, base-type=BT_KPV_Temp_Platine, invalid-value=Invalid_KPV_Temp_Platine_XIX_KPVs_02_XIX_Klima_LIN1:255, compu {phys=raw-50 for raw 0..180, 254=Cxfe_Init (CM_KPV_Temp_Platine_Cxfe_Init), 255=Cxff_Fehler (CM_KPV_Temp_Platine_Cxff_Fehler); unit Unit_DegreCelsi}, range phys -50..130 Unit_DegreCelsi, raw 0..255, unit=Unit_DegreCelsi, transfer-property=PENDING, to Klima(timeout 3.5 s)
            signal KPV_OBD_XIX_KPVs_02_XIX_Klima_LIN1: start 43, 3 bit, little-endian, data-type-policy=OVERRIDE, i-signal-type=PRIMITIVE, init-value=0, base-type=BT_KPV_OBD, compu {0=Cx0_OBD_off (CM_KPV_OBD_Cx0_OBD_off), 1=Cx1_OBD_active (CM_KPV_OBD_Cx1_OBD_active), 2=Cx2_OBD_toggle_request (CM_KPV_OBD_Cx2_OBD_toggle_request), 3=Cx3_OBD_discard_all (CM_KPV_OBD_Cx3_OBD_discard_all), 4=Cx4_OBD_discard_all_but_current (CM_KPV_OBD_Cx4_OBD_discard_all_but_current), 5=Cx5_reserved (CM_KPV_OBD_Cx5_reserved), 6=Cx6_reserved (CM_KPV_OBD_Cx6_reserved), 7=Cx7_reserved (CM_KPV_OBD_Cx7_reserved)}, range raw 0..7, transfer-property=PENDING, to Klima(timeout 3.5 s)  # Anforderung/Status vom Klimapanel an das Klima-SG
            signal KPV_OBD_Gruppe_XIX_KPVs_02_XIX_Klima_LIN1: start 46, 4 bit, little-endian, data-type-policy=OVERRIDE, i-signal-type=PRIMITIVE, init-value=0, base-type=BT_KPV_OBD_Gruppe, compu {phys=raw for raw 0..15; unit Unit_None}, range phys 0..15 Unit_None, raw 0..15, unit=Unit_None, transfer-property=PENDING, to Klima(timeout 3.5 s)  # Signalrückmeldung welche OnBoard-Diagnosegruppe ist derzeit im KPV aktiv
            signal KPV_AutoUmluft_XIX_KPVs_02_XIX_Klima_LIN1: start 50, 1 bit, little-endian, data-type-policy=OVERRIDE, i-signal-type=PRIMITIVE, init-value=0, base-type=BT_KPV_AutoUmluft, compu {0=Cx0_inaktiv (CM_KPV_AutoUmluft_Cx0_inaktiv), 1=Cx1_aktiv (CM_KPV_AutoUmluft_Cx1_aktiv)}, range raw 0..1, transfer-property=PENDING, to Klima(timeout 3.5 s)  # Rückmeldung des Klima-Panels ob die Funktion „Auto-Umluft“ aktiv ist.
            signal KPV_Konditionierung_Taste_XIX_KPVs_02_XIX_Klima_LIN1: start 51, 1 bit, little-endian, data-type-policy=OVERRIDE, i-signal-type=PRIMITIVE, init-value=0, base-type=BT_KPV_Konditionierung_Taste, compu {0=Cx0_nicht_betaetigt (CM_KPV_Konditionierung_Taste_Cx0_nicht_betaetigt), 1=Cx1_betaetigt (CM_KPV_Konditionierung_Taste_Cx1_betaetigt)}, range raw 0..1, transfer-property=PENDING, to Klima(timeout 3.5 s)  # Tastendrucksignal für die Funktion der Vorkonditionierung und Standheizung
            signal KPV_AutoSiKli_li_XIX_KPVs_02_XIX_Klima_LIN1: start 57, 1 bit, little-endian, data-type-policy=OVERRIDE, i-signal-type=PRIMITIVE, init-value=0, base-type=BT_KPV_AutoSiKli_li, compu {0=Cx0_OFF (CM_KPV_AutoSiKli_li_Cx0_OFF), 1=Cx1_ON (CM_KPV_AutoSiKli_li_Cx1_ON)}, range raw 0..1, transfer-property=PENDING, to Klima(timeout 3.5 s)  # Auswahl für Funktion Automatische Sitzklimatisierung links am Klimapanel
            signal KPV_AutoSiKli_re_XIX_KPVs_02_XIX_Klima_LIN1: start 58, 1 bit, little-endian, data-type-policy=OVERRIDE, i-signal-type=PRIMITIVE, init-value=0, base-type=BT_KPV_AutoSiKli_re, compu {0=Cx0_OFF (CM_KPV_AutoSiKli_re_Cx0_OFF), 1=Cx1_ON (CM_KPV_AutoSiKli_re_Cx1_ON)}, range raw 0..1, transfer-property=PENDING, to Klima(timeout 3.5 s)  # Auswahl für Funktion Automatische Sitzklimatisierung rechts am Klimapanel
            signal KPV_Geblaese_Auto_li_XIX_KPVs_02_XIX_Klima_LIN1: start 60, 1 bit, little-endian, data-type-policy=OVERRIDE, i-signal-type=PRIMITIVE, init-value=0, base-type=BT_KPV_Geblaese_Auto_li, compu {0=Cx0_inaktiv (CM_KPV_Geblaese_Auto_li_Cx0_inaktiv), 1=Cx1_aktiv (CM_KPV_Geblaese_Auto_li_Cx1_aktiv)}, range raw 0..1, transfer-property=PENDING, to Klima(timeout 3.5 s)  # Statusanzeige der Funktion Gebläse Auto links
            signal KPV_Status_Spannung_XIX_KPVs_02_XIX_Klima_LIN1: start 62, 2 bit, little-endian, data-type-policy=OVERRIDE, i-signal-type=PRIMITIVE, init-value=1, base-type=BT_KPV_Status_Spannung, compu {0=Cx0_Spannung_ok (CM_KPV_Status_Spannung_Cx0_Spannung_ok), 1=Cx1_Init_ungetestet (CM_KPV_Status_Spannung_Cx1_Init_ungetestet), 2=Cx2_Unterspannung (CM_KPV_Status_Spannung_Cx2_Unterspannung), 3=Cx3_Ueberspannung (CM_KPV_Status_Spannung_Cx3_Ueberspannung)}, range raw 0..3, transfer-property=PENDING, to Klima(timeout 3.5 s)  # Status Kl.30 Klimapanel vorne
        frame MasterReq_XIX_Klima_LIN1: id 0x3C, from Klima, frame-length=8, lin-checksum=CLASSIC
          n pdu MasterReq_XIX_Klima_LIN1: length=8
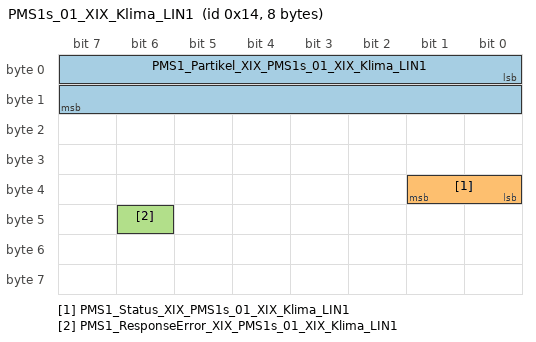
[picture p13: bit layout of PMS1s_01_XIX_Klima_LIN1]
        frame PMS1s_01_XIX_Klima_LIN1: id 0x14, to Klima, frame-length=8, lin-checksum=ENHANCED
          pdu PMS1s_01_XIX_Klima_LIN1: length=8, unused-bit-pattern=0
            signal PMS1_Partikel_XIX_PMS1s_01_XIX_Klima_LIN1: start 0, 16 bit, little-endian, data-type-policy=OVERRIDE, i-signal-type=PRIMITIVE, init-value=65534, base-type=BT_PMS1_Partikel, invalid-value=Invalid_PMS1_Partikel_XIX_PMS1s_01_XIX_Klima_LIN1:65535, compu {phys=raw for raw 0..65533, 65534=Cxfffe_Init (CM_PMS1_Partikel_Cxfffe_Init), 65535=Cxffff_Fehler (CM_PMS1_Partikel_Cxffff_Fehler)}, range phys 0..65533, raw 0..65535, transfer-property=PENDING, to Klima(timeout 3.5 s)  # Partikelmassenkonzentration (ug/m3)
            signal PMS1_Status_XIX_PMS1s_01_XIX_Klima_LIN1: start 32, 2 bit, little-endian, data-type-policy=OVERRIDE, i-signal-type=PRIMITIVE, init-value=0, base-type=BT_PMS1_Status, compu {0=Cx0_kein_Fehler (CM_PMS1_Status_Cx0_kein_Fehler), 1=Cx1_eingeschraenkter_Betrieb (CM_PMS1_Status_Cx1_eingeschraenkter_Betrieb), 2=Cx2_Funktion_gestoppt (CM_PMS1_Status_Cx2_Funktion_gestoppt), 3=Cx3_Steuergeraet_defekt (CM_PMS1_Status_Cx3_Steuergeraet_defekt)}, range raw 0..3, transfer-property=PENDING, to Klima(timeout 3.5 s)  # eingeschraenkter Betrieb: Funktion nicht optimal, aber kein kritischer Zustand (z.B. starke Verschmutzung der HV-Nadel) Funktion_gestoppt: zeitweiser Funktionsstopp. Kann z.B. nach einem Kl.15-Wechsel oder geänderten klimatischen Verhältnissen wieder geheilt sein.
            signal PMS1_ResponseError_XIX_PMS1s_01_XIX_Klima_LIN1: start 46, 1 bit, little-endian, data-type-policy=OVERRIDE, i-signal-type=PRIMITIVE, init-value=0, base-type=BT_PMS1_ResponseError, invalid-value=Invalid_PMS1_ResponseError_XIX_PMS1s_01_XIX_Klima_LIN1:1, compu {0=Cx0_normal (CM_PMS1_ResponseError_Cx0_normal), 1=Cx1_Fehler (CM_PMS1_ResponseError_Cx1_Fehler)}, range raw 0..1, transfer-property=PENDING, to Klima(timeout 3.5 s)  # siehe LIN2.0-Spezifikation (Darf nicht über ein Fehlergueltigkeitsbit abgesichert werden!)
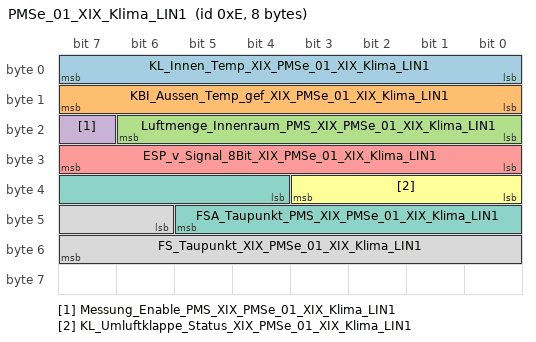
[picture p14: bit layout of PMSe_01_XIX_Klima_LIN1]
        frame PMSe_01_XIX_Klima_LIN1: id 0xE, from Klima, frame-length=8, lin-checksum=ENHANCED
          pdu PMSe_01_XIX_Klima_LIN1: length=8, unused-bit-pattern=0
            signal KL_Innen_Temp_XIX_PMSe_01_XIX_Klima_LIN1: start 0, 8 bit, little-endian, data-type-policy=OVERRIDE, i-signal-type=PRIMITIVE, init-value=254, base-type=BT_KL_Innen_Temp, invalid-value=Invalid_KL_Innen_Temp_XIX_PMSe_01_XIX_Klima_LIN1:255, compu {phys=raw*0.5-50 for raw 0..252, 253=Cxfd_nicht_verbaut (CM_KL_Innen_Temp_Cxfd_nicht_verbaut), 254=Cxfe_nicht_verfuegbar (CM_KL_Innen_Temp_Cxfe_nicht_verfuegbar), 255=Cxff_Fehler (CM_KL_Innen_Temp_Cxff_Fehler); unit Unit_DegreCelsi}, range phys -50..76 Unit_DegreCelsi, raw 0..255, unit=Unit_DegreCelsi, transfer-property=PENDING  # Innentemperatur
            signal KBI_Aussen_Temp_gef_XIX_PMSe_01_XIX_Klima_LIN1: start 8, 8 bit, little-endian, data-type-policy=OVERRIDE, i-signal-type=PRIMITIVE, init-value=254, base-type=BT_KBI_Aussen_Temp_gef, invalid-value=Invalid_KBI_Aussen_Temp_gef_XIX_PMSe_01_XIX_Klima_LIN1:255, compu {phys=raw*0.5-50 for raw 0..250, 253=Cxfd_nicht_verbaut (CM_KBI_Aussen_Temp_gef_Cxfd_nicht_verbaut) (nicht verbaut), 254=Cxfe_Init (CM_KBI_Aussen_Temp_gef_Cxfe_Init), 255=Cxff_Fehler (CM_KBI_Aussen_Temp_gef_Cxff_Fehler); unit Unit_DegreCelsi}, range phys -50..75 Unit_DegreCelsi, raw 0..255, unit=Unit_DegreCelsi, transfer-property=PENDING
            signal Luftmenge_Innenraum_PMS_XIX_PMSe_01_XIX_Klima_LIN1: start 16, 7 bit, little-endian, data-type-policy=OVERRIDE, i-signal-type=PRIMITIVE, init-value=0, base-type=BT_Luftmenge_Innenraum_PMS, compu {phys=raw for raw 0..100; unit Unit_PerCent}, range phys 0..100 Unit_PerCent, raw 0..100, unit=Unit_PerCent, transfer-property=PENDING  # Luftmenge in den Innenraum
            signal Messung_Enable_PMS_XIX_PMSe_01_XIX_Klima_LIN1: start 23, 1 bit, little-endian, data-type-policy=OVERRIDE, i-signal-type=PRIMITIVE, init-value=0, base-type=BT_Messung_Enable_PMS, compu {0=Cx0_nicht_aktiv (CM_Messung_Enable_PMS_Cx0_nicht_aktiv), 1=Cx1_aktiv (CM_Messung_Enable_PMS_Cx1_aktiv)}, range raw 0..1, transfer-property=PENDING  # Trigger des LIN-Masters, dass Messungen erfolgen sollen.
            signal ESP_v_Signal_8Bit_XIX_PMSe_01_XIX_Klima_LIN1: start 24, 8 bit, little-endian, data-type-policy=OVERRIDE, i-signal-type=PRIMITIVE, init-value=254, base-type=BT_ESP_v_Signal_8Bit, compu {phys=raw*2.56 for raw 0..253, 254=Cxfe_Init (CM_ESP_v_Signal_8Bit_Cxfe_Init), 255=Cxff_Fehler (CM_ESP_v_Signal_8Bit_Cxff_Fehler); unit Unit_KiloMeterPerHour}, range phys 0..647.68 Unit_KiloMeterPerHour, raw 0..255, unit=Unit_KiloMeterPerHour, transfer-property=PENDING
            signal KL_Umluftklappe_Status_XIX_PMSe_01_XIX_Klima_LIN1: start 32, 4 bit, little-endian, data-type-policy=OVERRIDE, i-signal-type=PRIMITIVE, init-value=14, base-type=BT_KL_Umluftklappe_Status, invalid-value=Invalid_KL_Umluftklappe_Status_XIX_PMSe_01_XIX_Klima_LIN1:15, compu {0=Cx0_Frischluft (CM_KL_Umluftklappe_Status_Cx0_Frischluft), 1=Cx1_Teilumluft_10 (CM_KL_Umluftklappe_Status_Cx1_Teilumluft_10), 2=Cx2_Teilumluft_20 (CM_KL_Umluftklappe_Status_Cx2_Teilumluft_20), 3=Cx3_Teilumluft_30 (CM_KL_Umluftklappe_Status_Cx3_Teilumluft_30), 4=Cx4_Teilumluft_40 (CM_KL_Umluftklappe_Status_Cx4_Teilumluft_40), 5=Cx5_Teilumluft_50 (CM_KL_Umluftklappe_Status_Cx5_Teilumluft_50), 6=Cx6_Teilumluft_60 (CM_KL_Umluftklappe_Status_Cx6_Teilumluft_60), 7=Cx7_Teilumluft_70 (CM_KL_Umluftklappe_Status_Cx7_Teilumluft_70), 8=Cx8_Teilumluft_80 (CM_KL_Umluftklappe_Status_Cx8_Teilumluft_80), 9=Cx9_Teilumluft_90 (CM_KL_Umluftklappe_Status_Cx9_Teilumluft_90), 10=Cxa_Umluft (CM_KL_Umluftklappe_Status_Cxa_Umluft), 14=Cxe_Init (CM_KL_Umluftklappe_Status_Cxe_Init), 15=Cxf_Fehler (CM_KL_Umluftklappe_Status_Cxf_Fehler)}, range raw 0..15, transfer-property=PENDING  # Status Umluftklappe
            signal FSA_Taupunkt_PMS_XIX_PMSe_01_XIX_Klima_LIN1: start 36, 10 bit, little-endian, data-type-policy=OVERRIDE, i-signal-type=PRIMITIVE, init-value=1022, base-type=BT_FSA_Taupunkt_PMS, invalid-value=Invalid_FSA_Taupunkt_PMS_XIX_PMSe_01_XIX_Klima_LIN1:1023, compu {phys=raw*0.1-40 for raw 0..1000, 1021=Cx3fd_nicht_verbaut (CM_FSA_Taupunkt_PMS_Cx3fd_nicht_verbaut), 1022=Cx3fe_Init (CM_FSA_Taupunkt_PMS_Cx3fe_Init), 1023=Cx3ff_Fehler (CM_FSA_Taupunkt_PMS_Cx3ff_Fehler); unit Unit_DegreCelsi}, range phys -40..60 Unit_DegreCelsi, raw 0..1023, unit=Unit_DegreCelsi, transfer-property=PENDING  # 'Init' falls nicht verbaut
            signal FS_Taupunkt_XIX_PMSe_01_XIX_Klima_LIN1: start 46, 10 bit, little-endian, data-type-policy=OVERRIDE, i-signal-type=PRIMITIVE, init-value=0, base-type=BT_FS_Taupunkt, invalid-value=Invalid_FS_Taupunkt_XIX_PMSe_01_XIX_Klima_LIN1:1023, compu {0=Cx0_nicht_verfuegbar (CM_FS_Taupunkt_Cx0_nicht_verfuegbar) (nicht verfuegbar), phys=raw*0.1-39.6 for raw 1..1000, 1023=Cx3ff_Fehler (CM_FS_Taupunkt_Cx3ff_Fehler); unit Unit_DegreCelsi}, range phys -39.5..60.4 Unit_DegreCelsi, raw 0..1023, unit=Unit_DegreCelsi, transfer-property=PENDING  # berechneter Taupunkt
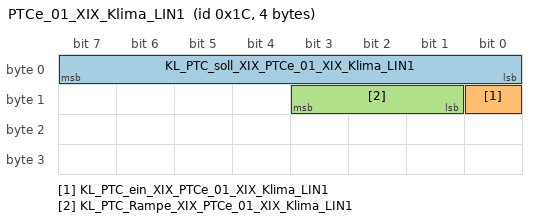
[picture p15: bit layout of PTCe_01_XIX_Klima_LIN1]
        frame PTCe_01_XIX_Klima_LIN1: id 0x1C, from Klima, frame-length=4, lin-checksum=ENHANCED
          pdu PTCe_01_XIX_Klima_LIN1: length=4, unused-bit-pattern=0
            signal KL_PTC_soll_XIX_PTCe_01_XIX_Klima_LIN1: start 0, 8 bit, little-endian, data-type-policy=OVERRIDE, i-signal-type=PRIMITIVE, init-value=254, base-type=BT_KL_PTC_soll, compu {phys=raw*10 for raw 0..253, 254=Cxfe_Init (CM_KL_PTC_soll_Cxfe_Init), 255=Cxff_Fehler (CM_KL_PTC_soll_Cxff_Fehler); unit Unit_Watt}, range phys 0..2530 Unit_Watt, raw 0..255, unit=Unit_Watt, transfer-property=PENDING  # Calculated maximum PTC Heater Power coming from Motor ECU
            signal KL_PTC_ein_XIX_PTCe_01_XIX_Klima_LIN1: start 8, 1 bit, little-endian, data-type-policy=OVERRIDE, i-signal-type=PRIMITIVE, init-value=0, base-type=BT_KL_PTC_ein, compu {0=Cx0_Aus (CM_KL_PTC_ein_Cx0_Aus), 1=Cx1_Ein (CM_KL_PTC_ein_Cx1_Ein)}, range raw 0..1, transfer-property=PENDING  # PTC Aus_Ein
            signal KL_PTC_Rampe_XIX_PTCe_01_XIX_Klima_LIN1: start 9, 3 bit, little-endian, data-type-policy=OVERRIDE, i-signal-type=PRIMITIVE, init-value=0, base-type=BT_KL_PTC_Rampe, compu {phys=raw*50 for raw 0..7; unit Unit_WattPerSecon}, range phys 0..350 Unit_WattPerSecon, raw 0..7, unit=Unit_WattPerSecon, transfer-property=PENDING  # PTC Leistungszunahme
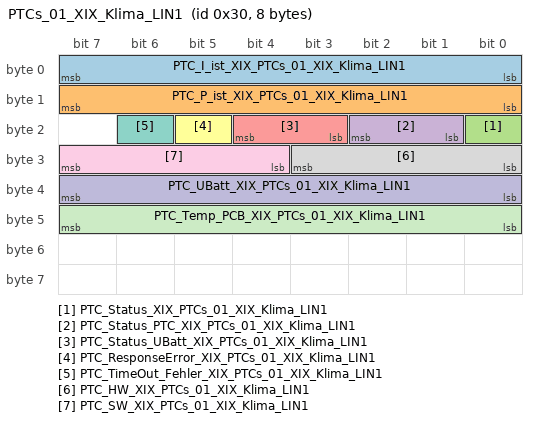
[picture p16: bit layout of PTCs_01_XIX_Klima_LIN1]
        frame PTCs_01_XIX_Klima_LIN1: id 0x30, to Klima, frame-length=8, lin-checksum=ENHANCED
          pdu PTCs_01_XIX_Klima_LIN1: length=8, unused-bit-pattern=0
            signal PTC_I_ist_XIX_PTCs_01_XIX_Klima_LIN1: start 0, 8 bit, little-endian, data-type-policy=OVERRIDE, i-signal-type=PRIMITIVE, init-value=254, base-type=BT_PTC_I_ist, compu {phys=raw for raw 0..253, 254=Cxfe_Init (CM_PTC_I_ist_Cxfe_Init), 255=Cxff_Fehler (CM_PTC_I_ist_Cxff_Fehler); unit Unit_Amper}, range phys 0..253 Unit_Amper, raw 0..255, unit=Unit_Amper, transfer-property=PENDING, to Klima(timeout 3.5 s)  # PTC Stromverbrauch (max. 120A)
            signal PTC_P_ist_XIX_PTCs_01_XIX_Klima_LIN1: start 8, 8 bit, little-endian, data-type-policy=OVERRIDE, i-signal-type=PRIMITIVE, init-value=254, base-type=BT_PTC_P_ist, compu {phys=raw*10 for raw 0..253, 254=Cxfe_Init (CM_PTC_P_ist_Cxfe_Init), 255=Cxff_Fehler (CM_PTC_P_ist_Cxff_Fehler); unit Unit_Watt}, range phys 0..2530 Unit_Watt, raw 0..255, unit=Unit_Watt, transfer-property=PENDING, to Klima(timeout 3.5 s)  # PTC Leistungsaufnahme
            signal PTC_Status_XIX_PTCs_01_XIX_Klima_LIN1: start 16, 1 bit, little-endian, data-type-policy=OVERRIDE, i-signal-type=PRIMITIVE, init-value=0, base-type=BT_PTC_Status, compu {0=Cx0_Aus (CM_PTC_Status_Cx0_Aus), 1=Cx1_Ein (CM_PTC_Status_Cx1_Ein)}, range raw 0..1, transfer-property=PENDING, to Klima(timeout 3.5 s)  # PTC Aus/Ein Status
            signal PTC_Status_PTC_XIX_PTCs_01_XIX_Klima_LIN1: start 17, 2 bit, little-endian, data-type-policy=OVERRIDE, i-signal-type=PRIMITIVE, init-value=3, base-type=BT_PTC_Status_PTC, compu {0=Cx0_PTC_OK (CM_PTC_Status_PTC_Cx0_PTC_OK), 1=Cx1_PTC_defekt (CM_PTC_Status_PTC_Cx1_PTC_defekt), 2=Cx2_PTC_Control_Modul_overheated_PTC_shut_down (CM_PTC_Status_PTC_Cx2_PTC_Control_Modul_overheated_PTC_shut_down) (PTC_Control_Modul_overheated__PTC_shut_down), 3=Cx3_Init (CM_PTC_Status_PTC_Cx3_Init)}, range raw 0..3, transfer-property=PENDING, to Klima(timeout 3.5 s)  # Status der PTC Heizeinheit
            signal PTC_Status_UBatt_XIX_PTCs_01_XIX_Klima_LIN1: start 19, 2 bit, little-endian, data-type-policy=OVERRIDE, i-signal-type=PRIMITIVE, init-value=3, base-type=BT_PTC_Status_UBatt, compu {0=Cx0_Batterie_OK (CM_PTC_Status_UBatt_Cx0_Batterie_OK), 1=Cx1_Unterspannung (CM_PTC_Status_UBatt_Cx1_Unterspannung), 2=Cx2_Ueberspannung (CM_PTC_Status_UBatt_Cx2_Ueberspannung), 3=Cx3_Init (CM_PTC_Status_UBatt_Cx3_Init)}, range raw 0..3, transfer-property=PENDING, to Klima(timeout 3.5 s)  # Status der Batteriespannung
            signal PTC_ResponseError_XIX_PTCs_01_XIX_Klima_LIN1: start 21, 1 bit, little-endian, data-type-policy=OVERRIDE, i-signal-type=PRIMITIVE, init-value=0, base-type=BT_PTC_ResponseError, invalid-value=Invalid_PTC_ResponseError_XIX_PTCs_01_XIX_Klima_LIN1:1, compu {0=Cx0_normal (CM_PTC_ResponseError_Cx0_normal), 1=Cx1_Fehler (CM_PTC_ResponseError_Cx1_Fehler)}, range raw 0..1, transfer-property=PENDING, to Klima(timeout 3.5 s)  # siehe LIN2.0-Specification (Darf nicht über ein Fehlergueltigkeitsbit abgesichtert werden!)
            signal PTC_TimeOut_Fehler_XIX_PTCs_01_XIX_Klima_LIN1: start 22, 1 bit, little-endian, data-type-policy=OVERRIDE, i-signal-type=PRIMITIVE, init-value=0, base-type=BT_PTC_TimeOut_Fehler, compu {0=Cx0_no_timeout (CM_PTC_TimeOut_Fehler_Cx0_no_timeout), 1=Cx1_timeout_detected (CM_PTC_TimeOut_Fehler_Cx1_timeout_detected)}, range raw 0..1, transfer-property=PENDING, to Klima(timeout 3.5 s)  # TPC hat zu lange keine Empfangsframes mehr erhalten (Dieser Fehler muss nicht über einen Fehlergueltigkeitsbit abgesichert werden).
            signal PTC_HW_XIX_PTCs_01_XIX_Klima_LIN1: start 24, 4 bit, little-endian, data-type-policy=OVERRIDE, i-signal-type=PRIMITIVE, init-value=0, base-type=BT_PTC_HW, compu {phys=raw for raw 0..15; unit Unit_None}, range phys 0..15 Unit_None, raw 0..15, unit=Unit_None, transfer-property=PENDING, to Klima(timeout 3.5 s)  # PTC Hardware Version
            signal PTC_SW_XIX_PTCs_01_XIX_Klima_LIN1: start 28, 4 bit, little-endian, data-type-policy=OVERRIDE, i-signal-type=PRIMITIVE, init-value=0, base-type=BT_PTC_SW, compu {phys=raw for raw 0..15; unit Unit_None}, range phys 0..15 Unit_None, raw 0..15, unit=Unit_None, transfer-property=PENDING, to Klima(timeout 3.5 s)  # PTC Software Version
            signal PTC_UBatt_XIX_PTCs_01_XIX_Klima_LIN1: start 32, 8 bit, little-endian, data-type-policy=OVERRIDE, i-signal-type=PRIMITIVE, init-value=254, base-type=BT_PTC_UBatt, invalid-value=Invalid_PTC_UBatt_XIX_PTCs_01_XIX_Klima_LIN1:255, compu {phys=raw*0.1 for raw 0..253, 254=Cxfe_Init (CM_PTC_UBatt_Cxfe_Init), 255=Cxff_Fehler (CM_PTC_UBatt_Cxff_Fehler); unit Unit_Volt}, range phys 0..25.3 Unit_Volt, raw 0..255, unit=Unit_Volt, transfer-property=PENDING, to Klima(timeout 3.5 s)  # Gemessene Batteriespannung
            signal PTC_Temp_PCB_XIX_PTCs_01_XIX_Klima_LIN1: start 40, 8 bit, little-endian, data-type-policy=OVERRIDE, i-signal-type=PRIMITIVE, init-value=254, base-type=BT_PTC_Temp_PCB, invalid-value=Invalid_PTC_Temp_PCB_XIX_PTCs_01_XIX_Klima_LIN1:255, compu {phys=raw-50 for raw 0..200, 254=Cxfe_Init (CM_PTC_Temp_PCB_Cxfe_Init), 255=Cxff_Fehler (CM_PTC_Temp_PCB_Cxff_Fehler); unit Unit_DegreCelsi}, range phys -50..150 Unit_DegreCelsi, raw 0..255, unit=Unit_DegreCelsi, transfer-property=PENDING, to Klima(timeout 3.5 s)  # Temperatur der PTC Ekektronik und der Platine (PCB)
        frame SlaveResp_XIX_Klima_LIN1: id 0x3D, to Klima, frame-length=8, lin-checksum=CLASSIC
          n pdu SlaveResp_XIX_Klima_LIN1: length=8
        frame UIFe_01_XIX_Klima_LIN1: id 0x36, from Klima, frame-length=8, lin-checksum=ENHANCED
          pdu UIFe_01_XIX_Klima_LIN1: length=8, unused-bit-pattern=0
            signal KL_SoSe_Intensitaet_FS_XIX_UIFe_01_XIX_Klima_LIN1: start 0, 6 bit, little-endian, data-type-policy=OVERRIDE, i-signal-type=PRIMITIVE, init-value=62, base-type=BT_KL_SoSe_Intensitaet_FS, invalid-value=Invalid_KL_SoSe_Intensitaet_FS_XIX_UIFe_01_XIX_Klima_LIN1:63, compu {phys=raw*20 for raw 0..60, 62=Cx3e_init (CM_KL_SoSe_Intensitaet_FS_Cx3e_init), 63=Cx3f_Fehler (CM_KL_SoSe_Intensitaet_FS_Cx3f_Fehler); unit Unit_WattPerMeterSquar}, range phys 0..1200 Unit_WattPerMeterSquar, raw 0..63, unit=Unit_WattPerMeterSquar, transfer-property=PENDING  # Sonnenintensität Fahrerseite wird vom Klima-SG aus dem SoSe-CAN-Signal generiert
            signal ZV_FT_offen_XIX_UIFe_01_XIX_Klima_LIN1: start 6, 1 bit, little-endian, data-type-policy=OVERRIDE, i-signal-type=PRIMITIVE, init-value=0, base-type=BT_ZV_FT_offen, compu {0=Cx0_FT_geschlossen (CM_ZV_FT_offen_Cx0_FT_geschlossen), 1=Cx1_FT_geoeffnet (CM_ZV_FT_offen_Cx1_FT_geoeffnet)}, range raw 0..1, transfer-property=PENDING  # gespiegeltes Bit FT_Tuer_geoeffnet TSG_FT_1 Botschaft
            signal ZV_BT_offen_XIX_UIFe_01_XIX_Klima_LIN1: start 7, 1 bit, little-endian, data-type-policy=OVERRIDE, i-signal-type=PRIMITIVE, init-value=0, base-type=BT_ZV_BT_offen, compu {0=Cx0_BT_geschlossen (CM_ZV_BT_offen_Cx0_BT_geschlossen), 1=Cx1_BT_geoeffnet (CM_ZV_BT_offen_Cx1_BT_geoeffnet)}, range raw 0..1, transfer-property=PENDING  # gespiegeltes Bit BT_Tuer_geoeffnet TSG_BT_1 Botschaft
            signal KL_SoSe_Intensitaet_BFS_XIX_UIFe_01_XIX_Klima_LIN1: start 8, 6 bit, little-endian, data-type-policy=OVERRIDE, i-signal-type=PRIMITIVE, init-value=62, base-type=BT_KL_SoSe_Intensitaet_BFS, invalid-value=Invalid_KL_SoSe_Intensitaet_BFS_XIX_UIFe_01_XIX_Klima_LIN1:63, compu {phys=raw*20 for raw 0..60, 62=Cx3e_init (CM_KL_SoSe_Intensitaet_BFS_Cx3e_init), 63=Cx3f_Fehler (CM_KL_SoSe_Intensitaet_BFS_Cx3f_Fehler); unit Unit_WattPerMeterSquar}, range phys 0..1200 Unit_WattPerMeterSquar, raw 0..63, unit=Unit_WattPerMeterSquar, transfer-property=PENDING  # Sonnenintensität Beifahrerseite wird vom Klima-SG aus dem SoSe-CAN-Signal generiert
            signal ZV_HFS_offen_XIX_UIFe_01_XIX_Klima_LIN1: start 14, 1 bit, little-endian, data-type-policy=OVERRIDE, i-signal-type=PRIMITIVE, init-value=0, base-type=BT_ZV_HFS_offen, compu {0=Cx0_geschlossen (CM_ZV_HFS_offen_Cx0_geschlossen), 1=Cx1_offen (CM_ZV_HFS_offen_Cx1_offen)}, range raw 0..1, transfer-property=PENDING  # gespiegeltes Bit HFS_Tuer_geoeffnet TSG_HFS_1 Botschaft
            signal ZV_HBFS_offen_XIX_UIFe_01_XIX_Klima_LIN1: start 15, 1 bit, little-endian, data-type-policy=OVERRIDE, i-signal-type=PRIMITIVE, init-value=0, base-type=BT_ZV_HBFS_offen, compu {0=Cx0_geschlossen (CM_ZV_HBFS_offen_Cx0_geschlossen), 1=Cx1_offen (CM_ZV_HBFS_offen_Cx1_offen)}, range raw 0..1, transfer-property=PENDING  # gespiegeltes Bit HBFS_Tuer_geoeffnet TSG_HBFS_1 Botschaft
            signal FT_FH_Oeffnung_4Bit_XIX_UIFe_01_XIX_Klima_LIN1: start 16, 4 bit, little-endian, data-type-policy=OVERRIDE, i-signal-type=PRIMITIVE, init-value=14, base-type=BT_FT_FH_Oeffnung_4Bit, invalid-value=Invalid_FT_FH_Oeffnung_4Bit_XIX_UIFe_01_XIX_Klima_LIN1:15, compu {phys=raw*10 for raw 0..10, 14=Cxe_Init (CM_FT_FH_Oeffnung_4Bit_Cxe_Init), 15=Cxf_Fehler (CM_FT_FH_Oeffnung_4Bit_Cxf_Fehler); unit Unit_PerCent}, range phys 0..100 Unit_PerCent, raw 0..15, unit=Unit_PerCent, transfer-property=PENDING  # Fensteröffnung FT
            signal BT_FH_Oeffnung_4Bit_XIX_UIFe_01_XIX_Klima_LIN1: start 20, 4 bit, little-endian, data-type-policy=OVERRIDE, i-signal-type=PRIMITIVE, init-value=14, base-type=BT_BT_FH_Oeffnung_4Bit, invalid-value=Invalid_BT_FH_Oeffnung_4Bit_XIX_UIFe_01_XIX_Klima_LIN1:15, compu {phys=raw*10 for raw 0..10, 14=Cxe_Init (CM_BT_FH_Oeffnung_4Bit_Cxe_Init), 15=Cxf_Fehler (CM_BT_FH_Oeffnung_4Bit_Cxf_Fehler); unit Unit_PerCent}, range phys 0..100 Unit_PerCent, raw 0..15, unit=Unit_PerCent, transfer-property=PENDING  # Fenster BFT Öffnung
            signal HFS_FH_Oeffnung_4Bit_XIX_UIFe_01_XIX_Klima_LIN1: start 24, 4 bit, little-endian, data-type-policy=OVERRIDE, i-signal-type=PRIMITIVE, init-value=14, base-type=BT_HFS_FH_Oeffnung_4Bit, invalid-value=Invalid_HFS_FH_Oeffnung_4Bit_XIX_UIFe_01_XIX_Klima_LIN1:15, compu {phys=raw*10 for raw 0..10, 14=Cxe_Init (CM_HFS_FH_Oeffnung_4Bit_Cxe_Init), 15=Cxf_Fehler (CM_HFS_FH_Oeffnung_4Bit_Cxf_Fehler); unit Unit_PerCent}, range phys 0..100 Unit_PerCent, raw 0..15, unit=Unit_PerCent, transfer-property=PENDING  # Fensteröffnung FT hinten
            signal HBFS_FH_Oeffnung_4Bit_XIX_UIFe_01_XIX_Klima_LIN1: start 28, 4 bit, little-endian, data-type-policy=OVERRIDE, i-signal-type=PRIMITIVE, init-value=14, base-type=BT_HBFS_FH_Oeffnung_4Bit, invalid-value=Invalid_HBFS_FH_Oeffnung_4Bit_XIX_UIFe_01_XIX_Klima_LIN1:15, compu {phys=raw*10 for raw 0..10, 14=Cxe_Init (CM_HBFS_FH_Oeffnung_4Bit_Cxe_Init), 15=Cxf_Fehler (CM_HBFS_FH_Oeffnung_4Bit_Cxf_Fehler); unit Unit_PerCent}, range phys 0..100 Unit_PerCent, raw 0..15, unit=Unit_PerCent, transfer-property=PENDING  # Fensteröffnung BFT hinten
            signal MD1_Position_4Bit_XIX_UIFe_01_XIX_Klima_LIN1: start 32, 4 bit, little-endian, data-type-policy=OVERRIDE, i-signal-type=PRIMITIVE, init-value=14, base-type=BT_MD1_Position_4Bit, invalid-value=Invalid_MD1_Position_4Bit_XIX_UIFe_01_XIX_Klima_LIN1:15, compu {phys=raw*10 for raw 0..10, 14=Cxe_Init (CM_MD1_Position_4Bit_Cxe_Init), 15=Cxf_Fehler (CM_MD1_Position_4Bit_Cxf_Fehler); unit Unit_PerCent}, range phys 0..100 Unit_PerCent, raw 0..15, unit=Unit_PerCent, transfer-property=PENDING  # Öffnungsposition des SAD
            signal MRollo_Position_4Bit_XIX_UIFe_01_XIX_Klima_LIN1: start 36, 4 bit, little-endian, data-type-policy=OVERRIDE, i-signal-type=PRIMITIVE, init-value=14, base-type=BT_MRollo_Position_4Bit, invalid-value=Invalid_MRollo_Position_4Bit_XIX_UIFe_01_XIX_Klima_LIN1:15, compu {phys=raw*10 for raw 0..10, 14=Cxe_Init (CM_MRollo_Position_4Bit_Cxe_Init), 15=Cxf_Fehler (CM_MRollo_Position_4Bit_Cxf_Fehler); unit Unit_PerCent}, range phys 0..100 Unit_PerCent, raw 0..15, unit=Unit_PerCent, transfer-property=PENDING  # Position Dachrollo
            signal KL_Scheibe_Typ_XIX_UIFe_01_XIX_Klima_LIN1: start 40, 3 bit, little-endian, data-type-policy=OVERRIDE, i-signal-type=PRIMITIVE, base-type=BT_KL_Scheibe_Typ, compu {0=Cx0_Gruenglas_Waermeschutzglas (CM_KL_Scheibe_Typ_Cx0_Gruenglas_Waermeschutzglas), 1=Cx1_Klimakomfortscheibe_Daemmglas (CM_KL_Scheibe_Typ_Cx1_Klimakomfortscheibe_Daemmglas), 2=Cx2_Scheibe_3 (CM_KL_Scheibe_Typ_Cx2_Scheibe_3), 3=Cx3_Scheibe_4 (CM_KL_Scheibe_Typ_Cx3_Scheibe_4), 4=Cx4_Scheibe_5 (CM_KL_Scheibe_Typ_Cx4_Scheibe_5)}, range raw 0..4, transfer-property=PENDING  # Typ der Verglasung
            signal KL_UIF_Parametersatz_XIX_UIFe_01_XIX_Klima_LIN1: start 43, 3 bit, little-endian, data-type-policy=OVERRIDE, i-signal-type=PRIMITIVE, base-type=BT_KL_UIF_Parametersatz, compu {0=Cx0_Parametersatz_0 (CM_KL_UIF_Parametersatz_Cx0_Parametersatz_0), 1=Cx1_Parametersatz_1 (CM_KL_UIF_Parametersatz_Cx1_Parametersatz_1), 2=Cx2_Parametersatz_2 (CM_KL_UIF_Parametersatz_Cx2_Parametersatz_2), 3=Cx3_Parametersatz_3 (CM_KL_UIF_Parametersatz_Cx3_Parametersatz_3), 4=Cx4_Parametersatz_4 (CM_KL_UIF_Parametersatz_Cx4_Parametersatz_4), 5=Cx5_Parametersatz_5 (CM_KL_UIF_Parametersatz_Cx5_Parametersatz_5), 6=Cx6_Parametersatz_6 (CM_KL_UIF_Parametersatz_Cx6_Parametersatz_6), 7=Cx7_Parametersatz_7 (CM_KL_UIF_Parametersatz_Cx7_Parametersatz_7)}, range raw 0..7, transfer-property=PENDING  # Parametersatz des UIF
            signal MD1_Lage_XIX_UIFe_01_XIX_Klima_LIN1: start 46, 1 bit, little-endian, data-type-policy=OVERRIDE, i-signal-type=PRIMITIVE, init-value=0, base-type=BT_MD1_Lage, compu {0=Cx0_Ausstelllage (CM_MD1_Lage_Cx0_Ausstelllage), 1=Cx1_Schiebelage (CM_MD1_Lage_Cx1_Schiebelage)}, range raw 0..1, transfer-property=PENDING  # Lage Schiebedachstellung 1 (Signal wird 1:1 vom BCM2 geroutet; ursprünglicher Sender: SAD = LIN-Slave vom BCM2)
            signal MRollo_Lage_XIX_UIFe_01_XIX_Klima_LIN1: start 47, 1 bit, little-endian, data-type-policy=OVERRIDE, i-signal-type=PRIMITIVE, init-value=0, base-type=BT_MRollo_Lage, compu {0=Cx0_Ausstelllage (CM_MRollo_Lage_Cx0_Ausstelllage), 1=Cx1_Schiebelage (CM_MRollo_Lage_Cx1_Schiebelage)}, range raw 0..1, transfer-property=PENDING  # Lage Rollo (Signal wird 1:1 vom BCM2 geroutet; ursprünglicher Sender: Rollo = LIN-Slave vom BCM2)
            signal KL_Klimastandzeit_XIX_UIFe_01_XIX_Klima_LIN1: start 48, 12 bit, little-endian, data-type-policy=OVERRIDE, i-signal-type=PRIMITIVE, init-value=4094, base-type=BT_KL_Klimastandzeit, invalid-value=Invalid_KL_Klimastandzeit_XIX_UIFe_01_XIX_Klima_LIN1:4095, compu {phys=raw for raw 0..4093, 4094=Cxffe_Init (CM_KL_Klimastandzeit_Cxffe_Init), 4095=Cxfff_Fehler (CM_KL_Klimastandzeit_Cxfff_Fehler); unit Unit_Minut}, range phys 0..4093 Unit_Minut, raw 0..4095, unit=Unit_Minut, transfer-property=PENDING  # vom Klimasteuergerät aufbereitete Standzeit des Klimasystems; benötigt vom externen UIF
            signal KL_Verdeckstatus_XIX_UIFe_01_XIX_Klima_LIN1: start 60, 1 bit, little-endian, data-type-policy=OVERRIDE, i-signal-type=PRIMITIVE, init-value=0, base-type=BT_KL_Verdeckstatus, compu {0=Cx0_geschlossen (CM_KL_Verdeckstatus_Cx0_geschlossen), 1=Cx1_offen (CM_KL_Verdeckstatus_Cx1_offen)}, range raw 0..1, transfer-property=PENDING  # Verdeckstatus (aufbereitet durch Klima-SG)
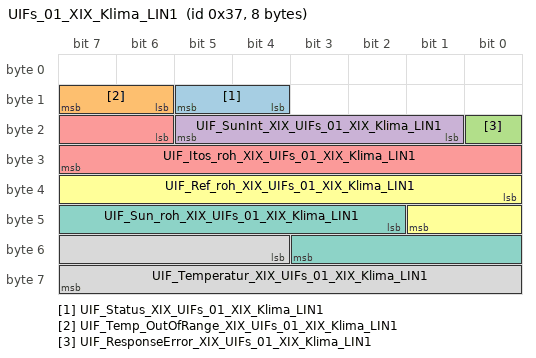
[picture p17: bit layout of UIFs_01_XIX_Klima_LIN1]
        frame UIFs_01_XIX_Klima_LIN1: id 0x37, to Klima, frame-length=8, lin-checksum=ENHANCED
          pdu UIFs_01_XIX_Klima_LIN1: length=8, unused-bit-pattern=0
            signal UIF_Status_XIX_UIFs_01_XIX_Klima_LIN1: start 12, 2 bit, little-endian, data-type-policy=OVERRIDE, i-signal-type=PRIMITIVE, init-value=2, base-type=BT_UIF_Status, compu {0=Cx0_Sensor_Status_TC_TP (CM_UIF_Status_Cx0_Sensor_Status_TC_TP), 1=Cx1_Sensor_Status_TC (CM_UIF_Status_Cx1_Sensor_Status_TC), 2=Cx2_Sensor_Status_TNCTOC (CM_UIF_Status_Cx2_Sensor_Status_TNCTOC)}, range raw 0..2, transfer-property=PENDING, to Klima(timeout 3.5 s)  # Status UIF
            signal UIF_Temp_OutOfRange_XIX_UIFs_01_XIX_Klima_LIN1: start 14, 2 bit, little-endian, data-type-policy=OVERRIDE, i-signal-type=PRIMITIVE, init-value=0, base-type=BT_UIF_Temp_OutOfRange, compu {0=Cx0_Temp_Value_in_Range (CM_UIF_Temp_OutOfRange_Cx0_Temp_Value_in_Range), 1=Cx1_Temp_Out_Of_Range_LOW (CM_UIF_Temp_OutOfRange_Cx1_Temp_Out_Of_Range_LOW), 2=Cx2_Temp_Out_Of_Range_HIGH (CM_UIF_Temp_OutOfRange_Cx2_Temp_Out_Of_Range_HIGH)}, range raw 0..2, transfer-property=PENDING, to Klima(timeout 3.5 s)  # Out Of Range UIF
            signal UIF_ResponseError_XIX_UIFs_01_XIX_Klima_LIN1: start 16, 1 bit, little-endian, data-type-policy=OVERRIDE, i-signal-type=PRIMITIVE, init-value=0, base-type=BT_UIF_ResponseError, invalid-value=Invalid_UIF_ResponseError_XIX_UIFs_01_XIX_Klima_LIN1:1, compu {0=Cx0_normal (CM_UIF_ResponseError_Cx0_normal), 1=Cx1_Fehler (CM_UIF_ResponseError_Cx1_Fehler)}, range raw 0..1, transfer-property=PENDING, to Klima(timeout 3.5 s)  # siehe LIN2.0-Specification (Darf nicht über ein Fehlergueltigkeitsbit abgesichtert werden!)
            signal UIF_SunInt_XIX_UIFs_01_XIX_Klima_LIN1: start 17, 5 bit, little-endian, data-type-policy=OVERRIDE, i-signal-type=PRIMITIVE, init-value=30, base-type=BT_UIF_SunInt, invalid-value=Invalid_UIF_SunInt_XIX_UIFs_01_XIX_Klima_LIN1:31, compu {phys=raw*50 for raw 0..24, 30=Cx1e_Init (CM_UIF_SunInt_Cx1e_Init), 31=Cx1f_Fehler (CM_UIF_SunInt_Cx1f_Fehler); unit Unit_WattPerMeterSquar}, range phys 0..1200 Unit_WattPerMeterSquar, raw 0..31, unit=Unit_WattPerMeterSquar, transfer-property=PENDING, to Klima(timeout 3.5 s)  # Sonnenintensität
            signal UIF_Itos_roh_XIX_UIFs_01_XIX_Klima_LIN1: start 22, 10 bit, little-endian, data-type-policy=OVERRIDE, i-signal-type=PRIMITIVE, base-type=BT_UIF_Itos_roh, compu {phys=raw for raw 0..1023}, range phys 0..1023, raw 0..1023, transfer-property=PENDING, to Klima(timeout 3.5 s)  # Rohwert UIF1
            signal UIF_Ref_roh_XIX_UIFs_01_XIX_Klima_LIN1: start 32, 10 bit, little-endian, data-type-policy=OVERRIDE, i-signal-type=PRIMITIVE, base-type=BT_UIF_Ref_roh, compu {phys=raw for raw 0..1023}, range phys 0..1023, raw 0..1023, transfer-property=PENDING, to Klima(timeout 3.5 s)  # Rohwert UIF2
            signal UIF_Sun_roh_XIX_UIFs_01_XIX_Klima_LIN1: start 42, 10 bit, little-endian, data-type-policy=OVERRIDE, i-signal-type=PRIMITIVE, base-type=BT_UIF_Sun_roh, compu {phys=raw for raw 0..1023}, range phys 0..1023, raw 0..1023, transfer-property=PENDING, to Klima(timeout 3.5 s)  # Rohwert Sonne
            signal UIF_Temperatur_XIX_UIFs_01_XIX_Klima_LIN1: start 52, 12 bit, little-endian, data-type-policy=OVERRIDE, i-signal-type=PRIMITIVE, init-value=4094, base-type=BT_UIF_Temperatur, invalid-value=Invalid_UIF_Temperatur_XIX_UIFs_01_XIX_Klima_LIN1:4095, compu {phys=raw*0.1-80 for raw 0..1800, 4094=Cxffe_Init (CM_UIF_Temperatur_Cxffe_Init), 4095=Cxfff_Fehler (CM_UIF_Temperatur_Cxfff_Fehler); unit Unit_DegreCelsi}, range phys -80..100 Unit_DegreCelsi, raw 0..4095, unit=Unit_DegreCelsi, transfer-property=PENDING, to Klima(timeout 3.5 s)  # Temperatur UIF
        pdu triggering PT_Klima_LIN1_XIX_TPCHType_LIN_Diagnose_XIX_0x0_XIX_0x1A_XIX_Physical: pdu=DCM_Klima_LIN1_XIX_TPCHType_LIN_Diagnose_XIX_0x0_XIX_0x1A_XIX_Physical, from Klima
        pdu triggering PT_Klima_LIN1_XIX_TPCHType_LIN_Diagnose_XIX_0x0_XIX_0x40_XIX_Physical: pdu=DCM_Klima_LIN1_XIX_TPCHType_LIN_Diagnose_XIX_0x0_XIX_0x40_XIX_Physical, from Klima
        pdu triggering PT_Klima_LIN1_XIX_TPCHType_LIN_Diagnose_XIX_0x0_XIX_0x43_XIX_Physical: pdu=DCM_Klima_LIN1_XIX_TPCHType_LIN_Diagnose_XIX_0x0_XIX_0x43_XIX_Physical, from Klima
        pdu triggering PT_Klima_LIN1_XIX_TPCHType_LIN_Diagnose_XIX_0x0_XIX_0x50_XIX_Physical: pdu=DCM_Klima_LIN1_XIX_TPCHType_LIN_Diagnose_XIX_0x0_XIX_0x50_XIX_Physical, from Klima
        pdu triggering PT_Klima_LIN1_XIX_TPCHType_LIN_Diagnose_XIX_0x0_XIX_0x64_XIX_Physical: pdu=DCM_Klima_LIN1_XIX_TPCHType_LIN_Diagnose_XIX_0x0_XIX_0x64_XIX_Physical, from Klima
        pdu triggering PT_Klima_LIN1_XIX_TPCHType_LIN_Diagnose_XIX_0x0_XIX_0xA_XIX_Physical: pdu=DCM_Klima_LIN1_XIX_TPCHType_LIN_Diagnose_XIX_0x0_XIX_0xA_XIX_Physical, from Klima
        pdu triggering PT_Klima_LIN1_XIX_TPCHType_LIN_Diagnose_XIX_0x1A_XIX_0x0_XIX_Physical: pdu=DCM_Klima_LIN1_XIX_TPCHType_LIN_Diagnose_XIX_0x1A_XIX_0x0_XIX_Physical, to Klima
        pdu triggering PT_Klima_LIN1_XIX_TPCHType_LIN_Diagnose_XIX_0x40_XIX_0x0_XIX_Physical: pdu=DCM_Klima_LIN1_XIX_TPCHType_LIN_Diagnose_XIX_0x40_XIX_0x0_XIX_Physical, to Klima
        pdu triggering PT_Klima_LIN1_XIX_TPCHType_LIN_Diagnose_XIX_0x43_XIX_0x0_XIX_Physical: pdu=DCM_Klima_LIN1_XIX_TPCHType_LIN_Diagnose_XIX_0x43_XIX_0x0_XIX_Physical, to Klima
        pdu triggering PT_Klima_LIN1_XIX_TPCHType_LIN_Diagnose_XIX_0x50_XIX_0x0_XIX_Physical: pdu=DCM_Klima_LIN1_XIX_TPCHType_LIN_Diagnose_XIX_0x50_XIX_0x0_XIX_Physical, to Klima
        pdu triggering PT_Klima_LIN1_XIX_TPCHType_LIN_Diagnose_XIX_0x64_XIX_0x0_XIX_Physical: pdu=DCM_Klima_LIN1_XIX_TPCHType_LIN_Diagnose_XIX_0x64_XIX_0x0_XIX_Physical, to Klima
        pdu triggering PT_Klima_LIN1_XIX_TPCHType_LIN_Diagnose_XIX_0xA_XIX_0x0_XIX_Physical: pdu=DCM_Klima_LIN1_XIX_TPCHType_LIN_Diagnose_XIX_0xA_XIX_0x0_XIX_Physical, to Klima
        6 x lin schedule table, all with resume-position=CONTINUE-AT-IT-POSITION:
          DiagRequest: run-mode=RUN-ONCE, application-entry{delay=0.01, position-in-table=0, frame-triggering=CHNL/FT_MasterReq}
          DiagResponse: run-mode=RUN-ONCE, application-entry{delay=0.01, position-in-table=0, frame-triggering=CHNL/FT_SlaveResp}
          st_main_1: run-mode=RUN-CONTINUOUS
            table-entrys:
              delay=0.01, position-in-table=0, frame-triggering=FT_PMSe_01
              delay=0.02, position-in-table=1, frame-triggering=FT_PTCe_01
              delay=0.01, position-in-table=2, frame-triggering=FT_BLOWER2_SET
              delay=0.03, position-in-table=3, frame-triggering=FT_AQSe_01
              delay=0.02, position-in-table=4, frame-triggering=FT_ICO2be_01
              delay=0.03, position-in-table=5, frame-triggering=FT_PTCs_01
              delay=0.03, position-in-table=6, frame-triggering=FT_UIFe_01
              delay=0.01, position-in-table=7, frame-triggering=FT_BLOWER1_SET
              delay=0.01, position-in-table=8, frame-triggering=FT_PMS1s_01
              delay=0.02, position-in-table=9, frame-triggering=FT_PTCe_01
              delay=0.01, position-in-table=10, frame-triggering=FT_BLOWER2_STATUS
              delay=0.03, position-in-table=11, frame-triggering=FT_AQSs_01
              delay=0.02, position-in-table=12, frame-triggering=FT_ICO2bs_01
              delay=0.03, position-in-table=13, frame-triggering=FT_PTCs_01
              delay=0.03, position-in-table=14, frame-triggering=FT_UIFs_01
              delay=0.01, position-in-table=15, frame-triggering=FT_BLOWER1_STATUS
          st_main_2: run-mode=RUN-CONTINUOUS
            table-entrys:
              delay=0.01, position-in-table=0, frame-triggering=FT_PMSe_01
              delay=0.01, position-in-table=1, frame-triggering=FT_KPVe_01
              delay=0.02, position-in-table=2, frame-triggering=FT_KPVe_02
              delay=0.01, position-in-table=3, frame-triggering=FT_AQSe_01
              delay=0.01, position-in-table=4, frame-triggering=FT_KPVs_01
              delay=0.01, position-in-table=5, frame-triggering=FT_KPVs_02
              delay=0.01, position-in-table=6, frame-triggering=FT_ICO2be_01
              delay=0.01, position-in-table=7, frame-triggering=FT_FSAe_01
              delay=0.01, position-in-table=8, frame-triggering=FT_KPVe_01
              delay=0.02, position-in-table=9, frame-triggering=FT_KPVe_02
              delay=0.01, position-in-table=10, frame-triggering=FT_UIFe_01
              delay=0.01, position-in-table=11, frame-triggering=FT_KPVs_01
              delay=0.01, position-in-table=12, frame-triggering=FT_KPVs_02
              delay=0.01, position-in-table=13, frame-triggering=FT_BLOWER1_SET
              delay=0.01, position-in-table=14, frame-triggering=FT_PMS1s_01
              delay=0.01, position-in-table=15, frame-triggering=FT_KPVe_01
              delay=0.02, position-in-table=16, frame-triggering=FT_KPVe_02
              delay=0.01, position-in-table=17, frame-triggering=FT_AQSs_01
              delay=0.01, position-in-table=18, frame-triggering=FT_KPVs_01
              delay=0.01, position-in-table=19, frame-triggering=FT_KPVs_02
              delay=0.01, position-in-table=20, frame-triggering=FT_ICO2bs_01
              delay=0.01, position-in-table=21, frame-triggering=FT_FSAs_01
              delay=0.01, position-in-table=22, frame-triggering=FT_KPVe_01
              delay=0.02, position-in-table=23, frame-triggering=FT_KPVe_02
              delay=0.01, position-in-table=24, frame-triggering=FT_UIFs_01
              delay=0.01, position-in-table=25, frame-triggering=FT_KPVs_01
              delay=0.01, position-in-table=26, frame-triggering=FT_KPVs_02
              delay=0.01, position-in-table=27, frame-triggering=FT_BLOWER1_STATUS
          st_main_3: run-mode=RUN-CONTINUOUS
            table-entrys:
              delay=0.01, position-in-table=0, frame-triggering=FT_PMSe_01
              delay=0.01, position-in-table=1, frame-triggering=FT_KPVe_01
              delay=0.02, position-in-table=2, frame-triggering=FT_KPVe_02
              delay=0.01, position-in-table=3, frame-triggering=FT_AQSe_01
              delay=0.01, position-in-table=4, frame-triggering=FT_KPVs_01
              delay=0.01, position-in-table=5, frame-triggering=FT_KPVs_02
              delay=0.01, position-in-table=6, frame-triggering=FT_ICO2be_01
              delay=0.01, position-in-table=7, frame-triggering=FT_FSAe_01
              delay=0.01, position-in-table=8, frame-triggering=FT_KPVe_01
              delay=0.02, position-in-table=9, frame-triggering=FT_KPVe_02
              delay=0.01, position-in-table=10, frame-triggering=FT_UIFe_01
              delay=0.01, position-in-table=11, frame-triggering=FT_KPVs_01
              delay=0.02, position-in-table=12, frame-triggering=FT_KPVs_02
              delay=0.01, position-in-table=13, frame-triggering=FT_PMS1s_01
              delay=0.01, position-in-table=14, frame-triggering=FT_KPVe_01
              delay=0.02, position-in-table=15, frame-triggering=FT_KPVe_02
              delay=0.01, position-in-table=16, frame-triggering=FT_AQSs_01
              delay=0.01, position-in-table=17, frame-triggering=FT_KPVs_01
              delay=0.01, position-in-table=18, frame-triggering=FT_KPVs_02
              delay=0.01, position-in-table=19, frame-triggering=FT_ICO2bs_01
              delay=0.01, position-in-table=20, frame-triggering=FT_FSAs_01
              delay=0.01, position-in-table=21, frame-triggering=FT_KPVe_01
              delay=0.02, position-in-table=22, frame-triggering=FT_KPVe_02
              delay=0.01, position-in-table=23, frame-triggering=FT_UIFs_01
              delay=0.01, position-in-table=24, frame-triggering=FT_KPVs_01
              delay=0.02, position-in-table=25, frame-triggering=FT_KPVs_02
          st_main_4: run-mode=RUN-CONTINUOUS
            table-entrys:
              delay=0.01, position-in-table=0, frame-triggering=FT_PMSe_01
              delay=0.01, position-in-table=1, frame-triggering=FT_KPVe_01
              delay=0.01, position-in-table=2, frame-triggering=FT_KPVe_02
              delay=0.01, position-in-table=3, frame-triggering=FT_KBFe_01
              delay=0.01, position-in-table=4, frame-triggering=FT_AQSe_01
              delay=0.01, position-in-table=5, frame-triggering=FT_KPVs_01
              delay=0.01, position-in-table=6, frame-triggering=FT_KPVs_02
              delay=0.01, position-in-table=7, frame-triggering=FT_KBFe_02
              delay=0.01, position-in-table=8, frame-triggering=FT_FSAe_01
              delay=0.01, position-in-table=9, frame-triggering=FT_KPVe_01
              delay=0.01, position-in-table=10, frame-triggering=FT_KPVe_02
              delay=0.01, position-in-table=11, frame-triggering=FT_KBFs_01
              delay=0.01, position-in-table=12, frame-triggering=FT_UIFe_01
              delay=0.01, position-in-table=13, frame-triggering=FT_KPVs_01
              delay=0.01, position-in-table=14, frame-triggering=FT_KPVs_02
              delay=0.01, position-in-table=15, frame-triggering=FT_KBFs_02
              delay=0.01, position-in-table=16, frame-triggering=FT_PMS1s_01
              delay=0.01, position-in-table=17, frame-triggering=FT_KPVe_01
              delay=0.01, position-in-table=18, frame-triggering=FT_KPVe_02
              delay=0.01, position-in-table=19, frame-triggering=FT_KBFe_01
              delay=0.01, position-in-table=20, frame-triggering=FT_AQSs_01
              delay=0.01, position-in-table=21, frame-triggering=FT_KPVs_01
              delay=0.01, position-in-table=22, frame-triggering=FT_KPVs_02
              delay=0.01, position-in-table=23, frame-triggering=FT_KBFe_02
              delay=0.01, position-in-table=24, frame-triggering=FT_FSAs_01
              delay=0.01, position-in-table=25, frame-triggering=FT_KPVe_01
              delay=0.01, position-in-table=26, frame-triggering=FT_KPVe_02
              delay=0.01, position-in-table=27, frame-triggering=FT_KBFs_01
              delay=0.01, position-in-table=28, frame-triggering=FT_UIFs_01
              delay=0.01, position-in-table=29, frame-triggering=FT_KPVs_01
              delay=0.01, position-in-table=30, frame-triggering=FT_KPVs_02
              delay=0.01, position-in-table=31, frame-triggering=FT_KBFs_02
